VERSION "HNNBNNNYNNNNNNNNNNNNNNNNNNNNNNNNNNNNNNNNNN/4/%%%/4/'%**4NNN///"

NS_ :

BS_:

BU_: Aero_LB AFS_MLB Airbag_B8 BCM1_B8 Gateway_B8 Getriebe_AL551_651_B8 Getriebe_AL551_Q5_Hybrid Getriebe_SL_LB Lift_MLB_LB LWR_MLB Magnetic_Ride_LB Motor_MLB_AU48_AU416_Diesel Motor_MLB_B8_Q5_Otto Motor_MLB_Q5_Hybrid Niveau_LB Airbag_D4 BMS_Hybrid Daempfer_MLB EPB_MLB ESP Gateway Getriebe_AL551_951_D4_C7 Getriebe_AL551_Hybrid_D4_C7 Getriebe_DL382_MLB Getriebe_DL501_MLB Getriebe_VL381_MLB LEH_Hybrid LWS_D4 Motor2_MLB_D4_C7 Motor_MLB_AU64_AU57_Diesel Motor_MLB_BY_Otto Motor_MLB_C7_PHEV Motor_MLB_D4_C7_Hybrid Motor_MLB_D4_C7_Otto QSP SAK SAK2 SCR_MLB SCU

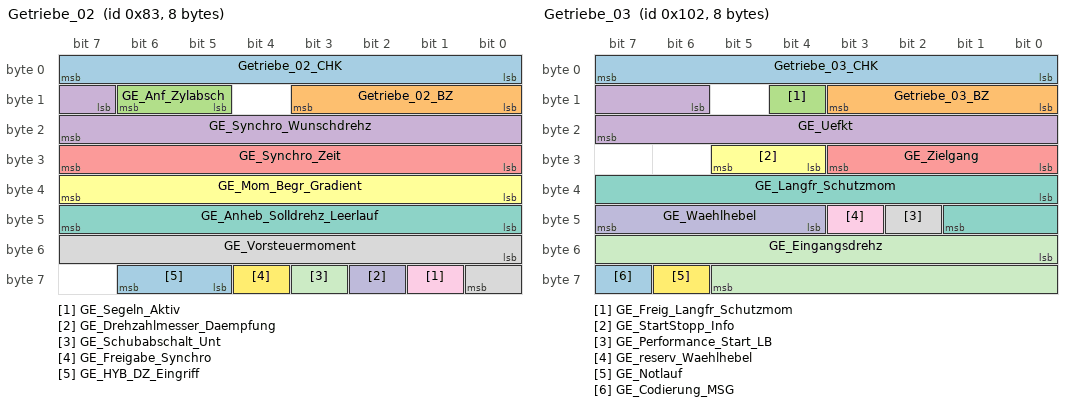
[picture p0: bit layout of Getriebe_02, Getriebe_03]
BO_ 131 Getriebe_02: 8 Getriebe_AL551_951_D4_C7
 SG_ Getriebe_02_CHK : 0|8@1+ (1,0) [0|255] ""  Motor_MLB_AU64_AU57_Diesel,Motor_MLB_BY_Otto,Motor_MLB_C7_PHEV,Motor_MLB_D4_C7_Hybrid,Motor_MLB_D4_C7_Otto
 SG_ Getriebe_02_BZ : 8|4@1+ (1,0) [0|15] ""  Motor_MLB_AU64_AU57_Diesel,Motor_MLB_BY_Otto,Motor_MLB_C7_PHEV,Motor_MLB_D4_C7_Hybrid,Motor_MLB_D4_C7_Otto
 SG_ GE_Anf_Zylabsch : 13|2@1+ (1,0) [0|3] ""  Motor_MLB_BY_Otto,Motor_MLB_C7_PHEV,Motor_MLB_D4_C7_Hybrid,Motor_MLB_D4_C7_Otto
 SG_ GE_Synchro_Wunschdrehz : 15|9@1+ (25,0) [25|12750] "Unit_MinutInver"  Motor_MLB_AU64_AU57_Diesel,Motor_MLB_BY_Otto,Motor_MLB_C7_PHEV,Motor_MLB_D4_C7_Hybrid,Motor_MLB_D4_C7_Otto
 SG_ GE_Synchro_Zeit : 24|8@1+ (20,0) [0|5080] "Unit_MilliSecon"  Motor_MLB_AU64_AU57_Diesel,Motor_MLB_BY_Otto,Motor_MLB_C7_PHEV,Motor_MLB_D4_C7_Hybrid,Motor_MLB_D4_C7_Otto
 SG_ GE_Mom_Begr_Gradient : 32|8@1+ (10,0) [0|2540] "Unit_NewtoMeterPerSecon"  Motor_MLB_AU64_AU57_Diesel,Motor_MLB_BY_Otto,Motor_MLB_C7_PHEV,Motor_MLB_D4_C7_Hybrid,Motor_MLB_D4_C7_Otto
 SG_ GE_Anheb_Solldrehz_Leerlauf : 40|8@1+ (10,0) [0|2540] "Unit_MinutInver"  Motor_MLB_AU64_AU57_Diesel,Motor_MLB_BY_Otto,Motor_MLB_C7_PHEV,Motor_MLB_D4_C7_Hybrid,Motor_MLB_D4_C7_Otto
 SG_ GE_Vorsteuermoment : 48|9@1+ (1,0) [0|509] ""  Motor_MLB_AU64_AU57_Diesel,Motor_MLB_BY_Otto,Motor_MLB_C7_PHEV,Motor_MLB_D4_C7_Hybrid,Motor_MLB_D4_C7_Otto
 SG_ GE_Segeln_Aktiv : 57|1@1+ (1,0) [0|1] ""  Gateway,Motor_MLB_AU64_AU57_Diesel,Motor_MLB_C7_PHEV,Motor_MLB_D4_C7_Hybrid,Motor_MLB_D4_C7_Otto
 SG_ GE_Drehzahlmesser_Daempfung : 58|1@1+ (1,0) [0|1] ""  Motor_MLB_AU64_AU57_Diesel,Motor_MLB_BY_Otto,Motor_MLB_C7_PHEV,Motor_MLB_D4_C7_Hybrid,Motor_MLB_D4_C7_Otto
 SG_ GE_Schubabschalt_Unt : 59|1@1+ (1,0) [0|1] ""  Motor_MLB_AU64_AU57_Diesel,Motor_MLB_BY_Otto,Motor_MLB_C7_PHEV,Motor_MLB_D4_C7_Hybrid,Motor_MLB_D4_C7_Otto
 SG_ GE_Freigabe_Synchro : 60|1@1+ (1,0) [0|1] ""  Motor_MLB_AU64_AU57_Diesel,Motor_MLB_BY_Otto,Motor_MLB_C7_PHEV,Motor_MLB_D4_C7_Hybrid,Motor_MLB_D4_C7_Otto
 SG_ GE_HYB_DZ_Eingriff : 61|2@1+ (1,0) [0|3] "" Vector__XXX

BO_ 258 Getriebe_03: 8 Getriebe_AL551_951_D4_C7
 SG_ Getriebe_03_CHK : 0|8@1+ (1,0) [0|255] ""  EPB_MLB,Gateway,Motor_MLB_AU64_AU57_Diesel,Motor_MLB_BY_Otto,Motor_MLB_C7_PHEV,Motor_MLB_D4_C7_Hybrid,Motor_MLB_D4_C7_Otto
 SG_ Getriebe_03_BZ : 8|4@1+ (1,0) [0|15] ""  EPB_MLB,Gateway,Motor_MLB_AU64_AU57_Diesel,Motor_MLB_BY_Otto,Motor_MLB_C7_PHEV,Motor_MLB_D4_C7_Hybrid,Motor_MLB_D4_C7_Otto
 SG_ GE_Freig_Langfr_Schutzmom : 12|1@1+ (1,0) [0|1] ""  Gateway,Motor_MLB_AU64_AU57_Diesel,Motor_MLB_BY_Otto,Motor_MLB_C7_PHEV,Motor_MLB_D4_C7_Hybrid,Motor_MLB_D4_C7_Otto
 SG_ GE_Uefkt : 14|10@1+ (0.1,0) [0|102.2] ""  EPB_MLB,Gateway,Motor_MLB_AU64_AU57_Diesel,Motor_MLB_BY_Otto,Motor_MLB_C7_PHEV,Motor_MLB_D4_C7_Hybrid,Motor_MLB_D4_C7_Otto
 SG_ GE_Zielgang : 24|4@1+ (1,0) [0|15] ""  Gateway,Motor_MLB_AU64_AU57_Diesel,Motor_MLB_BY_Otto,Motor_MLB_C7_PHEV,Motor_MLB_D4_C7_Hybrid,Motor_MLB_D4_C7_Otto
 SG_ GE_StartStopp_Info : 28|2@1+ (1,0) [0|3] ""  Gateway,Motor_MLB_AU64_AU57_Diesel,Motor_MLB_BY_Otto,Motor_MLB_C7_PHEV,Motor_MLB_D4_C7_Hybrid,Motor_MLB_D4_C7_Otto
 SG_ GE_Langfr_Schutzmom : 32|10@1+ (1,0) [0|1021] ""  Gateway,Motor_MLB_AU64_AU57_Diesel,Motor_MLB_BY_Otto,Motor_MLB_C7_PHEV,Motor_MLB_D4_C7_Hybrid,Motor_MLB_D4_C7_Otto
 SG_ GE_Performance_Start_LB : 42|1@1+ (1,0) [0|1] ""  Gateway
 SG_ GE_reserv_Waehlhebel : 43|1@1+ (1,0) [0|1] ""  Gateway
 SG_ GE_Waehlhebel : 44|4@1+ (1,0) [0|15] ""  EPB_MLB,Gateway,Motor_MLB_AU64_AU57_Diesel,Motor_MLB_BY_Otto,Motor_MLB_C7_PHEV,Motor_MLB_D4_C7_Hybrid,Motor_MLB_D4_C7_Otto
 SG_ GE_Eingangsdrehz : 48|14@1+ (1,0) [0|16381] "Unit_MinutInver"  Gateway,Motor_MLB_AU64_AU57_Diesel,Motor_MLB_BY_Otto,Motor_MLB_C7_PHEV,Motor_MLB_D4_C7_Hybrid,Motor_MLB_D4_C7_Otto
 SG_ GE_Notlauf : 62|1@1+ (1,0) [0|1] ""  Gateway,Motor_MLB_AU64_AU57_Diesel,Motor_MLB_BY_Otto,Motor_MLB_C7_PHEV,Motor_MLB_D4_C7_Hybrid,Motor_MLB_D4_C7_Otto
 SG_ GE_Codierung_MSG : 63|1@1+ (1,0) [0|1] ""  Gateway

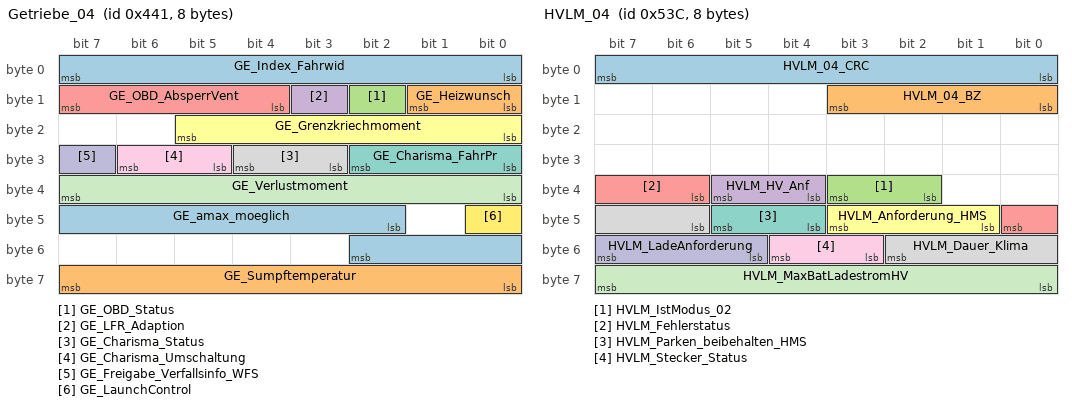
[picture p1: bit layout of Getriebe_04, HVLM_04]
BO_ 1089 Getriebe_04: 8 Getriebe_AL551_951_D4_C7
 SG_ GE_Index_Fahrwid : 0|8@1+ (0.249,-31.623) [-31.623|31.623] ""  Gateway,Motor_MLB_AU64_AU57_Diesel,Motor_MLB_BY_Otto,Motor_MLB_C7_PHEV,Motor_MLB_D4_C7_Hybrid,Motor_MLB_D4_C7_Otto
 SG_ GE_Heizwunsch : 8|2@1+ (1,0) [0|3] ""  Gateway
 SG_ GE_OBD_Status : 10|1@1+ (1,0) [0|1] ""  Gateway,Motor_MLB_AU64_AU57_Diesel,Motor_MLB_BY_Otto,Motor_MLB_C7_PHEV,Motor_MLB_D4_C7_Hybrid,Motor_MLB_D4_C7_Otto
 SG_ GE_LFR_Adaption : 11|1@1+ (1,0) [0|1] ""  Gateway,Motor_MLB_AU64_AU57_Diesel,Motor_MLB_BY_Otto,Motor_MLB_C7_PHEV,Motor_MLB_D4_C7_Hybrid,Motor_MLB_D4_C7_Otto
 SG_ GE_OBD_AbsperrVent : 12|4@1+ (1,0) [0|15] ""  Gateway
 SG_ GE_Grenzkriechmoment : 16|6@1+ (2,0) [0|122] ""  Gateway
 SG_ GE_Charisma_FahrPr : 24|3@1+ (1,0) [0|7] ""  Gateway
 SG_ GE_Charisma_Status : 27|2@1+ (1,0) [0|3] ""  Gateway
 SG_ GE_Charisma_Umschaltung : 29|2@1+ (1,0) [0|3] ""  Gateway
 SG_ GE_Freigabe_Verfallsinfo_WFS : 31|1@1+ (1,0) [0|1] ""  Gateway,Motor_MLB_AU64_AU57_Diesel,Motor_MLB_BY_Otto,Motor_MLB_C7_PHEV,Motor_MLB_D4_C7_Hybrid,Motor_MLB_D4_C7_Otto
 SG_ GE_Verlustmoment : 32|8@1+ (1,0) [0|254] ""  EPB_MLB,Gateway,Motor_MLB_AU64_AU57_Diesel,Motor_MLB_BY_Otto,Motor_MLB_C7_PHEV,Motor_MLB_D4_C7_Hybrid,Motor_MLB_D4_C7_Otto
 SG_ GE_LaunchControl : 40|1@1+ (1,0) [0|1] ""  Gateway
 SG_ GE_amax_moeglich : 42|9@1+ (0.024,-2.016) [-2.016|10.224] "Unit_MeterPerSeconSquar"  Gateway,Motor_MLB_AU64_AU57_Diesel,Motor_MLB_BY_Otto,Motor_MLB_C7_PHEV,Motor_MLB_D4_C7_Hybrid,Motor_MLB_D4_C7_Otto
 SG_ GE_Sumpftemperatur : 56|8@1+ (1,-58) [-58|196] "Unit_DegreCelsi"  Gateway,Motor_MLB_AU64_AU57_Diesel,Motor_MLB_BY_Otto,Motor_MLB_C7_PHEV,Motor_MLB_D4_C7_Hybrid,Motor_MLB_D4_C7_Otto

BO_ 1340 HVLM_04: 8 Gateway
 SG_ HVLM_04_CRC : 0|8@1+ (1,0) [0|255] ""  EPB_MLB
 SG_ HVLM_04_BZ : 8|4@1+ (1,0) [0|15] ""  EPB_MLB
 SG_ HVLM_IstModus_02 : 34|2@1+ (1,0) [0|3] "" Vector__XXX
 SG_ HVLM_HV_Anf : 36|2@1+ (1,0) [0|3] "" Vector__XXX
 SG_ HVLM_Fehlerstatus : 38|3@1+ (1,0) [0|7] "" Vector__XXX
 SG_ HVLM_Anforderung_HMS : 41|3@1+ (1,0) [0|7] ""  EPB_MLB
 SG_ HVLM_Parken_beibehalten_HMS : 44|2@1+ (1,0) [0|3] ""  EPB_MLB
 SG_ HVLM_Dauer_Klima : 46|5@1+ (1,0) [0|30] "Unit_Minut" Vector__XXX
 SG_ HVLM_Stecker_Status : 51|2@1+ (1,0) [0|3] "" Vector__XXX
 SG_ HVLM_LadeAnforderung : 53|3@1+ (1,0) [0|7] "" Vector__XXX
 SG_ HVLM_MaxBatLadestromHV : 56|8@1+ (1,0) [0|253] "Unit_Amper" Vector__XXX

BO_ 1811 ISO_ABS_Req: 8 Gateway
 SG_ ISO_ABS_Req_Data : 0|64@1+ (1,0) [0|1.84467440737096E+019] ""  ESP

BO_ 1917 ISO_ABS_Resp: 8 ESP
 SG_ ISO_ABS_Resp_Data : 0|64@1+ (1,0) [0|1.84467440737096E+019] ""  Gateway

BO_ 1892 ISO_AGA_Req: 8 Gateway
 SG_ ISO_AGA_Req_Data : 0|64@1+ (1,0) [0|1.84467440737096E+019] ""  SAK2

BO_ 1998 ISO_AGA_Resp: 8 SAK2
 SG_ ISO_AGA_Resp_Data : 0|64@1+ (1,0) [0|1.84467440737096E+019] ""  Gateway

BO_ 1813 ISO_Airbag_01_Req: 8 Gateway
 SG_ ISO_Airbag_01_Req_Data : 0|64@1+ (1,0) [0|1.84467440737096E+019] ""  Airbag_D4

BO_ 1919 ISO_Airbag_01_Resp: 8 Airbag_D4
 SG_ ISO_Airbag_01_Resp_Data : 0|64@1+ (1,0) [0|1.84467440737096E+019] ""  Gateway

BO_ 1874 ISO_EPB_Req: 8 Gateway
 SG_ ISO_EPB_Req_Data : 0|64@1+ (1,0) [0|1.84467440737096E+019] ""  EPB_MLB

BO_ 1980 ISO_EPB_Resp: 8 EPB_MLB
 SG_ ISO_EPB_Resp_Data : 0|64@1+ (1,0) [0|1.84467440737096E+019] ""  Gateway

BO_ 1795 ISO_Funktionaler_Req_Abgas: 8 Gateway
 SG_ ISO_Funktionaler_Req_Abgas : 0|64@1+ (1,0) [0|1.84467440737096E+019] ""  BMS_Hybrid,Getriebe_AL551_951_D4_C7,Getriebe_AL551_Hybrid_D4_C7,Getriebe_DL382_MLB,Getriebe_DL501_MLB,Getriebe_VL381_MLB,LEH_Hybrid,Motor2_MLB_D4_C7,Motor_MLB_AU64_AU57_Diesel,Motor_MLB_BY_Otto,Motor_MLB_C7_PHEV,Motor_MLB_D4_C7_Hybrid,Motor_MLB_D4_C7_Otto,SCR_MLB

BO_ 1792 ISO_Funktionaler_Req_All: 8 Gateway
 SG_ ISO_ALL_01_Req_Data : 0|64@1+ (1,0) [0|1.84467440737096E+019] ""  Airbag_D4,BMS_Hybrid,EPB_MLB,ESP,Getriebe_AL551_951_D4_C7,Getriebe_AL551_Hybrid_D4_C7,Getriebe_DL382_MLB,Getriebe_DL501_MLB,Getriebe_VL381_MLB,LEH_Hybrid,Motor2_MLB_D4_C7,Motor_MLB_AU64_AU57_Diesel,Motor_MLB_BY_Otto,Motor_MLB_C7_PHEV,Motor_MLB_D4_C7_Hybrid,Motor_MLB_D4_C7_Otto,SAK,SAK2,SCR_MLB,SCU

BO_ 2015 ISO_Funktionaler_Req_OBD: 8 Gateway
 SG_ ISO_OBD_Funktionaler_Req_Data : 0|64@1+ (1,0) [0|1.84467440737096E+019] ""  BMS_Hybrid,Getriebe_AL551_951_D4_C7,Getriebe_AL551_Hybrid_D4_C7,Getriebe_DL382_MLB,Getriebe_DL501_MLB,Getriebe_VL381_MLB,LEH_Hybrid,Motor2_MLB_D4_C7,Motor_MLB_AU64_AU57_Diesel,Motor_MLB_BY_Otto,Motor_MLB_C7_PHEV,Motor_MLB_D4_C7_Hybrid,Motor_MLB_D4_C7_Otto,SCR_MLB

BO_ 2017 ISO_Getriebe_01_Req: 8 Gateway
 SG_ ISO_Getriebe_01_Req_Data : 0|64@1+ (1,0) [0|1.84467440737096E+019] ""  Getriebe_AL551_951_D4_C7,Getriebe_AL551_Hybrid_D4_C7,Getriebe_DL382_MLB,Getriebe_DL501_MLB,Getriebe_VL381_MLB

BO_ 2025 ISO_Getriebe_01_Resp: 8 Getriebe_AL551_951_D4_C7
 SG_ ISO_Getriebe_01_Resp_Data : 0|64@1+ (1,0) [0|1.84467440737096E+019] ""  Gateway

BO_ 2016 ISO_MO_01_Req: 8 Gateway
 SG_ ISO_MO_01_Req_Data : 0|64@1+ (1,0) [0|1.84467440737096E+019] ""  Motor_MLB_AU64_AU57_Diesel,Motor_MLB_BY_Otto,Motor_MLB_C7_PHEV,Motor_MLB_D4_C7_Hybrid,Motor_MLB_D4_C7_Otto

BO_ 2024 ISO_MO_01_Resp: 8 Motor_MLB_AU64_AU57_Diesel
 SG_ ISO_MO_01_Resp_Data : 0|64@1+ (1,0) [0|1.84467440737096E+019] ""  Gateway

BO_ 2018 ISO_OBD_01_Req: 8 Gateway
 SG_ ISO_OBD_01_Req_Data : 0|64@1+ (1,0) [0|1.84467440737096E+019] ""  Motor2_MLB_D4_C7

BO_ 2026 ISO_OBD_01_Resp: 8 Motor2_MLB_D4_C7
 SG_ ISO_OBD_01_Resp_Data : 0|64@1+ (1,0) [0|1.84467440737096E+019] ""  Gateway

BO_ 2021 ISO_OBD_04_Req: 8 Gateway
 SG_ ISO_OBD_04_Req_Data : 0|64@1+ (1,0) [0|1.84467440737096E+019] ""  BMS_Hybrid

BO_ 2029 ISO_OBD_04_Resp: 8 BMS_Hybrid
 SG_ ISO_OBD_04_Resp_Data : 0|64@1+ (1,0) [0|1.84467440737096E+019] ""  Gateway

BO_ 2022 ISO_OBD_05_Req: 8 Gateway
 SG_ ISO_OBD_05_Req_Data : 0|64@1+ (1,0) [0|1.84467440737096E+019] ""  LEH_Hybrid

BO_ 2030 ISO_OBD_05_Resp: 8 LEH_Hybrid
 SG_ ISO_OBD_05_Resp_Data : 0|64@1+ (1,0) [0|1.84467440737096E+019] ""  Gateway

BO_ 1834 ISO_SCR_Req: 8 Gateway
 SG_ ISO_SCR_Req_Data : 0|64@1+ (1,0) [0|1.84467440737096E+019] ""  SCR_MLB

BO_ 1940 ISO_SCR_Resp: 8 SCR_MLB
 SG_ ISO_SCR_Resp_Data : 0|64@1+ (1,0) [0|1.84467440737096E+019] ""  Gateway

BO_ 1814 ISO_SCU_Req: 8 Gateway
 SG_ ISO_SCU_Req_Data : 0|64@1+ (1,0) [0|1.84467440737096E+019] ""  SCU

BO_ 1920 ISO_SCU_Resp: 8 SCU
 SG_ ISO_SCU_Resp_Data : 0|64@1+ (1,0) [0|1.84467440737096E+019] ""  Gateway

BO_ 1820 ISO_Soundaktor_Req: 8 Gateway
 SG_ ISO_Soundaktor_Req_Data : 0|64@1+ (1,0) [0|1.84467440737096E+019] ""  SAK

BO_ 1926 ISO_Soundaktor_Resp: 8 SAK
 SG_ ISO_Soundaktor_Resp_Data : 0|64@1+ (1,0) [0|1.84467440737096E+019] ""  Gateway

BO_ 1875 ISO_Waehlhebel_Req: 8 Gateway
 SG_ ISO_Waehlhebel_Req_Data : 0|64@1+ (1,0) [0|1.84467440737096E+019] ""  Getriebe_AL551_951_D4_C7,Getriebe_AL551_Hybrid_D4_C7

BO_ 1981 ISO_Waehlhebel_Resp: 8 Getriebe_AL551_951_D4_C7
 SG_ ISO_Waehlhebel_Resp_Data : 0|64@1+ (1,0) [0|1.84467440737096E+019] ""  Gateway

BO_ 1424 Kessy_02: 8 Gateway
 SG_ KY_Funkschl_Nr : 0|4@1+ (1,0) [0|15] "" Vector__XXX
 SG_ KY_ID_Geb_autorisiert : 4|1@1+ (1,0) [0|1] "" Vector__XXX
 SG_ KY_ID_Geb_steckt : 5|1@1+ (1,0) [0|1] "" Vector__XXX
 SG_ KY_FFB_Frequenz : 6|2@1+ (1,0) [0|3] "" Vector__XXX
 SG_ KY_HF_Aktiv : 8|1@1+ (1,0) [0|1] "" Vector__XXX
 SG_ KY_LF_Aktiv : 9|1@1+ (1,0) [0|1] "" Vector__XXX
 SG_ KY_ELV_verr : 10|1@1+ (1,0) [0|1] ""  EPB_MLB
 SG_ KY_ELV_entr : 11|1@1+ (1,0) [0|1] "" Vector__XXX
 SG_ KY_ELV_enable_Anforderung : 12|1@1+ (1,0) [0|1] "" Vector__XXX
 SG_ KY_Valet_Parking : 14|1@1+ (1,0) [0|1] "" Vector__XXX
 SG_ KY_Keyless_Verbau : 15|1@1+ (1,0) [0|1] "" Vector__XXX
 SG_ KY_FBS_Fahrer_Hinweise : 16|3@1+ (1,0) [0|7] "" Vector__XXX
 SG_ FBS_Warn_Lenkung_def : 19|1@1+ (1,0) [0|1] "" Vector__XXX
 SG_ FBS_Warn_LenkVerriegelung_def : 20|1@1+ (1,0) [0|1] "" Vector__XXX
 SG_ FBS_Warn_Schluessel_Batt : 21|1@1+ (1,0) [0|1] "" Vector__XXX
 SG_ FBS_Prio_Warn_04 : 22|1@1+ (1,0) [0|1] "" Vector__XXX
 SG_ FBS_Prio_Warn_05 : 23|1@1+ (1,0) [0|1] "" Vector__XXX
 SG_ KY_KYL_Fahrer_Hinweise : 24|3@1+ (1,0) [0|7] "" Vector__XXX
 SG_ KYL_Warn_kein_Schluessel : 27|1@1+ (1,0) [0|1] "" Vector__XXX
 SG_ KYL_Warn_Kessy_defekt : 28|1@1+ (1,0) [0|1] "" Vector__XXX
 SG_ KY_KYL_Prio_Warn_03 : 29|1@1+ (1,0) [0|1] "" Vector__XXX
 SG_ KY_KYL_Prio_Warn_04 : 30|1@1+ (1,0) [0|1] "" Vector__XXX
 SG_ KY_KYL_Prio_Warn_05 : 31|1@1+ (1,0) [0|1] "" Vector__XXX
 SG_ KY_Schluessel_Soll : 32|4@1+ (1,0) [0|15] "" Vector__XXX
 SG_ KY_Schluessel_Ist : 36|4@1+ (1,0) [0|15] "" Vector__XXX
 SG_ KY_WFS_Safe : 40|1@1+ (1,0) [0|1] "" Vector__XXX
 SG_ KY_WFS_LZ : 41|2@1+ (1,0) [0|3] "" Vector__XXX
 SG_ KY_StartStopp_Info : 43|2@1+ (1,0) [0|3] ""  Motor_MLB_AU64_AU57_Diesel,Motor_MLB_BY_Otto,Motor_MLB_C7_PHEV,Motor_MLB_D4_C7_Hybrid,Motor_MLB_D4_C7_Otto
 SG_ KYL_Notzuendschloss : 45|1@1+ (1,0) [0|1] "" Vector__XXX
 SG_ KYL_Warn_Notzuendschloss : 46|1@1+ (1,0) [0|1] "" Vector__XXX
 SG_ FBS_KD_Fehler : 47|1@1+ (1,0) [0|1] "" Vector__XXX
 SG_ SK_Anf_DTC_Abfrage : 48|1@1+ (1,0) [0|1] "" Vector__XXX
 SG_ SK_Anf_DTC_Abfrage_sofort : 49|1@1+ (1,0) [0|1] "" Vector__XXX

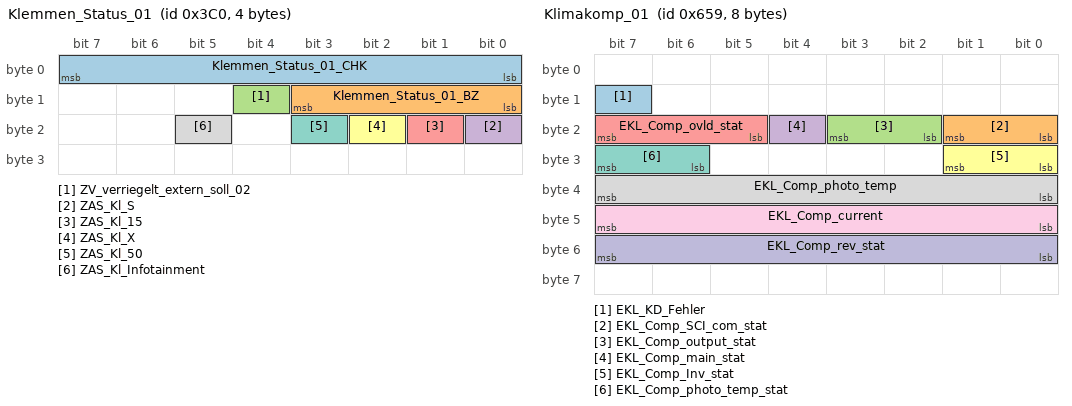
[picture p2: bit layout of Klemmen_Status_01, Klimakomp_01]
BO_ 960 Klemmen_Status_01: 4 Gateway
 SG_ Klemmen_Status_01_CHK : 0|8@1+ (1,0) [0|255] ""  Airbag_D4,BMS_Hybrid,EPB_MLB,Getriebe_AL551_951_D4_C7,Getriebe_AL551_Hybrid_D4_C7,LEH_Hybrid,Motor_MLB_AU64_AU57_Diesel,Motor_MLB_BY_Otto,Motor_MLB_C7_PHEV,Motor_MLB_D4_C7_Hybrid,Motor_MLB_D4_C7_Otto
 SG_ Klemmen_Status_01_BZ : 8|4@1+ (1,0) [0|15] ""  Airbag_D4,BMS_Hybrid,EPB_MLB,Getriebe_AL551_951_D4_C7,Getriebe_AL551_Hybrid_D4_C7,LEH_Hybrid,Motor_MLB_AU64_AU57_Diesel,Motor_MLB_BY_Otto,Motor_MLB_C7_PHEV,Motor_MLB_D4_C7_Hybrid,Motor_MLB_D4_C7_Otto
 SG_ ZV_verriegelt_extern_soll_02 : 12|1@1+ (1,0) [0|1] "" Vector__XXX
 SG_ ZAS_Kl_S : 16|1@1+ (1,0) [0|1] ""  EPB_MLB,Getriebe_AL551_951_D4_C7,Getriebe_AL551_Hybrid_D4_C7
 SG_ ZAS_Kl_15 : 17|1@1+ (1,0) [0|1] ""  Airbag_D4,BMS_Hybrid,EPB_MLB,Getriebe_AL551_951_D4_C7,Getriebe_AL551_Hybrid_D4_C7,Getriebe_DL382_MLB,Getriebe_DL501_MLB,LEH_Hybrid,Motor_MLB_AU64_AU57_Diesel,Motor_MLB_BY_Otto,Motor_MLB_C7_PHEV,Motor_MLB_D4_C7_Hybrid,Motor_MLB_D4_C7_Otto,SAK,SAK2,SCR_MLB,SCU
 SG_ ZAS_Kl_X : 18|1@1+ (1,0) [0|1] ""  EPB_MLB,SCU
 SG_ ZAS_Kl_50 : 19|1@1+ (1,0) [0|1] ""  EPB_MLB,Motor_MLB_AU64_AU57_Diesel,Motor_MLB_BY_Otto,Motor_MLB_C7_PHEV,Motor_MLB_D4_C7_Hybrid,Motor_MLB_D4_C7_Otto
 SG_ ZAS_Kl_Infotainment : 21|1@1+ (1,0) [0|1] "" Vector__XXX

BO_ 959 Klima_01: 8 Gateway
 SG_ KL_Drehz_Anh : 0|1@1+ (1,0) [0|1] ""  Motor_MLB_AU64_AU57_Diesel,Motor_MLB_BY_Otto,Motor_MLB_C7_PHEV,Motor_MLB_D4_C7_Hybrid,Motor_MLB_D4_C7_Otto
 SG_ KL_Vorwarn_Komp_ein : 1|1@1+ (1,0) [0|1] ""  Motor_MLB_AU64_AU57_Diesel,Motor_MLB_BY_Otto,Motor_MLB_C7_PHEV,Motor_MLB_D4_C7_Hybrid,Motor_MLB_D4_C7_Otto
 SG_ KL_Handshake_BEM : 2|1@1+ (1,0) [0|1] "" Vector__XXX
 SG_ KL_Komp_Moment_alt : 3|1@1+ (1,0) [0|1] "" Vector__XXX
 SG_ KL_Vorwarn_HHS_ein : 4|1@1+ (1,0) [0|1] ""  Motor_MLB_AU64_AU57_Diesel,Motor_MLB_BY_Otto,Motor_MLB_C7_PHEV,Motor_MLB_D4_C7_Hybrid,Motor_MLB_D4_C7_Otto
 SG_ KL_Vorwarn_HFS_ein : 5|1@1+ (1,0) [0|1] ""  Motor_MLB_AU64_AU57_Diesel,Motor_MLB_BY_Otto,Motor_MLB_C7_PHEV,Motor_MLB_D4_C7_Hybrid,Motor_MLB_D4_C7_Otto
 SG_ KL_Vorwarn_Zuheizer_ein : 6|1@1+ (1,0) [0|1] "" Vector__XXX
 SG_ KL_KD_Fehler : 7|1@1+ (1,0) [0|1] "" Vector__XXX
 SG_ KL_Comp_rev_rq : 8|8@1+ (50,0) [0|8600] "Unit_MinutInver" Vector__XXX
 SG_ KL_Charisma_FahrPr : 16|3@1+ (1,0) [0|7] "" Vector__XXX
 SG_ KL_Charisma_Status : 19|2@1+ (1,0) [0|3] "" Vector__XXX
 SG_ KL_Charisma_Umschaltung : 21|2@1+ (1,0) [0|3] "" Vector__XXX
 SG_ KL_Last_Kompr : 24|8@1+ (0.25,0) [0|63.5] "Unit_NewtoMeter"  Motor_MLB_AU64_AU57_Diesel,Motor_MLB_BY_Otto,Motor_MLB_C7_PHEV,Motor_MLB_D4_C7_Hybrid,Motor_MLB_D4_C7_Otto
 SG_ KL_Leistung_Hzg_Soll : 32|8@1+ (11,0) [0|2805] "Unit_Watt" Vector__XXX
 SG_ KL_Anf_KL : 40|8@1+ (0.4,0) [0|101.6] "Unit_PerCent"  Motor_MLB_AU64_AU57_Diesel,Motor_MLB_BY_Otto,Motor_MLB_C7_PHEV,Motor_MLB_D4_C7_Hybrid,Motor_MLB_D4_C7_Otto
 SG_ KL_4_Zonen : 48|1@1+ (1,0) [0|1] ""  Motor_MLB_AU64_AU57_Diesel,Motor_MLB_BY_Otto,Motor_MLB_C7_PHEV,Motor_MLB_D4_C7_Hybrid,Motor_MLB_D4_C7_Otto
 SG_ KL_AC_Schalter : 49|1@1+ (1,0) [0|1] ""  Getriebe_AL551_951_D4_C7,Getriebe_AL551_Hybrid_D4_C7
 SG_ KL_Zustand : 50|1@1+ (1,0) [0|1] ""  Getriebe_AL551_951_D4_C7,Getriebe_AL551_Hybrid_D4_C7,Getriebe_DL382_MLB,Getriebe_DL501_MLB,Motor_MLB_AU64_AU57_Diesel,Motor_MLB_BY_Otto,Motor_MLB_C7_PHEV,Motor_MLB_D4_C7_Hybrid,Motor_MLB_D4_C7_Otto
 SG_ KL_Thermomanagement : 51|2@1+ (1,0) [0|3] ""  Motor_MLB_AU64_AU57_Diesel,Motor_MLB_BY_Otto,Motor_MLB_C7_PHEV,Motor_MLB_D4_C7_Hybrid,Motor_MLB_D4_C7_Otto
 SG_ KL_Comp_enable : 53|1@1+ (1,0) [0|1] "" Vector__XXX
 SG_ KL_StartStopp_Info : 54|2@1+ (1,0) [0|3] ""  Motor_MLB_AU64_AU57_Diesel,Motor_MLB_BY_Otto,Motor_MLB_C7_PHEV,Motor_MLB_D4_C7_Hybrid,Motor_MLB_D4_C7_Otto
 SG_ KL_el_Zuheizer_Stufe : 56|3@1+ (1,0) [0|7] ""  Motor_MLB_AU64_AU57_Diesel
 SG_ KL_Diag_Absperrvent : 59|4@1+ (1,0) [0|15] "" Vector__XXX
 SG_ KL_nachtr_Stopp_Anf : 63|1@1+ (1,0) [0|1] ""  Motor_MLB_AU64_AU57_Diesel,Motor_MLB_BY_Otto,Motor_MLB_C7_PHEV,Motor_MLB_D4_C7_Hybrid,Motor_MLB_D4_C7_Otto

BO_ 1636 Klima_02: 8 Gateway
 SG_ KL_Stromsparmodus : 0|1@1+ (1,0) [0|1] "" Vector__XXX
 SG_ KL_Spg_Hzg_aus : 1|1@1+ (1,0) [0|1] "" Vector__XXX
 SG_ KL_AQS_Empfindlichkeit : 2|3@1+ (1,0) [0|7] "" Vector__XXX
 SG_ KL_SIH_Soll_li : 8|3@1+ (1,0) [0|7] "" Vector__XXX
 SG_ KL_SIH_Takt_li : 11|1@1+ (1,0) [0|1] "" Vector__XXX
 SG_ KL_SIL_Soll_li : 12|3@1+ (1,0) [0|7] "" Vector__XXX
 SG_ KL_LRH_aus : 15|1@1+ (1,0) [0|1] "" Vector__XXX
 SG_ KL_SIH_Soll_re : 16|3@1+ (1,0) [0|7] "" Vector__XXX
 SG_ KL_SIH_Takt_re : 19|1@1+ (1,0) [0|1] "" Vector__XXX
 SG_ KL_SIL_Soll_re : 20|3@1+ (1,0) [0|7] "" Vector__XXX
 SG_ KL_Beschlagsgefahr : 23|1@1+ (1,0) [0|1] "" Vector__XXX
 SG_ KL_HSH_ein_Soll : 24|1@1+ (1,0) [0|1] "" Vector__XXX
 SG_ KL_HSH_Taktung : 25|1@1+ (1,0) [0|1] "" Vector__XXX
 SG_ KL_Zuheizer_Freigabe : 26|1@1+ (1,0) [0|1] "" Vector__XXX
 SG_ KL_ZHE_Status : 27|1@1+ (1,0) [0|1] "" Vector__XXX
 SG_ KL_FSH_Status : 28|2@1+ (1,0) [0|3] "" Vector__XXX
 SG_ KL_LRH_on_off : 30|1@1+ (1,0) [0|1] "" Vector__XXX
 SG_ KL_Umluftklappe_Status : 32|4@1+ (1,0) [0|15] "" Vector__XXX
 SG_ KL_Geblaese_Status : 36|4@1+ (1,0) [0|15] ""  BMS_Hybrid
 SG_ KL_I_Geblaese : 40|8@1+ (0.25,0) [0|63.5] "Unit_Amper" Vector__XXX
 SG_ KL_Kompressorstrom_soll : 48|10@1+ (1,0) [0|1021] "" Vector__XXX
 SG_ KL_FSH_P_Soll : 58|6@1+ (20,0) [0|1240] "Unit_Watt" Vector__XXX

BO_ 1646 Klima_03: 7 Gateway
 SG_ KL_STL_aktiv : 0|1@1+ (1,0) [0|1] "" Vector__XXX
 SG_ KL_STH_aktiv : 1|1@1+ (1,0) [0|1] "" Vector__XXX
 SG_ KL_Solarluefter_aktiv : 2|1@1+ (1,0) [0|1] "" Vector__XXX
 SG_ KL_Umluft_Taste : 3|1@1+ (1,0) [0|1] "" Vector__XXX
 SG_ KL_Geblaese_Fond_Status : 4|4@1+ (1,0) [0|15] "" Vector__XXX
 SG_ KL_STH_Ansteuerung : 8|2@1+ (1,0) [0|3] "" Vector__XXX
 SG_ KL_STH_Betriebsdauer : 10|6@1+ (1,0) [0|60] "Unit_Minut" Vector__XXX
 SG_ KL_Magnetventil : 16|1@1+ (1,0) [0|1] "" Vector__XXX
 SG_ KL_WaPu : 17|1@1+ (1,0) [0|1] "" Vector__XXX
 SG_ KL_Freigabe_KRH_li : 18|3@1+ (1,0) [0|7] "" Vector__XXX
 SG_ KL_Freigabe_KRH_re : 21|3@1+ (1,0) [0|7] "" Vector__XXX
 SG_ KL_BCmE_Livetip_Freigabe : 24|1@1+ (1,0) [0|1] "" Vector__XXX
 SG_ KL_HYB_ASV_hinten_schliessen_Anf : 25|1@1+ (1,0) [0|1] ""  BMS_Hybrid
 SG_ KL_HYB_ASV_vorne_schliessen_Anf : 26|1@1+ (1,0) [0|1] ""  BMS_Hybrid
 SG_ KL_HYB_Spuelbetrieb_Freigabe : 27|1@1+ (1,0) [0|1] ""  BMS_Hybrid
 SG_ KL_Fehler_ElWaPu : 28|1@1+ (1,0) [0|1] ""  Motor_MLB_AU64_AU57_Diesel,Motor_MLB_BY_Otto,Motor_MLB_C7_PHEV,Motor_MLB_D4_C7_Hybrid,Motor_MLB_D4_C7_Otto
 SG_ KL_Innen_Temp : 32|8@1+ (0.5,-50) [-50|76] "Unit_DegreCelsi"  BMS_Hybrid
 SG_ KL_Sonnenintensitaet : 40|8@1+ (10,0) [0|1000] "Unit_WattPerMeterSquar" Vector__XXX
 SG_ KL_AussenTemp_WK : 48|8@1+ (0.5,-50) [-50|76] "Unit_DegreCelsi" Vector__XXX

BO_ 1625 Klimakomp_01: 8 Gateway
 SG_ EKL_KD_Fehler : 15|1@1+ (1,0) [0|1] "" Vector__XXX
 SG_ EKL_Comp_SCI_com_stat : 16|2@1+ (1,0) [0|3] "" Vector__XXX
 SG_ EKL_Comp_output_stat : 18|2@1+ (1,0) [0|3] "" Vector__XXX
 SG_ EKL_Comp_main_stat : 20|1@1+ (1,0) [0|1] "" Vector__XXX
 SG_ EKL_Comp_ovld_stat : 21|3@1+ (1,0) [0|7] "" Vector__XXX
 SG_ EKL_Comp_Inv_stat : 24|2@1+ (1,0) [0|3] "" Vector__XXX
 SG_ EKL_Comp_photo_temp_stat : 30|2@1+ (1,0) [0|3] "" Vector__XXX
 SG_ EKL_Comp_photo_temp : 32|8@1+ (1,0) [0|254] "Unit_DegreCelsi" Vector__XXX
 SG_ EKL_Comp_current : 40|8@1+ (0.1,0) [0|25.4] "Unit_Amper"  Motor_MLB_C7_PHEV,Motor_MLB_D4_C7_Hybrid
 SG_ EKL_Comp_rev_stat : 48|8@1+ (50,0) [0|8600] "Unit_MinutInver" Vector__XXX

BO_ 779 Kombi_01: 8 Gateway
 SG_ KBI_ABS_Lampe : 0|1@1+ (1,0) [0|1] ""  Getriebe_AL551_951_D4_C7,Getriebe_AL551_Hybrid_D4_C7
 SG_ KBI_ESP_Lampe : 1|1@1+ (1,0) [0|1] ""  Getriebe_AL551_951_D4_C7,Getriebe_AL551_Hybrid_D4_C7
 SG_ KBI_BKL_Lampe : 2|1@1+ (1,0) [0|1] ""  Getriebe_AL551_951_D4_C7,Getriebe_AL551_Hybrid_D4_C7
 SG_ KBI_Airbag_Lampe : 3|1@1+ (1,0) [0|1] ""  Getriebe_AL551_951_D4_C7,Getriebe_AL551_Hybrid_D4_C7
 SG_ KBI_SILA_gueltig : 4|1@1+ (1,0) [0|1] ""  Getriebe_AL551_951_D4_C7,Getriebe_AL551_Hybrid_D4_C7
 SG_ KBI_Lenkung_Lampe : 5|1@1+ (1,0) [0|1] ""  Getriebe_AL551_951_D4_C7,Getriebe_AL551_Hybrid_D4_C7
 SG_ KBI_Vorglueh_System_Lampe : 6|1@1+ (1,0) [0|1] ""  Getriebe_AL551_951_D4_C7,Getriebe_AL551_Hybrid_D4_C7,Motor_MLB_AU64_AU57_Diesel
 SG_ KBI_NV_in_Anzeige : 7|1@1+ (1,0) [0|1] ""  Getriebe_AL551_951_D4_C7,Getriebe_AL551_Hybrid_D4_C7
 SG_ Kombi_01_BZ : 8|4@1+ (1,0) [0|15] ""  Getriebe_AL551_951_D4_C7,Getriebe_AL551_Hybrid_D4_C7
 SG_ KBI_Anzeigestatus_ACC : 12|1@1+ (1,0) [0|1] ""  Getriebe_AL551_951_D4_C7,Getriebe_AL551_Hybrid_D4_C7
 SG_ KBI_Oeldruck_Schalter : 15|1@1+ (1,0) [0|1] ""  Getriebe_AL551_951_D4_C7,Getriebe_AL551_Hybrid_D4_C7
 SG_ KBI_Tankwarnung : 16|1@1+ (1,0) [0|1] ""  Getriebe_AL551_951_D4_C7,Getriebe_AL551_Hybrid_D4_C7,Motor_MLB_AU64_AU57_Diesel,Motor_MLB_BY_Otto,Motor_MLB_C7_PHEV,Motor_MLB_D4_C7_Hybrid,Motor_MLB_D4_C7_Otto
 SG_ KBI_MFA_v_Einheit_01 : 17|1@1+ (1,0) [0|1] ""  Getriebe_AL551_951_D4_C7,Getriebe_AL551_Hybrid_D4_C7,Motor_MLB_AU64_AU57_Diesel,Motor_MLB_BY_Otto,Motor_MLB_C7_PHEV,Motor_MLB_D4_C7_Hybrid,Motor_MLB_D4_C7_Otto
 SG_ KBI_im_Stellgliedtest : 18|1@1+ (1,0) [0|1] ""  Getriebe_AL551_951_D4_C7,Getriebe_AL551_Hybrid_D4_C7
 SG_ KBI_Anzeigefehler_LDW : 19|2@1+ (1,0) [0|3] ""  Getriebe_AL551_951_D4_C7,Getriebe_AL551_Hybrid_D4_C7
 SG_ KBI_Variante_USA : 21|1@1+ (1,0) [0|1] ""  Getriebe_AL551_951_D4_C7,Getriebe_AL551_Hybrid_D4_C7
 SG_ KBI_Oeldruckwarnung : 22|1@1+ (1,0) [0|1] ""  Getriebe_AL551_951_D4_C7,Getriebe_AL551_Hybrid_D4_C7
 SG_ KBI_Handbremse : 23|1@1+ (1,0) [0|1] ""  Getriebe_AL551_951_D4_C7,Getriebe_AL551_Hybrid_D4_C7
 SG_ KBI_V_Digital : 24|9@1+ (1,0) [0|511] ""  Getriebe_AL551_951_D4_C7,Getriebe_AL551_Hybrid_D4_C7
 SG_ KBI_PLA_in_Anzeige : 33|1@1+ (1,0) [0|1] ""  Getriebe_AL551_951_D4_C7,Getriebe_AL551_Hybrid_D4_C7
 SG_ KBI_Anzeigefehler_NV : 34|1@1+ (1,0) [0|1] ""  Getriebe_AL551_951_D4_C7,Getriebe_AL551_Hybrid_D4_C7
 SG_ KBI_angez_Geschw : 48|10@1+ (0.32,0) [0|325.12] "Unit_KiloMeterPerHour"  Airbag_D4,Getriebe_AL551_951_D4_C7,Getriebe_AL551_Hybrid_D4_C7,Getriebe_DL382_MLB,Getriebe_DL501_MLB,Getriebe_VL381_MLB,Motor_MLB_AU64_AU57_Diesel,Motor_MLB_BY_Otto,Motor_MLB_C7_PHEV,Motor_MLB_D4_C7_Hybrid,Motor_MLB_D4_C7_Otto
 SG_ KBI_Einheit_Tacho : 58|1@1+ (1,0) [0|1] ""  Getriebe_AL551_951_D4_C7,Getriebe_AL551_Hybrid_D4_C7,Motor_MLB_AU64_AU57_Diesel,Motor_MLB_BY_Otto,Motor_MLB_C7_PHEV,Motor_MLB_D4_C7_Hybrid,Motor_MLB_D4_C7_Otto
 SG_ KBI_Konsistenz_ACC : 59|1@1+ (1,0) [0|1] ""  Getriebe_AL551_951_D4_C7,Getriebe_AL551_Hybrid_D4_C7
 SG_ KBI_Fehler_Anzeige_ACC : 60|1@1+ (1,0) [0|1] ""  Getriebe_AL551_951_D4_C7,Getriebe_AL551_Hybrid_D4_C7
 SG_ KBI_Anzeigefehler_SWA : 61|2@1+ (1,0) [0|3] ""  Getriebe_AL551_951_D4_C7,Getriebe_AL551_Hybrid_D4_C7
 SG_ KBI_KD_Fehler : 63|1@1+ (1,0) [0|1] ""  Getriebe_AL551_951_D4_C7,Getriebe_AL551_Hybrid_D4_C7

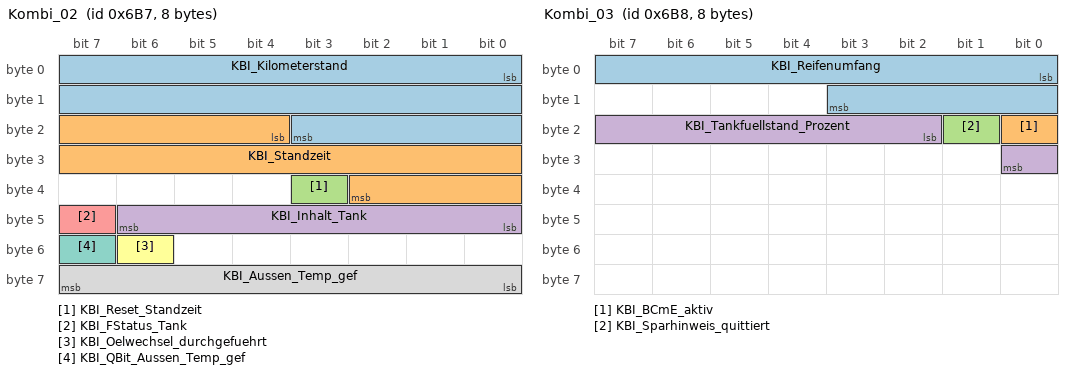
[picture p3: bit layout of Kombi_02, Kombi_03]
BO_ 1719 Kombi_02: 8 Gateway
 SG_ KBI_Kilometerstand : 0|20@1+ (1,0) [0|1048573] "Unit_KiloMeter" Vector__XXX
 SG_ KBI_Standzeit : 20|15@1+ (4,0) [0|131068] "Unit_Secon"  Getriebe_AL551_951_D4_C7,Getriebe_AL551_Hybrid_D4_C7,Getriebe_DL382_MLB,Getriebe_DL501_MLB,Getriebe_VL381_MLB,Motor_MLB_AU64_AU57_Diesel,Motor_MLB_BY_Otto,Motor_MLB_C7_PHEV,Motor_MLB_D4_C7_Hybrid,Motor_MLB_D4_C7_Otto
 SG_ KBI_Reset_Standzeit : 35|1@1+ (1,0) [0|1] ""  Getriebe_AL551_951_D4_C7,Getriebe_AL551_Hybrid_D4_C7,Getriebe_DL382_MLB,Getriebe_DL501_MLB,Getriebe_VL381_MLB,Motor_MLB_AU64_AU57_Diesel,Motor_MLB_BY_Otto,Motor_MLB_C7_PHEV,Motor_MLB_D4_C7_Hybrid,Motor_MLB_D4_C7_Otto
 SG_ KBI_Inhalt_Tank : 40|7@1+ (1,0) [0|126] "Unit_Liter"  Motor_MLB_AU64_AU57_Diesel,Motor_MLB_BY_Otto,Motor_MLB_C7_PHEV,Motor_MLB_D4_C7_Hybrid,Motor_MLB_D4_C7_Otto
 SG_ KBI_FStatus_Tank : 47|1@1+ (1,0) [0|1] ""  Motor_MLB_AU64_AU57_Diesel,Motor_MLB_BY_Otto,Motor_MLB_C7_PHEV,Motor_MLB_D4_C7_Hybrid,Motor_MLB_D4_C7_Otto
 SG_ KBI_Oelwechsel_durchgefuehrt : 54|1@1+ (1,0) [0|1] ""  Motor_MLB_BY_Otto,Motor_MLB_C7_PHEV,Motor_MLB_D4_C7_Hybrid,Motor_MLB_D4_C7_Otto
 SG_ KBI_QBit_Aussen_Temp_gef : 55|1@1+ (1,0) [0|1] ""  EPB_MLB,Getriebe_AL551_951_D4_C7,Getriebe_AL551_Hybrid_D4_C7,Getriebe_DL382_MLB,Getriebe_DL501_MLB,Getriebe_VL381_MLB,Motor_MLB_AU64_AU57_Diesel,Motor_MLB_BY_Otto,Motor_MLB_C7_PHEV,Motor_MLB_D4_C7_Hybrid,Motor_MLB_D4_C7_Otto
 SG_ KBI_Aussen_Temp_gef : 56|8@1+ (0.5,-50) [-50|75] "Unit_DegreCelsi"  EPB_MLB,Getriebe_AL551_951_D4_C7,Getriebe_AL551_Hybrid_D4_C7,Getriebe_DL382_MLB,Getriebe_DL501_MLB,Getriebe_VL381_MLB,Motor_MLB_AU64_AU57_Diesel,Motor_MLB_BY_Otto,Motor_MLB_C7_PHEV,Motor_MLB_D4_C7_Hybrid,Motor_MLB_D4_C7_Otto,SCR_MLB

BO_ 1720 Kombi_03: 8 Gateway
 SG_ KBI_Reifenumfang : 0|12@1+ (1,0) [0|4095] "Unit_MilliMeter"  Getriebe_AL551_951_D4_C7,Getriebe_AL551_Hybrid_D4_C7,Getriebe_DL382_MLB,Getriebe_DL501_MLB,Getriebe_VL381_MLB
 SG_ KBI_BCmE_aktiv : 16|1@1+ (1,0) [0|1] "" Vector__XXX
 SG_ KBI_Sparhinweis_quittiert : 17|1@1+ (1,0) [0|1] "" Vector__XXX
 SG_ KBI_Tankfuellstand_Prozent : 18|7@1+ (1,0) [0|100] "Unit_PerCent"  Motor_MLB_AU64_AU57_Diesel,Motor_MLB_BY_Otto,Motor_MLB_C7_PHEV,Motor_MLB_D4_C7_Hybrid,Motor_MLB_D4_C7_Otto

BO_ 517 KS_Airbag: 8 Airbag_D4
 SG_ KS_Airbag_Data : 0|64@1+ (1,0) [0|1.84467440737096E+019] ""  Gateway

BO_ 640 KS_Master: 8 Gateway
 SG_ KS_Master_Data : 0|64@1+ (1,0) [0|1.84467440737096E+019] ""  Airbag_D4

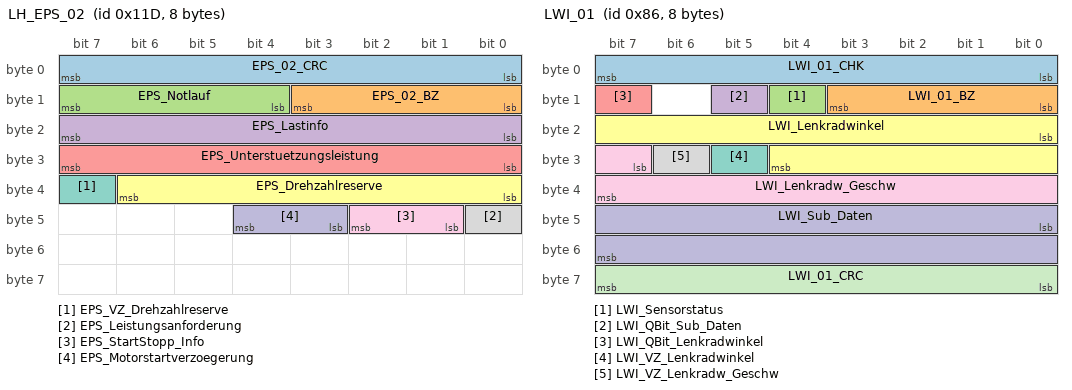
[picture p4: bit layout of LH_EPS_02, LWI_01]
BO_ 285 LH_EPS_02: 8 Gateway
 SG_ EPS_02_CRC : 0|8@1+ (1,0) [0|255] ""  SCU
 SG_ EPS_02_BZ : 8|4@1+ (1,0) [0|15] ""  SCU
 SG_ EPS_Notlauf : 12|4@1+ (1,0) [0|15] "" Vector__XXX
 SG_ EPS_Lastinfo : 16|8@1+ (1,0) [0|253] "Unit_Amper" Vector__XXX
 SG_ EPS_Unterstuetzungsleistung : 24|8@1+ (0.5,0) [0|100] "Unit_PerCent"  SCU
 SG_ EPS_Drehzahlreserve : 32|7@1+ (10,0) [0|1000] "Unit_DegreOfArcPerSecon"  SCU
 SG_ EPS_VZ_Drehzahlreserve : 39|1@1+ (1,0) [0|1] ""  SCU
 SG_ EPS_Leistungsanforderung : 40|1@1+ (1,0) [0|1] "" Vector__XXX
 SG_ EPS_StartStopp_Info : 41|2@1+ (1,0) [0|3] ""  Motor_MLB_AU64_AU57_Diesel,Motor_MLB_BY_Otto,Motor_MLB_C7_PHEV,Motor_MLB_D4_C7_Hybrid,Motor_MLB_D4_C7_Otto
 SG_ EPS_Motorstartverzoegerung : 43|2@1+ (1,0) [0|3] "" Vector__XXX

BO_ 1137 Licht_hinten_01: 8 Gateway
 SG_ Licht_hinten_01_BZ : 0|4@1+ (1,0) [0|15] ""  Motor_MLB_AU64_AU57_Diesel,Motor_MLB_BY_Otto,Motor_MLB_C7_PHEV,Motor_MLB_D4_C7_Hybrid,Motor_MLB_D4_C7_Otto
 SG_ BCM2_Bremsl_durch_ECD : 5|1@1+ (1,0) [0|1] ""  Motor_MLB_AU64_AU57_Diesel,Motor_MLB_BY_Otto,Motor_MLB_C7_PHEV,Motor_MLB_D4_C7_Hybrid,Motor_MLB_D4_C7_Otto
 SG_ LH_Aussenlicht_def : 7|1@1+ (1,0) [0|1] "" Vector__XXX
 SG_ LH_Standlicht_H_aktiv : 8|1@1+ (1,0) [0|1] "" Vector__XXX
 SG_ LH_Parklicht_HL_aktiv : 9|1@1+ (1,0) [0|1] "" Vector__XXX
 SG_ LH_Parklicht_HR_aktiv : 10|1@1+ (1,0) [0|1] "" Vector__XXX
 SG_ LH_Bremslicht_H_aktiv : 11|1@1+ (1,0) [0|1] "" Vector__XXX
 SG_ LH_Nebelschluss_aktiv : 12|1@1+ (1,0) [0|1] "" Vector__XXX
 SG_ LH_Rueckfahrlicht_aktiv : 13|1@1+ (1,0) [0|1] "" Vector__XXX
 SG_ LH_Blinker_HL_akt : 14|1@1+ (1,0) [0|1] "" Vector__XXX
 SG_ LH_Blinker_HR_akt : 15|1@1+ (1,0) [0|1] "" Vector__XXX
 SG_ LH_Blinker_li_def : 16|1@1+ (1,0) [0|1] "" Vector__XXX
 SG_ LH_Bremsl_li_def : 17|1@1+ (1,0) [0|1] "" Vector__XXX
 SG_ LH_Schlusslicht_li_def : 18|1@1+ (1,0) [0|1] "" Vector__XXX
 SG_ LH_Rueckf_li_def : 19|1@1+ (1,0) [0|1] "" Vector__XXX
 SG_ LH_Nebel_li_def : 20|1@1+ (1,0) [0|1] "" Vector__XXX
 SG_ LH_Schluss_Brems_Nebel_li_def : 21|1@1+ (1,0) [0|1] "" Vector__XXX
 SG_ LH_Schluss_Brems_Nebel_re_def : 22|1@1+ (1,0) [0|1] "" Vector__XXX
 SG_ LH_Schluss_Brems_li_def : 24|1@1+ (1,0) [0|1] "" Vector__XXX
 SG_ LH_Schluss_Nebel_li_def : 25|1@1+ (1,0) [0|1] "" Vector__XXX
 SG_ LH_SL_BRL_BLK_li_def : 26|1@1+ (1,0) [0|1] "" Vector__XXX
 SG_ LH_Brems_Blk_li_def : 27|1@1+ (1,0) [0|1] "" Vector__XXX
 SG_ LH_Blinker_re_def : 32|1@1+ (1,0) [0|1] "" Vector__XXX
 SG_ LH_Bremsl_re_def : 33|1@1+ (1,0) [0|1] "" Vector__XXX
 SG_ LH_Schlusslicht_re_def : 34|1@1+ (1,0) [0|1] "" Vector__XXX
 SG_ LH_Rueckf_re_def : 35|1@1+ (1,0) [0|1] "" Vector__XXX
 SG_ LH_Nebel_re_def : 36|1@1+ (1,0) [0|1] "" Vector__XXX
 SG_ LH_Schluss_Brems_re_def : 40|1@1+ (1,0) [0|1] "" Vector__XXX
 SG_ LH_Schluss_Nebel_re_def : 41|1@1+ (1,0) [0|1] "" Vector__XXX
 SG_ LH_SL_BRL_BLK_re_def : 42|1@1+ (1,0) [0|1] "" Vector__XXX
 SG_ LH_Brems_Blk_re_def : 43|1@1+ (1,0) [0|1] "" Vector__XXX
 SG_ LH_Kennzl_def : 48|1@1+ (1,0) [0|1] "" Vector__XXX
 SG_ LH_3_Bremsl_def : 49|1@1+ (1,0) [0|1] ""  Motor_MLB_AU64_AU57_Diesel,Motor_MLB_BY_Otto,Motor_MLB_C7_PHEV,Motor_MLB_D4_C7_Hybrid,Motor_MLB_D4_C7_Otto
 SG_ LH_Nebel_mi_def : 50|1@1+ (1,0) [0|1] "" Vector__XXX
 SG_ LH_Rueckf_mi_def : 51|1@1+ (1,0) [0|1] "" Vector__XXX
 SG_ LH_Bremsl_li_ges_def : 54|1@1+ (1,0) [0|1] ""  Motor_MLB_AU64_AU57_Diesel,Motor_MLB_BY_Otto,Motor_MLB_C7_PHEV,Motor_MLB_D4_C7_Hybrid,Motor_MLB_D4_C7_Otto
 SG_ LH_Bremsl_re_ges_def : 55|1@1+ (1,0) [0|1] ""  Motor_MLB_AU64_AU57_Diesel,Motor_MLB_BY_Otto,Motor_MLB_C7_PHEV,Motor_MLB_D4_C7_Hybrid,Motor_MLB_D4_C7_Otto

BO_ 267 LS_01: 4 Gateway
 SG_ LS_01_CHK : 0|8@1+ (1,0) [0|255] ""  Getriebe_AL551_951_D4_C7,Getriebe_AL551_Hybrid_D4_C7,Getriebe_DL382_MLB,Getriebe_DL501_MLB,Getriebe_VL381_MLB,Motor_MLB_AU64_AU57_Diesel,Motor_MLB_BY_Otto,Motor_MLB_C7_PHEV,Motor_MLB_D4_C7_Hybrid,Motor_MLB_D4_C7_Otto
 SG_ LS_01_BZ : 8|4@1+ (1,0) [0|15] ""  Getriebe_AL551_951_D4_C7,Getriebe_AL551_Hybrid_D4_C7,Getriebe_DL382_MLB,Getriebe_DL501_MLB,Getriebe_VL381_MLB,Motor_MLB_AU64_AU57_Diesel,Motor_MLB_BY_Otto,Motor_MLB_C7_PHEV,Motor_MLB_D4_C7_Hybrid,Motor_MLB_D4_C7_Otto
 SG_ LS_Hauptschalter : 12|1@1+ (1,0) [0|1] ""  Motor_MLB_AU64_AU57_Diesel,Motor_MLB_BY_Otto,Motor_MLB_C7_PHEV,Motor_MLB_D4_C7_Hybrid,Motor_MLB_D4_C7_Otto
 SG_ LS_Abbrechen : 13|1@1+ (1,0) [0|1] ""  Motor_MLB_AU64_AU57_Diesel,Motor_MLB_BY_Otto,Motor_MLB_C7_PHEV,Motor_MLB_D4_C7_Hybrid,Motor_MLB_D4_C7_Otto
 SG_ LS_Typ_Hauptschalter : 14|1@1+ (1,0) [0|1] ""  Motor_MLB_AU64_AU57_Diesel,Motor_MLB_BY_Otto,Motor_MLB_C7_PHEV,Motor_MLB_D4_C7_Hybrid,Motor_MLB_D4_C7_Otto
 SG_ LS_Limiter : 15|1@1+ (1,0) [0|1] ""  Motor_MLB_AU64_AU57_Diesel,Motor_MLB_BY_Otto,Motor_MLB_C7_PHEV,Motor_MLB_D4_C7_Hybrid,Motor_MLB_D4_C7_Otto
 SG_ LS_Tip_Setzen : 16|1@1+ (1,0) [0|1] ""  Getriebe_DL382_MLB,Getriebe_DL501_MLB,Motor_MLB_AU64_AU57_Diesel,Motor_MLB_BY_Otto,Motor_MLB_C7_PHEV,Motor_MLB_D4_C7_Hybrid,Motor_MLB_D4_C7_Otto
 SG_ LS_Tip_Hoch : 17|1@1+ (1,0) [0|1] ""  Getriebe_DL382_MLB,Getriebe_DL501_MLB,Motor_MLB_AU64_AU57_Diesel,Motor_MLB_BY_Otto,Motor_MLB_C7_PHEV,Motor_MLB_D4_C7_Hybrid,Motor_MLB_D4_C7_Otto
 SG_ LS_Tip_Runter : 18|1@1+ (1,0) [0|1] ""  Getriebe_DL382_MLB,Getriebe_DL501_MLB,Motor_MLB_AU64_AU57_Diesel,Motor_MLB_BY_Otto,Motor_MLB_C7_PHEV,Motor_MLB_D4_C7_Hybrid,Motor_MLB_D4_C7_Otto
 SG_ LS_Tip_Wiederaufnahme : 19|1@1+ (1,0) [0|1] ""  Getriebe_DL382_MLB,Getriebe_DL501_MLB,Motor_MLB_AU64_AU57_Diesel,Motor_MLB_BY_Otto,Motor_MLB_C7_PHEV,Motor_MLB_D4_C7_Hybrid,Motor_MLB_D4_C7_Otto
 SG_ LS_Verstellung_Zeitluecke : 20|2@1+ (1,0) [0|3] "" Vector__XXX
 SG_ MFL_Tip_Down : 22|1@1+ (1,0) [0|1] ""  Getriebe_AL551_951_D4_C7,Getriebe_AL551_Hybrid_D4_C7,Getriebe_DL382_MLB,Getriebe_DL501_MLB,Getriebe_VL381_MLB
 SG_ MFL_Tip_Up : 23|1@1+ (1,0) [0|1] ""  Getriebe_AL551_951_D4_C7,Getriebe_AL551_Hybrid_D4_C7,Getriebe_DL382_MLB,Getriebe_DL501_MLB,Getriebe_VL381_MLB
 SG_ LS_Tiptronic_Fehler : 24|1@1+ (1,0) [0|1] ""  Getriebe_AL551_951_D4_C7,Getriebe_AL551_Hybrid_D4_C7,Getriebe_DL382_MLB,Getriebe_DL501_MLB
 SG_ LS_Fehler : 25|1@1+ (1,0) [0|1] ""  Motor_MLB_AU64_AU57_Diesel,Motor_MLB_BY_Otto,Motor_MLB_C7_PHEV,Motor_MLB_D4_C7_Hybrid,Motor_MLB_D4_C7_Otto
 SG_ LS_Codierung : 26|3@1+ (1,0) [0|7] ""  Motor_MLB_AU64_AU57_Diesel,Motor_MLB_BY_Otto,Motor_MLB_C7_PHEV,Motor_MLB_D4_C7_Hybrid,Motor_MLB_D4_C7_Otto
 SG_ LS_Tip_Stufe_2 : 29|1@1+ (1,0) [0|1] ""  Motor_MLB_AU64_AU57_Diesel,Motor_MLB_BY_Otto,Motor_MLB_C7_PHEV,Motor_MLB_D4_C7_Hybrid,Motor_MLB_D4_C7_Otto
 SG_ LS_GRA_ACC_2stufig : 30|1@1+ (1,0) [0|1] ""  Motor_MLB_AU64_AU57_Diesel,Motor_MLB_BY_Otto,Motor_MLB_C7_PHEV,Motor_MLB_D4_C7_Hybrid,Motor_MLB_D4_C7_Otto
 SG_ MFL_M_Taste : 31|1@1+ (1,0) [0|1] ""  Getriebe_AL551_951_D4_C7,Getriebe_AL551_Hybrid_D4_C7

BO_ 134 LWI_01: 8 LWS_D4
 SG_ LWI_01_CHK : 0|8@1+ (1,0) [0|255] ""  Airbag_D4,ESP,Gateway,Getriebe_AL551_951_D4_C7,Getriebe_AL551_Hybrid_D4_C7,QSP,SCU
 SG_ LWI_01_BZ : 8|4@1+ (1,0) [0|15] ""  Airbag_D4,ESP,Gateway,Getriebe_AL551_951_D4_C7,Getriebe_AL551_Hybrid_D4_C7,QSP,SCU
 SG_ LWI_Sensorstatus : 12|1@1+ (1,0) [0|1] ""  ESP,Gateway,Getriebe_AL551_951_D4_C7,Getriebe_AL551_Hybrid_D4_C7,Motor_MLB_AU64_AU57_Diesel,Motor_MLB_BY_Otto,Motor_MLB_C7_PHEV,Motor_MLB_D4_C7_Hybrid,Motor_MLB_D4_C7_Otto,QSP,SCU
 SG_ LWI_QBit_Sub_Daten : 13|1@1+ (1,0) [0|1] ""  ESP,Gateway,QSP,SCU
 SG_ LWI_QBit_Lenkradwinkel : 15|1@1+ (1,0) [0|1] ""  Airbag_D4,ESP,Gateway,Getriebe_AL551_951_D4_C7,Getriebe_AL551_Hybrid_D4_C7,Motor_MLB_AU64_AU57_Diesel,Motor_MLB_BY_Otto,Motor_MLB_C7_PHEV,Motor_MLB_D4_C7_Hybrid,Motor_MLB_D4_C7_Otto,QSP,SCU
 SG_ LWI_Lenkradwinkel : 16|13@1+ (0.1,0) [0|800] "Unit_DegreOfArc"  Airbag_D4,ESP,Gateway,Getriebe_AL551_951_D4_C7,Getriebe_AL551_Hybrid_D4_C7,Getriebe_DL382_MLB,Getriebe_DL501_MLB,Getriebe_VL381_MLB,Motor_MLB_AU64_AU57_Diesel,Motor_MLB_BY_Otto,Motor_MLB_C7_PHEV,Motor_MLB_D4_C7_Hybrid,Motor_MLB_D4_C7_Otto,QSP,SCU
 SG_ LWI_VZ_Lenkradwinkel : 29|1@1+ (1,0) [0|1] ""  Airbag_D4,ESP,Gateway,Getriebe_AL551_951_D4_C7,Getriebe_AL551_Hybrid_D4_C7,Getriebe_DL382_MLB,Getriebe_DL501_MLB,Motor_MLB_AU64_AU57_Diesel,Motor_MLB_BY_Otto,Motor_MLB_C7_PHEV,Motor_MLB_D4_C7_Hybrid,Motor_MLB_D4_C7_Otto,QSP,SCU
 SG_ LWI_VZ_Lenkradw_Geschw : 30|1@1+ (1,0) [0|1] ""  Gateway
 SG_ LWI_Lenkradw_Geschw : 31|9@1+ (5,0) [0|2500] "Unit_DegreOfArcPerSecon"  Gateway
 SG_ LWI_Sub_Daten : 40|16@1+ (1,0) [0|65535] ""  ESP,Gateway,QSP,SCU
 SG_ LWI_01_CRC : 56|8@1+ (1,0) [0|255] ""  Airbag_D4,ESP,Gateway,QSP,SCU

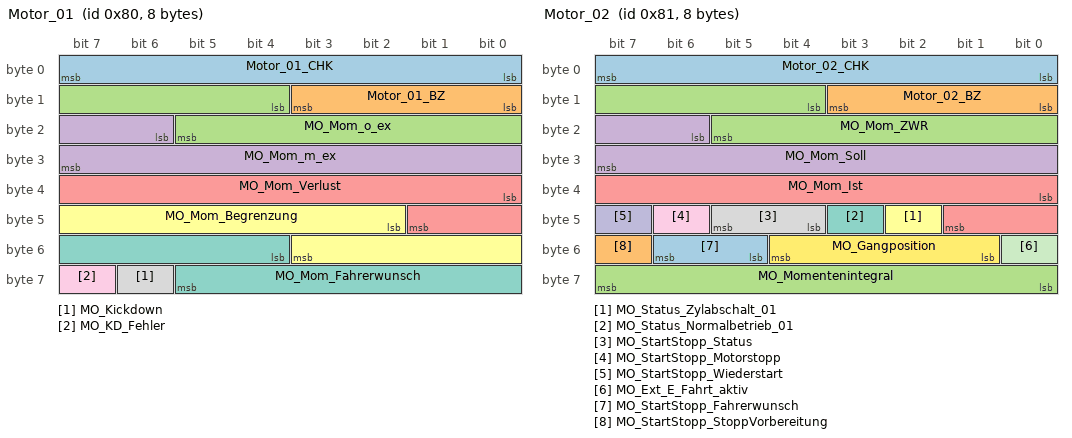
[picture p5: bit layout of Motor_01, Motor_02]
BO_ 128 Motor_01: 8 Motor_MLB_AU64_AU57_Diesel
 SG_ Motor_01_CHK : 0|8@1+ (1,0) [0|255] ""  EPB_MLB,Gateway,Getriebe_AL551_951_D4_C7,Getriebe_AL551_Hybrid_D4_C7,Getriebe_DL382_MLB,Getriebe_DL501_MLB,Getriebe_VL381_MLB
 SG_ Motor_01_BZ : 8|4@1+ (1,0) [0|15] ""  EPB_MLB,Gateway,Getriebe_AL551_951_D4_C7,Getriebe_AL551_Hybrid_D4_C7,Getriebe_DL382_MLB,Getriebe_DL501_MLB,Getriebe_VL381_MLB
 SG_ MO_Mom_o_ex : 12|10@1+ (1,0) [0|1021] ""  Gateway,Getriebe_AL551_951_D4_C7,Getriebe_AL551_Hybrid_D4_C7,Getriebe_DL382_MLB,Getriebe_DL501_MLB,Getriebe_VL381_MLB
 SG_ MO_Mom_m_ex : 22|10@1+ (1,0) [0|1021] ""  EPB_MLB,Gateway,Getriebe_AL551_951_D4_C7,Getriebe_AL551_Hybrid_D4_C7,Getriebe_DL382_MLB,Getriebe_DL501_MLB,Getriebe_VL381_MLB,SAK,SAK2
 SG_ MO_Mom_Verlust : 32|10@1+ (1,0) [0|1021] ""  EPB_MLB,Gateway,Getriebe_AL551_951_D4_C7,Getriebe_AL551_Hybrid_D4_C7,Getriebe_DL382_MLB,Getriebe_DL501_MLB,Getriebe_VL381_MLB,SAK,SAK2
 SG_ MO_Mom_Begrenzung : 42|10@1+ (1,0) [0|1021] ""  Gateway,Getriebe_AL551_951_D4_C7,Getriebe_AL551_Hybrid_D4_C7,Getriebe_DL382_MLB,Getriebe_DL501_MLB,Getriebe_VL381_MLB
 SG_ MO_Mom_Fahrerwunsch : 52|10@1+ (1,0) [0|1021] ""  Gateway,Getriebe_AL551_951_D4_C7,Getriebe_AL551_Hybrid_D4_C7,Getriebe_DL382_MLB,Getriebe_DL501_MLB,Getriebe_VL381_MLB
 SG_ MO_Kickdown : 62|1@1+ (1,0) [0|1] ""  Gateway,Getriebe_AL551_951_D4_C7,Getriebe_AL551_Hybrid_D4_C7,Getriebe_DL382_MLB,Getriebe_DL501_MLB,Getriebe_VL381_MLB
 SG_ MO_KD_Fehler : 63|1@1+ (1,0) [0|1] ""  Gateway

BO_ 129 Motor_02: 8 Motor_MLB_AU64_AU57_Diesel
 SG_ Motor_02_CHK : 0|8@1+ (1,0) [0|255] ""  EPB_MLB,Gateway,Getriebe_AL551_951_D4_C7,Getriebe_AL551_Hybrid_D4_C7,Getriebe_DL382_MLB,Getriebe_DL501_MLB,Getriebe_VL381_MLB,SCU
 SG_ Motor_02_BZ : 8|4@1+ (1,0) [0|15] ""  EPB_MLB,Gateway,Getriebe_AL551_951_D4_C7,Getriebe_AL551_Hybrid_D4_C7,Getriebe_DL382_MLB,Getriebe_DL501_MLB,Getriebe_VL381_MLB,SCU
 SG_ MO_Mom_ZWR : 12|10@1+ (1,0) [0|1021] ""  Gateway,Getriebe_DL382_MLB,Getriebe_DL501_MLB
 SG_ MO_Mom_Soll : 22|10@1+ (1,0) [0|1021] ""  Gateway,Getriebe_AL551_951_D4_C7,Getriebe_AL551_Hybrid_D4_C7,Getriebe_DL382_MLB,Getriebe_DL501_MLB,Getriebe_VL381_MLB
 SG_ MO_Mom_Ist : 32|10@1+ (1,0) [0|1021] ""  Gateway,Getriebe_AL551_951_D4_C7,Getriebe_AL551_Hybrid_D4_C7,Getriebe_DL382_MLB,Getriebe_DL501_MLB,Getriebe_VL381_MLB
 SG_ MO_Status_Zylabschalt_01 : 42|1@1+ (1,0) [0|1] ""  Gateway,Getriebe_AL551_951_D4_C7,Getriebe_AL551_Hybrid_D4_C7
 SG_ MO_Status_Normalbetrieb_01 : 43|1@1+ (1,0) [0|1] ""  Gateway,Getriebe_DL382_MLB,Getriebe_DL501_MLB,Getriebe_VL381_MLB
 SG_ MO_StartStopp_Status : 44|2@1+ (1,0) [0|3] ""  Gateway,Getriebe_AL551_951_D4_C7,Getriebe_AL551_Hybrid_D4_C7,Getriebe_DL382_MLB,Getriebe_DL501_MLB,Getriebe_VL381_MLB,SCR_MLB,SCU
 SG_ MO_StartStopp_Motorstopp : 46|1@1+ (1,0) [0|1] ""  EPB_MLB,Gateway,Getriebe_AL551_951_D4_C7,Getriebe_AL551_Hybrid_D4_C7,Getriebe_DL382_MLB,Getriebe_DL501_MLB,Getriebe_VL381_MLB,LEH_Hybrid,SCR_MLB,SCU
 SG_ MO_StartStopp_Wiederstart : 47|1@1+ (1,0) [0|1] ""  EPB_MLB,Gateway,Getriebe_AL551_951_D4_C7,Getriebe_AL551_Hybrid_D4_C7,Getriebe_DL382_MLB,Getriebe_DL501_MLB,Getriebe_VL381_MLB,SCR_MLB,SCU
 SG_ MO_Ext_E_Fahrt_aktiv : 48|1@1+ (1,0) [0|1] ""  Gateway,Getriebe_AL551_Hybrid_D4_C7
 SG_ MO_Gangposition : 49|4@1+ (1,0) [0|15] ""  Gateway
 SG_ MO_StartStopp_Fahrerwunsch : 53|2@1+ (1,0) [0|3] ""  Gateway
 SG_ MO_StartStopp_StoppVorbereitung : 55|1@1+ (1,0) [0|1] ""  Gateway,Getriebe_AL551_951_D4_C7,Getriebe_AL551_Hybrid_D4_C7,Getriebe_DL382_MLB,Getriebe_DL501_MLB,Getriebe_VL381_MLB
 SG_ MO_Momentenintegral : 56|8@1+ (0.3921,0) [0|99.9855] ""  Gateway,Getriebe_AL551_951_D4_C7,Getriebe_AL551_Hybrid_D4_C7,Getriebe_DL382_MLB,Getriebe_DL501_MLB,Getriebe_VL381_MLB

BO_ 261 Motor_03: 8 Motor_MLB_AU64_AU57_Diesel
 SG_ Motor_03_CHK : 0|8@1+ (1,0) [0|255] ""  Airbag_D4,EPB_MLB,Gateway,Getriebe_AL551_951_D4_C7,Getriebe_AL551_Hybrid_D4_C7,Getriebe_DL382_MLB,Getriebe_DL501_MLB,Getriebe_VL381_MLB,LEH_Hybrid,SCU
 SG_ Motor_03_BZ : 8|4@1+ (1,0) [0|15] ""  Airbag_D4,EPB_MLB,Gateway,Getriebe_AL551_951_D4_C7,Getriebe_AL551_Hybrid_D4_C7,Getriebe_DL382_MLB,Getriebe_DL501_MLB,Getriebe_VL381_MLB,LEH_Hybrid,SCU
 SG_ MO_QBit_Fahrpedalwerte_01 : 12|1@1+ (1,0) [0|1] ""  Airbag_D4,EPB_MLB,Gateway,Getriebe_AL551_951_D4_C7,Getriebe_AL551_Hybrid_D4_C7,Getriebe_DL382_MLB,Getriebe_DL501_MLB,Getriebe_VL381_MLB
 SG_ MO_QBit_Motormomente : 13|1@1+ (1,0) [0|1] ""  EPB_MLB,Gateway,Getriebe_AL551_951_D4_C7,Getriebe_AL551_Hybrid_D4_C7,Getriebe_DL382_MLB,Getriebe_DL501_MLB,Getriebe_VL381_MLB
 SG_ MO_QBit_Fahrer_bremst : 14|1@1+ (1,0) [0|1] ""  EPB_MLB,Gateway,Getriebe_AL551_951_D4_C7,Getriebe_AL551_Hybrid_D4_C7,Getriebe_DL382_MLB,Getriebe_DL501_MLB,Getriebe_VL381_MLB
 SG_ MO_QBit_Drehzahl_01 : 15|1@1+ (1,0) [0|1] ""  Airbag_D4,EPB_MLB,Gateway,Getriebe_AL551_951_D4_C7,Getriebe_AL551_Hybrid_D4_C7,Getriebe_DL382_MLB,Getriebe_DL501_MLB,Getriebe_VL381_MLB,LEH_Hybrid
 SG_ MO_Drehzahl_01 : 16|16@1+ (0.25,0) [0|16383] "Unit_MinutInver"  Airbag_D4,BMS_Hybrid,EPB_MLB,Gateway,Getriebe_AL551_951_D4_C7,Getriebe_AL551_Hybrid_D4_C7,Getriebe_DL382_MLB,Getriebe_DL501_MLB,Getriebe_VL381_MLB,LEH_Hybrid,SAK,SAK2,SCR_MLB,SCU
 SG_ MO_Moment_im_Leerlauf : 32|1@1+ (1,0) [0|1] ""  Gateway
 SG_ MO_Interlock : 33|1@1+ (1,0) [0|1] ""  EPB_MLB,Gateway
 SG_ MO_BLS : 34|1@1+ (1,0) [0|1] ""  Airbag_D4,EPB_MLB,Gateway,Getriebe_AL551_951_D4_C7,Getriebe_AL551_Hybrid_D4_C7,Getriebe_DL382_MLB,Getriebe_DL501_MLB,Getriebe_VL381_MLB
 SG_ MO_Fahrer_bremst : 35|1@1+ (1,0) [0|1] ""  EPB_MLB,Gateway,Getriebe_AL551_951_D4_C7,Getriebe_AL551_Hybrid_D4_C7,Getriebe_DL382_MLB,Getriebe_DL501_MLB,Getriebe_VL381_MLB
 SG_ MO_Konsistenz_Bremsped : 36|1@1+ (1,0) [0|1] ""  Gateway,Getriebe_AL551_951_D4_C7,Getriebe_AL551_Hybrid_D4_C7,Getriebe_DL382_MLB,Getriebe_DL501_MLB,Getriebe_VL381_MLB
 SG_ MO_Kuppl_schalter : 37|1@1+ (1,0) [0|1] ""  EPB_MLB,Gateway
 SG_ MO_Timeout_ESP : 38|1@1+ (1,0) [0|1] ""  Gateway
 SG_ MO_Motor_laeuft : 39|1@1+ (1,0) [0|1] ""  EPB_MLB,Gateway,Getriebe_VL381_MLB
 SG_ MO_Solldrehz_Leerlauf : 40|8@1+ (10,0) [0|2540] "Unit_MinutInver"  Gateway,Getriebe_AL551_951_D4_C7,Getriebe_AL551_Hybrid_D4_C7,Getriebe_DL382_MLB,Getriebe_DL501_MLB,Getriebe_VL381_MLB
 SG_ MO_Fahrpedalrohwert_01 : 48|8@1+ (0.4,0) [0|101.6] "Unit_PerCent"  Airbag_D4,EPB_MLB,Gateway,Getriebe_AL551_951_D4_C7,Getriebe_AL551_Hybrid_D4_C7,Getriebe_DL382_MLB,Getriebe_DL501_MLB,Getriebe_VL381_MLB
 SG_ MO_erste_Ungenauschwelle : 56|1@1+ (1,0) [0|1] ""  Gateway,Getriebe_AL551_951_D4_C7,Getriebe_AL551_Hybrid_D4_C7,Getriebe_DL382_MLB,Getriebe_DL501_MLB,Getriebe_VL381_MLB
 SG_ MO_QBit_Stressfaktor : 57|1@1+ (1,0) [0|1] ""  Gateway,Getriebe_AL551_951_D4_C7,Getriebe_AL551_Hybrid_D4_C7,Getriebe_DL382_MLB,Getriebe_DL501_MLB,Getriebe_VL381_MLB
 SG_ MO_Stressfaktor : 58|6@1+ (1.6,0) [0|100.8] "Unit_PerCent"  Gateway,Getriebe_AL551_951_D4_C7,Getriebe_AL551_Hybrid_D4_C7,Getriebe_DL382_MLB,Getriebe_DL501_MLB,Getriebe_VL381_MLB

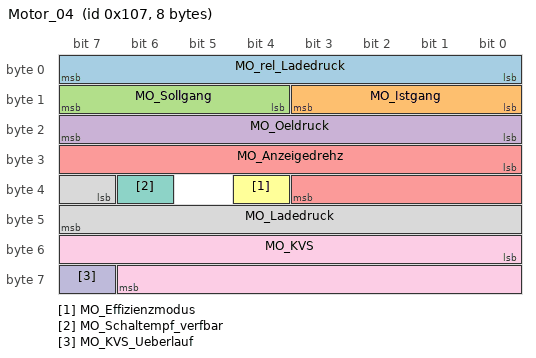
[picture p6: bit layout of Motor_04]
BO_ 263 Motor_04: 8 Motor_MLB_AU64_AU57_Diesel
 SG_ MO_rel_Ladedruck : 0|8@1+ (0.4,0) [0|100] "Unit_PerCent"  Gateway
 SG_ MO_Istgang : 8|4@1+ (1,0) [0|15] ""  Gateway
 SG_ MO_Sollgang : 12|4@1+ (1,0) [0|15] ""  Gateway
 SG_ MO_Oeldruck : 16|8@1+ (0.04,0) [0|10] "Unit_Bar"  Gateway
 SG_ MO_Anzeigedrehz : 24|12@1+ (3,0) [0|12282] "Unit_MinutInver"  Gateway
 SG_ MO_Effizienzmodus : 36|1@1+ (1,0) [0|1] ""  Gateway
 SG_ MO_Schaltempf_verfbar : 38|1@1+ (1,0) [0|1] ""  Gateway
 SG_ MO_Ladedruck : 39|9@1+ (0.01,0) [0|5.1] "Unit_Bar"  Gateway
 SG_ MO_KVS : 48|15@1+ (1,0) [0|32767] "Unit_MicroLiter"  Gateway
 SG_ MO_KVS_Ueberlauf : 63|1@1+ (1,0) [0|1] ""  Gateway

BO_TX_BU_ 131 : Getriebe_AL551_951_D4_C7,Getriebe_AL551_Hybrid_D4_C7,Getriebe_DL382_MLB,Getriebe_DL501_MLB,Getriebe_VL381_MLB;
BO_TX_BU_ 258 : Getriebe_AL551_951_D4_C7,Getriebe_AL551_Hybrid_D4_C7,Getriebe_DL382_MLB,Getriebe_DL501_MLB,Getriebe_VL381_MLB;
BO_TX_BU_ 1089 : Getriebe_AL551_951_D4_C7,Getriebe_AL551_Hybrid_D4_C7,Getriebe_DL382_MLB,Getriebe_DL501_MLB,Getriebe_VL381_MLB;
BO_TX_BU_ 2025 : Getriebe_AL551_951_D4_C7,Getriebe_AL551_Hybrid_D4_C7,Getriebe_DL382_MLB,Getriebe_DL501_MLB,Getriebe_VL381_MLB;
BO_TX_BU_ 2024 : Motor_MLB_AU64_AU57_Diesel,Motor_MLB_BY_Otto,Motor_MLB_C7_PHEV,Motor_MLB_D4_C7_Hybrid,Motor_MLB_D4_C7_Otto;
BO_TX_BU_ 1981 : Getriebe_AL551_951_D4_C7,Getriebe_AL551_Hybrid_D4_C7;
BO_TX_BU_ 128 : Motor_MLB_AU64_AU57_Diesel,Motor_MLB_BY_Otto,Motor_MLB_C7_PHEV,Motor_MLB_D4_C7_Hybrid,Motor_MLB_D4_C7_Otto;
BO_TX_BU_ 129 : Motor_MLB_AU64_AU57_Diesel,Motor_MLB_BY_Otto,Motor_MLB_C7_PHEV,Motor_MLB_D4_C7_Hybrid,Motor_MLB_D4_C7_Otto;
BO_TX_BU_ 261 : Motor_MLB_AU64_AU57_Diesel,Motor_MLB_BY_Otto,Motor_MLB_C7_PHEV,Motor_MLB_D4_C7_Hybrid,Motor_MLB_D4_C7_Otto;
BO_TX_BU_ 263 : Motor_MLB_AU64_AU57_Diesel,Motor_MLB_BY_Otto,Motor_MLB_C7_PHEV,Motor_MLB_D4_C7_Hybrid,Motor_MLB_D4_C7_Otto;
CM_ SG_ 131 Getriebe_02_CHK "Berechnung siehe Lastenheft 'Kommunikationsabsicherung für FlexRay und CAN'
Endwerte siehe 'Kommunikationsabsicherung für FlexRay und CAN / Anhang C: Tabelle S-PDU Kennungen'";
CM_ SG_ 131 GE_Anf_Zylabsch "GE_Anforderung_Zylinderabschaltung
Getriebe-Koordination Zylinderumschaltung TMB / VMB (Teilmotorbetrieb / Vollmotorbetrieb)";
CM_ SG_ 131 GE_Synchro_Wunschdrehz "Wunschdrehzahl für Verbrennungsmotor bzw. E-Motor; Freigabe durch GE_Freigabe_Synchro (bei MLB und MQB), Freigabe und Steuerung durch GE_Synchro_Status (bei MLBevo).
Wenn kein Eingriff angefordert wird, soll Init = 0 = 0x0 gesendet werden.";
CM_ SG_ 131 GE_Synchro_Zeit "Signalisiert wie schnell die Wunschdrehzahl bei einem Synchronisations-Wunschdrehzahl-Eingriff aufgebaut werden soll. Die Zeitvorgabe 0x0 bedeutet so schnell wie möglich. Die geforderte Synchronisationszeit bleibt bis zum Abbruch oder erreichen der Zeit k";
CM_ SG_ 131 GE_Mom_Begr_Gradient "Gradientenbegrenzung des Motormoments durch das Getriebe";
CM_ SG_ 131 GE_Anheb_Solldrehz_Leerlauf "Anforderung einer absoluten Leerlaufdrehzahl";
CM_ SG_ 131 GE_Vorsteuermoment "Achtung:
Einheitenloser CAN-Wert.
Faktor in MO_Faktor_Momente in Motor_Code_01 beachten!

Vorsteuermoment für Leerlaufdrehzahlregler im Motor";
CM_ SG_ 131 GE_Segeln_Aktiv "Status des Segelkoordinators";
CM_ SG_ 131 GE_Drehzahlmesser_Daempfung "Beim DQ-Getriebe kann die Anzeigedämpfung des Drehzahlmessers beim Schalten geändert werden.";
CM_ SG_ 131 GE_Schubabschalt_Unt "Signalisiert wenn aus der Sicht des Getriebes eine Schubabschaltung des Motors möglich ist. Bei aktiver Schubabschalt-Unterstützung wird sicher gestellt, dass die Kupplung nicht schlagartig geöffnet wird";
CM_ SG_ 131 GE_Freigabe_Synchro "Freigabe der Signale
'GE_Synchro_Wunschdrehz' und 'GE_Synchro_Zeit'";
CM_ SG_ 131 GE_HYB_DZ_Eingriff "Freigabebedingung für Drehzahleingriff-Hybrid";
CM_ SG_ 258 Getriebe_03_CHK "Berechnung siehe Lastenheft 'Kommunikationsabsicherung für FlexRay und CAN'
Endwerte siehe 'Kommunikationsabsicherung für FlexRay und CAN / Anhang C: Tabelle S-PDU Kennungen'";
CM_ SG_ 258 GE_Freig_Langfr_Schutzmom "Freigabeflag für das langfristige Schutzmoment für
MLB: GE_Langfr_Schutzmom
MQB: GE_Langfr_Schutzmom_02";
CM_ SG_ 258 GE_Uefkt "Übertragungsfunktion des Getriebes
Drehzahlverhältnis = Eingangsdrehzahl / Ausgangsdrehzahl

AL: Wandlerverstärkung x Drehzahlverhältnis
VL: Drehzahlverhältnis
DL: Drehzahlverhältnis der aktiven und kraftschluß führenden Welle zum Abtrieb, bei Schalt";
CM_ SG_ 258 GE_Zielgang "VL-Getriebe:
Signalisiert den Zielgang im manuellen Modus während eines Schaltvorgangs bzw. die momentane simulierte Gangstufe wenn kein Schaltvorgang aktiv ist. In den Fahrprogrammen 'D' und 'S' ist die Übersetzung variabel und somit wird dauerhaft 'Ist";
CM_ SG_ 258 GE_StartStopp_Info "Stopp-Freigabe und Start-Anforderung an den Start-Stopp-Koordinator";
CM_ SG_ 258 GE_Langfr_Schutzmom "Begrenzung des Motormomentes aus Getriebeschutzgründen. Der langzeitige Motormomenteneingriff ist nur negativ (reduzierend), positiver Mmo-Eingriff wird nicht unterstützt. Ist kein Motormomenteneingriff erforderlich wird der Initwert gesendet. Das Signal ";
CM_ SG_ 258 GE_Performance_Start_LB "Die Bereitschaft zum 'Jump Start' wird mit diesem Signal signalisiert. ";
CM_ SG_ 258 GE_reserv_Waehlhebel "reserviert falls künftig Erweiterung von GE_Waehlhebel nötig";
CM_ SG_ 258 GE_Waehlhebel "Fahrprogramm des Getriebes

0x0 Zwischenstellung (Darf nur für Zustandswechsel P/R, R/N, N/D ausgegeben werden, nicht für D/S oder D/Tippgasse wegen Abschaltkriterium GRA/ACC)

0xD: Bedienung AL ab D4
0x9, 0xA, 0xD: werden in PAG Macan nicht bedient";
CM_ SG_ 258 GE_Eingangsdrehz "Wird gesendet, um das Lastschlagverhalten bei Schaltvorgängen zu verbessern.";
CM_ SG_ 258 GE_Notlauf "AL/DL: Signalisiert wenn sich das Getriebe (bei DL ein Teilgetriebe) im Notlauf befindet.
VL: Wird gesetzt wenn kein Kraftschluss möglich ist.";
CM_ SG_ 258 GE_Codierung_MSG "Statusausgabe der Diagnose für Falschverbau. Plausibilisierung der empfangenen Motor- und Getriebevariante mit der erwarteten Motor- und Getriebevarianten.";
CM_ SG_ 1089 GE_Index_Fahrwid "Auf % Steigung am Berg normiert";
CM_ SG_ 1089 GE_OBD_Status "Dieses Bit steuert die MIL-Lampe an (Motorsteuergerät reicht diese Info an Kombi weiter).";
CM_ SG_ 1089 GE_LFR_Adaption "Qualifiziert das ausgegeben Motorbelastungsmoment (durch GE_Vorsteuermoment) für die Verwendung zur LFR (Leerlauffüllungsregelung) im Moto";
CM_ SG_ 1089 GE_OBD_AbsperrVent "Das Getriebesteuergerät führt eine elektrische Diagnose des von ihm angesteuerten Absperrventils für den Öl-Wasser-Wärmetauscher durch und übermittelt das Ergebnis an das MSG (Standard-4Bit-OBD-Status, nicht alle Zustände müssen genutzt werden; so sind z.";
CM_ SG_ 1089 GE_Grenzkriechmoment "Das Grenzkriechmoment ist das max. Motormoment was von der Kupplung im Fahrzeugstillstand aufgenommen werden kann um z.B. das Fgz. am Berg zu halten oder das Ankriechen zu gewährleisten.

Achtung:
Einheitenloser CAN-Wert.
Faktor in MO_Faktor_Momente i";
CM_ SG_ 1089 GE_Charisma_FahrPr "Aktuelles Fahrprogramm des Charisma-Teilnehmers

Achtung neue Modusnamen (wie im MMI):

0x1 = Komfort = Comfort
0x2 = Dynamik = Auto
0x3 = Sport = Dynamic";
CM_ SG_ 1089 GE_Charisma_Status "Charisma Systemstatus des Charisma-Teilnehmers

Wert 0x3 ist nur für Fahrzeuge ab MQB relevant";
CM_ SG_ 1089 GE_Charisma_Umschaltung "Erkennung  Umschaltaufforderung des Charisma-Teilnehmers";
CM_ SG_ 1089 GE_Freigabe_Verfallsinfo_WFS "WFS";
CM_ SG_ 1089 GE_Verlustmoment "Achtung einheitenloser Wert !!
	Faktor in MO_Faktor_Momente (MLB) bzw. MO_Faktor_Momente_02 (MQB/MLBevo) in Motor_Code_01 beachten!

ab MQB/MLBevo:
	Das Signal enthält die berechneten Momentenverluste, welche innerhalb des Getriebegehäuses entstehen (";
CM_ SG_ 1089 GE_LaunchControl "Während einer LaunchControl-Anfahrt sendet das Getriebesteuergerät das Bit LaunchControl aktiv.
Die Bremse wertet dieses Bit aus, um während einer solchen Anfahrt die Regelgrenzen der Schlupfregelung zu erweitern.
Im Motor Nutzung zur Verbesserung des A";
CM_ SG_ 1089 GE_amax_moeglich "AL/DL: maximal mögliche Beschleunigung unter Berücksichtigung aller möglichen Gänge.

Eine Reduzierung des maximalen Motormoments durch Efficiency wird in dem Signal berücksichtigt.

VL: maximal mögliche Beschleunigung bei Nenndrehzahl (Efficency wird";
CM_ SG_ 1089 GE_Sumpftemperatur "Getriebesumpftemperatur wird über den Temperatursensor auf der Getriebeplatine ermittelt. Die absolute Sumpftemperatur wird vom Motor empfangen, um entsprechende Kühlleistung für das Getriebe einzustellen.";
CM_ BO_ 1340 "CAN-Botschaft";
CM_ SG_ 1340 HVLM_04_CRC "Für MLB:
'Berechnung siehe Lastenheft 'Kommunikationsabsicherung für FlexRay und CAN''

Ab MQB und MLBevo:
'Berechnung siehe Lastenheft 'End-to-End Kommunikationsabsicherung''

Endwerte siehe Begleitdokument 'S-PDU Kennungsfolgen'";
CM_ SG_ 1340 HVLM_04_BZ "Fortlaufender Botschaftszaehler";
CM_ SG_ 1340 HVLM_IstModus_02 "aktueller Modus";
CM_ SG_ 1340 HVLM_HV_Anf "HV-Aktivierung Anforderung und Grund der Anforderung";
CM_ SG_ 1340 HVLM_Fehlerstatus "aktueller Fehlerstatus des Ladegerätes
";
CM_ SG_ 1340 HVLM_Anforderung_HMS "Anforderung zur Verriegelung des Triebstrangs";
CM_ SG_ 1340 HVLM_Parken_beibehalten_HMS "Anforderung den Triebstrang verriegelt zu halten";
CM_ SG_ 1340 HVLM_Dauer_Klima "Dauer der Innenraumklimatisierung";
CM_ SG_ 1340 HVLM_Stecker_Status "Status der Steckererkennung unabhängig vom Lademodus (AC oder DC)";
CM_ SG_ 1340 HVLM_LadeAnforderung "Mitteilung des Lademanagements an das MSG ob Stecker erkannt wurde, Laden gestartet, ein autonomer Betriebszustand aktiviert, eine Relaxing Phase für die Batterie angefordert werden soll";
CM_ SG_ 1340 HVLM_MaxBatLadestromHV "Empfohlener HV Batterieladestrom bei einer geplanten Ladung";
CM_ SG_ 2018 ISO_OBD_01_Req_Data "MLB: Motor-Slave
MLBevo: Motor-Slave";
CM_ SG_ 2026 ISO_OBD_01_Resp_Data "MLB: Motor-Slave
MLBevo: Motor-Slave";
CM_ SG_ 2021 ISO_OBD_04_Req_Data "MLBevo: BMS
MQB: BMS
MLB: BMS";
CM_ SG_ 2029 ISO_OBD_04_Resp_Data "MLBevo: BMS
MQB: BMS
MLB: BMS";
CM_ SG_ 2022 ISO_OBD_05_Req_Data "MLBevo: EMotor
MQB: EMotor
MLB: EMotor";
CM_ SG_ 2030 ISO_OBD_05_Resp_Data "MLBevo: EMotor
MQB: EMotor
MLB: EMotor";
CM_ SG_ 1424 KY_Funkschl_Nr "Funkschlüsselnummer gültig für die Fahrerberechtigung
";
CM_ SG_ 1424 KY_ID_Geb_autorisiert "Authorisierung Schluessel (ID-Geber)
";
CM_ SG_ 1424 KY_ID_Geb_steckt "Schluessel (ID-Geber) im Zuendschloss
";
CM_ SG_ 1424 KY_FFB_Frequenz "Frequenz FFB
";
CM_ SG_ 1424 KY_HF_Aktiv "HF Funkempfang
";
CM_ SG_ 1424 KY_LF_Aktiv "LF Schluesselkommunikation
";
CM_ SG_ 1424 KY_ELV_verr "Verriegelungsstatus ELV

";
CM_ SG_ 1424 KY_ELV_entr "Entriegelungsstatus ELV
";
CM_ SG_ 1424 KY_ELV_enable_Anforderung "Anforderung ELV-Freigabe
";
CM_ SG_ 1424 KY_Valet_Parking "Erkennung Schluessel für Valet Parking
";
CM_ SG_ 1424 KY_Keyless_Verbau "Verbauinfo Keyless 
";
CM_ SG_ 1424 KY_FBS_Fahrer_Hinweise "Kombi Fahrer Hinweise FBS
Audi/VW
0x01 Bitte Lenkung entlasten";
CM_ SG_ 1424 FBS_Warn_Lenkung_def "Kombi Prio Warnung Lenkung defekt
'Fahrzeug abstellen, Lenkung defekt!'
";
CM_ SG_ 1424 FBS_Warn_LenkVerriegelung_def "Kombi Prio Warnung Lenkungsverriegelung defekt
'Lenkungsverriegelung, Werkstatt aufsuchen!'";
CM_ SG_ 1424 FBS_Warn_Schluessel_Batt "Kombi Prio Warnung Schluessel Batterie
'Bitte Schlüsselbatterie wechseln!'";
CM_ SG_ 1424 FBS_Prio_Warn_04 "Kombi Prio Warnung FBS 4";
CM_ SG_ 1424 FBS_Prio_Warn_05 "Kombi Prio Warnung FBS 5";
CM_ SG_ 1424 KY_KYL_Fahrer_Hinweise "Kombi Fahrer Hinweise Keyless
Audi/VW
0x04 Kein Schlüssel erkannt";
CM_ SG_ 1424 KYL_Warn_kein_Schluessel "Kombi Prio Warnung Keyless 
'Schlüssel nicht im Fahrzeug!'
";
CM_ SG_ 1424 KYL_Warn_Kessy_defekt "Kombi Prio Warnung Keyless
'Keyless Go defekt, Zündschloß benutzen'";
CM_ SG_ 1424 KY_KYL_Prio_Warn_03 "Kombi Prio Warnung Keyless 3";
CM_ SG_ 1424 KY_KYL_Prio_Warn_04 "Kombi Prio Warnung Keyless 4";
CM_ SG_ 1424 KY_KYL_Prio_Warn_05 "Kombi Prio Warnung Keyless 5";
CM_ SG_ 1424 KY_Schluessel_Soll "Sollwert der zu lernenden Schluessel";
CM_ SG_ 1424 KY_Schluessel_Ist "Istwert der gelernten Schluessel";
CM_ SG_ 1424 KY_WFS_Safe "Status WFS
";
CM_ SG_ 1424 KY_WFS_LZ "Anforderung aus Lastenheft WFS V
";
CM_ SG_ 1424 KY_StartStopp_Info "Stopp-Freigabe und Start-Anforderung an den Start-Stopp-Koordinator";
CM_ SG_ 1424 KYL_Notzuendschloss "Kessy mit Notzuendschloss verbaut
";
CM_ SG_ 1424 KYL_Warn_Notzuendschloss "Aufforderung an den Benutzer, den Schlüsssel an die Notspule zu halten, wenn Kessy den Schlüssel nicht finden kann
'Keyless Go defekt. Zum Starten den Schlüssel vor das Symbol halten!'";
CM_ SG_ 1424 FBS_KD_Fehler "Kundendienstfehlerspeicher FBS
";
CM_ SG_ 1424 SK_Anf_DTC_Abfrage "Anforderung des Service Key Master an den Datensammler Fehlerspeicherteinträge aus den SG's zu lesen
Für die ersten 10 Botschaften nach CAN-Wakeup muss der Initwert gesendet werden. Grund: Flankenerkennung durch den Datensammler

GW führt bei Flankenwe";
CM_ SG_ 1424 SK_Anf_DTC_Abfrage_sofort "Anforderung des Service Key Master an den Datensammler Fehlerspeicherteinträge aus den SG's zu lesen.
Bei dieser Anforderung wird eine positive Authentifikationsrunde des Komponentenschutz durchgeführt. Eine gerade aktive KS Runde wird abgebrochen. Nach ";
CM_ BO_ 960 "B8/D4/C7";
CM_ SG_ 960 Klemmen_Status_01_CHK "Berechnung siehe Lastenheft 'Kommunikationsabsicherung für FlexRay und CAN'
Endwerte siehe 'Kommunikationsabsicherung für FlexRay und CAN / Anhang C: Tabelle S-PDU Kennungen'";
CM_ SG_ 960 Klemmen_Status_01_BZ "4bit Botschaftszaehler; wird in jeder Sendebotschaft inkrementiert";
CM_ SG_ 960 ZV_verriegelt_extern_soll_02 "Sollzustand: Verriegelung Fahrzeug aussen

_02 für senden in der Klemmenstatusbotschaft
";
CM_ SG_ 960 ZAS_Kl_S "Klemme S: S-Kontakt (Schluessel steckt)
";
CM_ SG_ 960 ZAS_Kl_15 "Klemme 15: Zuendung (SW-Kl.15)
";
CM_ SG_ 960 ZAS_Kl_X "Klemme 75
";
CM_ SG_ 960 ZAS_Kl_50 "Klemme 50: Startwunsch Fahrer
";
CM_ SG_ 960 ZAS_Kl_Infotainment "Separate Klemmeninformation für das Infotainment. Signal entspricht im wesentlichen einer Klemme S Information, kann aber über einen Vor - bzw. Nachlauf zu Klemme S verfügen. 
Ein konkreter Anwendungsfall für einen Nachlauf ist die Abschaltung der Klemme";
CM_ SG_ 959 KL_Drehz_Anh "Drehzahlanhebung vom Motor angefordert

";
CM_ SG_ 959 KL_Vorwarn_Komp_ein "Vorwarnung Kompressor ein; 140ms vorher; Information für Motor zum Aufbau Momentenreserve";
CM_ SG_ 959 KL_Handshake_BEM "Handshake Klima / BEM (Heizleistungsänderung)
";
CM_ SG_ 959 KL_Vorwarn_HHS_ein "Vorwarnung Heckscheibenheizung ein; Information für Motor zum Aufbau Momentenreserve";
CM_ SG_ 959 KL_Vorwarn_HFS_ein "Vorwarnung Frontscheibenheizung ein (Info für Motor zum Aufbau Momentenreserve), aktuell keine HFS für B8 geplant
";
CM_ SG_ 959 KL_Vorwarn_Zuheizer_ein "Vorwarnung Zuheizerbetrieb
";
CM_ SG_ 959 KL_KD_Fehler "Status Kundendienstfehlerspeichereinträge

";
CM_ SG_ 959 KL_Comp_rev_rq "Requested compressor revolution
over 8600 rpm = compressor stop";
CM_ SG_ 959 KL_Charisma_FahrPr "Aktuelles Fahrprogramm des Charisma-Teilnehmers
";
CM_ SG_ 959 KL_Charisma_Status "Charisma Systemstatus des Charisma-Teilnehmers

Wert 0x3 ist nur für Fahrzeuge ab MQB relevant";
CM_ SG_ 959 KL_Charisma_Umschaltung "Erkennung  Umschaltaufforderung des Charisma-Teilnehmers";
CM_ SG_ 959 KL_Last_Kompr "Aktuelles Verlustmoment der Klimaanlage bezogen auf die Kurbelwelle. Wird der Klimakompressor nicht angesteuert, ist das Schleppmoment bezogen auf die Kurbelwelle zu senden.";
CM_ SG_ 959 KL_Leistung_Hzg_Soll "Ansteuerung intelligentes 1600 W PTC oder Schnellheizung

Nur für D4 relevant
";
CM_ SG_ 959 KL_Anf_KL "Anforderung Kühlerlüfter der Klimaanlage in Prozent

";
CM_ SG_ 959 KL_4_Zonen "Vorhalt für D4:
Information, ob 4-Zonen-Klimaanlage verbaut

";
CM_ SG_ 959 KL_AC_Schalter "AC Schalter
";
CM_ SG_ 959 KL_Zustand "Betrieb Klimaanlage
";
CM_ SG_ 959 KL_Thermomanagement "Stufen des Thermomanagements";
CM_ SG_ 959 KL_Comp_enable "Enable to start for compressor
After 1 second when High-voltage becomes available, turn on '1'";
CM_ SG_ 959 KL_StartStopp_Info "Stopp-Freigabe und Start-Anforderung an den Start-Stopp-Koordinator";
CM_ SG_ 959 KL_el_Zuheizer_Stufe "Vorgabe für Motorsteuergeraet PTC-Stufe; im MLB-B8 und MQB nur Stufe 0...3

";
CM_ SG_ 959 KL_Diag_Absperrvent "Das Klimabedienteil führt eine elektrische Diagnose des  EUVs durch, durch das das Heizungsabsperrventil angesteuert wird. Es übermittelt das Ergebnis an das MSG (Standard-4Bit-Status, nicht alle Zustände müssen genutzt werden; so sind z.B. die Out of Ran";
CM_ SG_ 959 KL_nachtr_Stopp_Anf "Dieses Signal dient dem Motor als Trigger, dass ein nachträglicher Motorstopp eingeleitet werden kann, wenn es die Bedingungen des StSt Koordinators dies zulassen. ";
CM_ SG_ 1636 KL_Stromsparmodus "Stromsparmodus (durch BEM)
";
CM_ SG_ 1636 KL_Spg_Hzg_aus "Anforderung: Spiegelheizung ausschalten
";
CM_ SG_ 1636 KL_AQS_Empfindlichkeit "Vorgabe der Empfindlichkeitsstufe für AQS
";
CM_ SG_ 1636 KL_SIH_Soll_li "Einstellung Sitzheizung Fahrer (0...6)";
CM_ SG_ 1636 KL_SIH_Takt_li "Ein-Aus Taktung Sitzheizung Fahrer";
CM_ SG_ 1636 KL_SIL_Soll_li "Einstellung Sitzlüftung Fahrer (0...6)";
CM_ SG_ 1636 KL_LRH_aus "Heizleistungsfreigabe für Lenkradheizung";
CM_ SG_ 1636 KL_SIH_Soll_re "Einstellung Sitzheizung Beifahrer (0...6)";
CM_ SG_ 1636 KL_SIH_Takt_re "Ein-Aus Taktung Sitzheizung Beifahrer
";
CM_ SG_ 1636 KL_SIL_Soll_re "Einstellung Sitzlüftung Beifahrer (0...6)";
CM_ SG_ 1636 KL_Beschlagsgefahr "Beschlagsgefahr auf der Frontscheibe im Bereich des Spiegelfusses. Dient zur präventiven Ansteuerung der  Kamera-Scheibenheizung, um Kamera-Blindheit zu vermeiden
PHEV: volle Leistungsfreigabe 
HV Heizer und HV EKK bei Scheibenbeschlag ";
CM_ SG_ 1636 KL_HSH_ein_Soll "Fahrerwunsch (Anforderung) Heckscheibenheizung
";
CM_ SG_ 1636 KL_HSH_Taktung "Ein-Aus Taktung der Heckscheibenheizung ";
CM_ SG_ 1636 KL_Zuheizer_Freigabe "Freigabe Zuheizer
";
CM_ SG_ 1636 KL_ZHE_Status "Status elektrischer Zuheizer
";
CM_ SG_ 1636 KL_FSH_Status "Status Frontscheibenheizung
";
CM_ SG_ 1636 KL_LRH_on_off "Das Signal soll den Kundenwunsch zur Aktivierung / Deaktivierung der Lenkradheizung übertragen.

Derzeit nur bei VW verwendet";
CM_ SG_ 1636 KL_Umluftklappe_Status "Status Umluftklappe

";
CM_ SG_ 1636 KL_Geblaese_Status "Status Geblaese









";
CM_ SG_ 1636 KL_I_Geblaese "Stromaufnahme Gebläse";
CM_ SG_ 1636 KL_Kompressorstrom_soll "Sollvorgabe Klima-Kompressorstrom
";
CM_ SG_ 1636 KL_FSH_P_Soll "Sollleistung Frontscheibenheizung";
CM_ SG_ 1646 KL_STL_aktiv "Betriebsstatus Standlueftung
";
CM_ SG_ 1646 KL_STH_aktiv "Betriebsstatus Standheizung
";
CM_ SG_ 1646 KL_Solarluefter_aktiv "Betriebsstatus Solarluefter
";
CM_ SG_ 1646 KL_Umluft_Taste "Betaetigung Umlufttaste
";
CM_ SG_ 1646 KL_Geblaese_Fond_Status "Status Geblaese









";
CM_ SG_ 1646 KL_STH_Ansteuerung "Ansteuerung STH

";
CM_ SG_ 1646 KL_STH_Betriebsdauer "Betriebsdauer STH";
CM_ SG_ 1646 KL_Magnetventil "Anforderung des Bypassventils.";
CM_ SG_ 1646 KL_WaPu "Ansteuerung der Standheizungswasserpumpe";
CM_ SG_ 1646 KL_Freigabe_KRH_li "Freigabe Kopfraumheizung links
(0 wird gesendet bei Motor aus und während des Lastabwurfes, die Stufen 1-3 werden gesendet, wenn KRH-Stufen angefordert werden und das dynamische Energiemanagement genügend Leistung bereitstellt)";
CM_ SG_ 1646 KL_Freigabe_KRH_re "Freigabe Kopfraumheizung rechts
(0 wird gesendet bei Motor aus und während des Lastabwurfes, die Stufen 1-3 werden gesendet, wenn KRH-Stufen angefordert werden und das dynamische Energiemanagement genügend Leistung bereitstellt)";
CM_ SG_ 1646 KL_BCmE_Livetip_Freigabe "Status der Klimaanlage. 
Zeigt an, ob der Livetip 'Fenster schließen wegen Ineffizienz Klimaanlage' sinvollerweise angezeigt werden soll

MQB: nur Audi relevant";
CM_ SG_ 1646 KL_HYB_ASV_hinten_schliessen_Anf "Anforderung der Klima an das BMS, das Absperrventil des Kältemittelkreislaufs zur Batteriekühlung zu schliessen";
CM_ SG_ 1646 KL_HYB_ASV_vorne_schliessen_Anf "Anforderung der Klima an das BMS, das Absperrventil des Kältemittelkreislaufs der Klimaanlage zu schliessen";
CM_ SG_ 1646 KL_HYB_Spuelbetrieb_Freigabe "Status der Klimaanlage. Zeigt dem BMS an, ob der Spülbetrieb möglich ist";
CM_ SG_ 1646 KL_Fehler_ElWaPu "Bei der Diagnose der Heizungspumpe wurde ein Fehler festgestellt.";
CM_ SG_ 1646 KL_Innen_Temp "Innentemperatur

";
CM_ SG_ 1646 KL_Sonnenintensitaet "gemittelte eingestrahlte Leistung in W/m2";
CM_ SG_ 1646 KL_AussenTemp_WK "Aussentemperatur (Vorhalt VW, Nicht im Audi B8/D4/C7)
";
CM_ SG_ 1625 EKL_KD_Fehler "Bei gesetztem Bit ist mindestens ein Kundendienstfehler eingetragen";
CM_ SG_ 1625 EKL_Comp_SCI_com_stat "'00' normal
'x1' CAN_error (abnormal)
'1x' Inverter_error";
CM_ SG_ 1625 EKL_Comp_output_stat "Diagnosis series 1 'Output'
'0' normal
'1' output line short
'2' output line cut out
'3' abnormal current detection";
CM_ SG_ 1625 EKL_Comp_main_stat "Real compressor status not CAN board status";
CM_ SG_ 1625 EKL_Comp_ovld_stat "Diagnosis series 1 'Over load'
0 normal
1 voltage restriction
2 current restriction
3 software over current
4 over load
6 over input current";
CM_ SG_ 1625 EKL_Comp_Inv_stat "Diagnosis series 2 'Startability'
'0' normal
'1' start fail
'2' temperature protection
'3' system abnormal stop";
CM_ SG_ 1625 EKL_Comp_photo_temp_stat "Diagnosis series 2 'Inverter temp.'
'0' normal
'1' over heat L
'2' over heat S
'3' sermister abnormal";
CM_ SG_ 1625 EKL_Comp_photo_temp "IGBT temp. measured by inverter.
Photo coupler temp. is not  measured in compressor temp. of IGBT (same as EK1_Comp_Inv_temp) will be sent";
CM_ SG_ 1625 EKL_Comp_current "Compressor input current";
CM_ SG_ 1625 EKL_Comp_rev_stat "compressor real revolution
0-8624 rpm is outputted
'output = (actual speed + 25) / 50'   speed over 8625rpm: '172'";
CM_ BO_ 779 "MLB";
CM_ SG_ 779 KBI_ABS_Lampe "ABS-Sicherheits-Lampe wurde eingeschaltet.";
CM_ SG_ 779 KBI_ESP_Lampe "ESP-Sicherheits-Lampe wurde eingeschaltet ";
CM_ SG_ 779 KBI_BKL_Lampe "Sicherheits-Lampe Bremskontrolle wurde eingeschaltet;
";
CM_ SG_ 779 KBI_Airbag_Lampe "Airbag Sicherheits-Lampe wurde eingeschaltet ";
CM_ SG_ 779 KBI_SILA_gueltig "Rückmeldeinformation (Bit 1-6) ist gültig";
CM_ SG_ 779 KBI_Lenkung_Lampe "Sicherheits-Lampe der Lenkung (Lenkhilfe EPS, Audi-Dynamic-Steering ...) wurde eingeschaltet.

0x0 = Lenkungs-Lampe aus
0x1 = Lenkungs-Lampe ein";
CM_ SG_ 779 KBI_Vorglueh_System_Lampe "Rückmeldung der Vorglühlampe bzw. Motor Systemlampe (MO_Systemlampe) an den Motor (bei Diesel und Otto!). Hardwaremässig gleiche LED im Kombi (EPC- oder Glühwendel), Unterscheidung nur über Ziffernblatt.";
CM_ SG_ 779 KBI_NV_in_Anzeige "Das Bit gibt dem NV die Information, ob NV-Bild im Kombi in der Anzeige ist. (Information ist notwendig um Kontrasverstellungen nur dann zuzulassen, wenn der Fahrer das Feedback über das  Kombidisplay bekommt.)";
CM_ SG_ 779 KBI_Anzeigestatus_ACC "Status der ACC-Anzeige im nicht permanenten Displaybereich";
CM_ SG_ 779 KBI_Oeldruck_Schalter "Das Signal bildet den Status des Öldrucks über den am Kombi angeschlossenen Öldruckschalter ab.";
CM_ SG_ 779 KBI_Tankwarnung "Fahrer wird gewarnt, dass er den Reservebereich erreicht hat. Fzg.spezifische Warnschwelle";
CM_ SG_ 779 KBI_MFA_v_Einheit_01 "Einheit der Geschwindigkeit, die vom Fahrer im Car-Menü gewählt wurde. Veränderliche Grösse, im Gegensatz zur Einheit des Tachokranzes.";
CM_ SG_ 779 KBI_im_Stellgliedtest "Kombi im Stellgliedtest, Signal muss eingelesen werden, um Fehlfunktion aufgrund der Bewegung der Stellglieder (Drehzahlmesser, Tacho) des Kombis zu verhindern";
CM_ SG_ 779 KBI_Variante_USA "In diesem Signal wird die HW-Variante des Kombis ausgegeben, ACC plausibilisiert auf dieses Signal hin seine US-Codierung";
CM_ SG_ 779 KBI_Oeldruckwarnung "Öldruckwarnung im Kombi aktiv";
CM_ SG_ 779 KBI_Handbremse "Handbremsen-Information vom Kombi.
Das Signal bezieht sich ausschließlich auf den Zustand der konventionellen Handbremse.";
CM_ SG_ 779 KBI_V_Digital "Ausgabe der im Kombi angezeigten digitalen Geschwindigkeit.

Einheit ist im KBI_MFA_v_Einheit_01 definiert";
CM_ SG_ 779 KBI_PLA_in_Anzeige "Das Signal wird als aktive Rückmeldung genutzt, ob die Info des PLA im Kombi angezeigt wird. Wenn nach Anforderung des Displays das Signal zweimal auf 0 ist, wird der Parkvorgang abgebrochen.
Ein Kombi, dass PLA Anzeige nicht unterstützt, schickt dauerha";
CM_ SG_ 779 KBI_Anzeigefehler_NV "Über dieses Signal teilt das Kombiinstrument dem Nightvision-Steuergerät mit, dass ein Fehler vom Kombiinstrument diagnostiziert wurde, der zur Abschaltung der Nightvision-Funktion führen muss.";
CM_ SG_ 779 KBI_angez_Geschw "Im Tacho angezeigte Geschwindigkeit inklusive der Voreilung

";
CM_ SG_ 779 KBI_Einheit_Tacho "Information, ob es sich um Meilen- oder Kmh-Kombi handelt, Einheit des Tachos entspricht dem Zifferblatt, Grösse ist nicht veränderlich";
CM_ SG_ 779 KBI_Konsistenz_ACC "Rückmeldung an ACC, dass die Botschaften zur Ansteuerung von Anzeigen nicht bzw. nicht konsistent empfangen wurden (Timeout-, BZ-, CHK- und DLC-Fehler)                                                                                                        ";
CM_ SG_ 779 KBI_Fehler_Anzeige_ACC "Rückmeldung an ACC, dass mindestens eine der ACC-relevanten Anzeigen -rote Fahrerübernahme, Mitteldisplay, Gong - fehlerhaft sind.";
CM_ SG_ 779 KBI_Anzeigefehler_SWA "Signal bezieht sich nur auf die SWA-Lampe, Vorhalt für Kombis mit SWA-Lampe. ";
CM_ BO_ 1719 "MLB";
CM_ SG_ 1719 KBI_Kilometerstand "Fehler wird ausgegeben, falls Kilometerstand nicht restaurierbar
";
CM_ SG_ 1719 KBI_Standzeit "Low Byte 4, High Byte 5;
Standzeit in 4 Sekunden Auflösung; mit diesen 15 Bits läßt sich eine Zeit bis 36 Stunden, 24 Minuten und 28 Sekunden darstellen; 
Der Standzeitzähler wird mit KL15_Aus gestartet, er bleibt 2 Minuten vor einem Überlauf stehen, di";
CM_ SG_ 1719 KBI_Inhalt_Tank "Restmenge 2 bzw. 2,5l nicht auflösbar

0x7F = Fehler

";
CM_ SG_ 1719 KBI_FStatus_Tank "Signal wird gesetzt:

a) Während der Fehlerentprellzeit (20 s Entprellung)

b) Bei erkanntem Fehler wird der Tankinhalt während der laufenden KL15-Phase über den 
    Verbrauch zurückgerechnet. In dieser Zeit ist das Bit ebenfalls gesetzt. Nach einem";
CM_ SG_ 1719 KBI_Oelwechsel_durchgefuehrt "Nach einen Ölwechsel (Service) ist die Ethanol Warmfahrwarnung zu unterdrücken.";
CM_ SG_ 1719 KBI_QBit_Aussen_Temp_gef "0x0 = gültiger Wert
0x1 = Ersatz-, Init- oder Fehlerwert";
CM_ SG_ 1720 KBI_Reifenumfang "Mittlerer Radumfang aus der K-Zahl gerechnet in Millimeter.  Byte 2 Bit 5,4 reserviert, Byte 2 Bit 3..0 und Byte 1 Bit 7..0; Wertebereich 0..4096 mm
";
CM_ SG_ 1720 KBI_BCmE_aktiv "Anzeige BCmE aktiv (BCmE-Screen oder Einsparhinweis in der Anzeige)";
CM_ SG_ 1720 KBI_Sparhinweis_quittiert "angezeigter Sparhinweis ist quittiert. Signal wird nach zwei Sendebotschaften wieder auf '0' gesetzt.";
CM_ SG_ 1720 KBI_Tankfuellstand_Prozent "Tankfüllstand in %";
CM_ SG_ 285 EPS_02_CRC "Für MLB:
'Berechnung siehe Lastenheft 'Kommunikationsabsicherung für FlexRay und CAN''

Ab MQB und MLBevo:
'Berechnung siehe Lastenheft 'End-to-End Kommunikationsabsicherung''

Endwerte siehe Begleitdokument 'S-PDU Kennungsfolgen'
";
CM_ SG_ 285 EPS_Notlauf "Bit-Feld zeigt an, dass sich die Lenkhilfe in einem Notlaufprogramm 
befindet und durch welche Ursache dieses aktiviert wurde; 
das Betriebsverhalten der Lenkhilfe wird an das bestehende Defizit angepasst.

Erläuterung Notlauf-Ursachen:

- Unterspan";
CM_ SG_ 285 EPS_Lastinfo "entspricht Stromaufnahme des Lenkhilfe-SG, Auflösung = 1A";
CM_ SG_ 285 EPS_Unterstuetzungsleistung "Die Unterstützungsleistung gibt prozentual an, in welchem Verhältnis die tatsächlich abgegebene Leistung zur Nominalleistung steht, d.h.:

0% = keine Servounterstützung

100% = maximale Servounterstützung (Nominalleistung);

0% < Unterstützungsleist";
CM_ SG_ 285 EPS_Drehzahlreserve "Signal beschreibt wieviel Drehzahlreserve in EPS besteht (abhängig von Bordnetzspannung)";
CM_ SG_ 285 EPS_VZ_Drehzahlreserve "Vorzeichen zur Drehzahlsreserve";
CM_ SG_ 285 EPS_Leistungsanforderung "Signal informiert BEM, daß EPS einen erhöhten Leistungs-/Spannungsbedarf hat";
CM_ SG_ 285 EPS_StartStopp_Info "Das Signal gibt eine Motorstoppempfehlung für StartStop. 
Bei einem zu großem Handlenkmoment von X Nm wird eine Empfehlung ausgesprochen keinen Motorstopp durchzuführen.";
CM_ SG_ 285 EPS_Motorstartverzoegerung "Das Signal gibt eine Empfehlung, ob der Motorstart verzögert werden sollte. Es beschreibt aber kein Motorstartverbot. Der Motor darf trotz gesetztem Bit einen Motorstart vollziehen.";
CM_ BO_ 1137 "MLB";
CM_ SG_ 1137 Licht_hinten_01_BZ "überlaufender 4bit Botschaftszaehler; wird in jeder Sendebotschaft inkrementiert";
CM_ SG_ 1137 BCM2_Bremsl_durch_ECD "Bremslicht (ECD-Bremsung)
";
CM_ SG_ 1137 LH_Aussenlicht_def "Aussenlicht kann nicht mehr korrekt angesteuert werden (EEPROM Codierung kann nicht mehr ausgelesen werden)
";
CM_ SG_ 1137 LH_Standlicht_H_aktiv "Standlicht hinten
";
CM_ SG_ 1137 LH_Parklicht_HL_aktiv "Parklicht hinten links 
";
CM_ SG_ 1137 LH_Parklicht_HR_aktiv "Parklicht hinten rechts 
";
CM_ SG_ 1137 LH_Bremslicht_H_aktiv "Bremslicht hinten
";
CM_ SG_ 1137 LH_Nebelschluss_aktiv "Nebelschlusslicht
";
CM_ SG_ 1137 LH_Rueckfahrlicht_aktiv "Rueckfahrlicht
";
CM_ SG_ 1137 LH_Blinker_HL_akt "Blinker hinten links
";
CM_ SG_ 1137 LH_Blinker_HR_akt "Blinker hinten rechts
";
CM_ SG_ 1137 LH_Blinker_li_def "Fehlerstatus Blinker hinten links
";
CM_ SG_ 1137 LH_Bremsl_li_def "Fehlerstatus Bremslicht hinten links (Detektion Einzelausfall)
";
CM_ SG_ 1137 LH_Schlusslicht_li_def "Fehlererkennung Schlusslicht hinten links
";
CM_ SG_ 1137 LH_Rueckf_li_def "Fehlererkennung Rückfahrlicht hinten links
";
CM_ SG_ 1137 LH_Nebel_li_def "Fehlererkennung Nebelschlusslicht hinten links
";
CM_ SG_ 1137 LH_Schluss_Brems_Nebel_li_def "Signal wird gesetzt, wenn eine Unterbrechung oder  ein Kurzschluss am Lampenausgang für Schluss_Brems_Nebelschlusslicht erkannt wird.";
CM_ SG_ 1137 LH_Schluss_Brems_Nebel_re_def "Signal wird gesetzt, wenn eine Unterbrechung oder  ein Kurzschluss am Lampenausgang für Schluss_Brems_Nebelschlusslicht erkannt wird.";
CM_ SG_ 1137 LH_Schluss_Brems_li_def "Konfiguration SL+ BRL + PL links und SL+ BRL  links
";
CM_ SG_ 1137 LH_Schluss_Nebel_li_def "Konfiguration SL + NSL links oder SL + NSL + PL links
";
CM_ SG_ 1137 LH_SL_BRL_BLK_li_def "Konfiguration SL + BRL + BLK links oder SL + BRL + BLK + PL links
";
CM_ SG_ 1137 LH_Brems_Blk_li_def "Konfiguration BRL + BLK links 
";
CM_ SG_ 1137 LH_Blinker_re_def "Fehlerstatus Blinker hinten rechts
";
CM_ SG_ 1137 LH_Bremsl_re_def "Fehlerstatus Bremslicht hinten rechts  (Detektion Einzelausfall)
";
CM_ SG_ 1137 LH_Schlusslicht_re_def "Fehlererkennung Schlusslicht hinten rechts
";
CM_ SG_ 1137 LH_Rueckf_re_def "Fehlererkennung Rückfahrlicht hinten rechts
";
CM_ SG_ 1137 LH_Nebel_re_def "Fehlererkennung Nebelschlusslicht hinten rechts
";
CM_ SG_ 1137 LH_Schluss_Brems_re_def "Konfiguration SL+ BRL + PL rechts und SL+ BRL  rechts
";
CM_ SG_ 1137 LH_Schluss_Nebel_re_def "Konfiguration SL + NSL rechts oder SL + NSL + PL rechts
";
CM_ SG_ 1137 LH_SL_BRL_BLK_re_def "Konfiguration SL + BRL + BLK rechts oder SL + BRL + BLK + PL rechts
";
CM_ SG_ 1137 LH_Brems_Blk_re_def "Konfiguration BRL + BLK rechts
";
CM_ SG_ 1137 LH_Kennzl_def "Fehlerstatus Kennzeichenbeleuchtung hinten
";
CM_ SG_ 1137 LH_3_Bremsl_def "Fehlerstatus 3. Bremsleuchte
";
CM_ SG_ 1137 LH_Nebel_mi_def "Fehlererkennung Nebelschlusslicht hinten Mitte


";
CM_ SG_ 1137 LH_Rueckf_mi_def "Fehlererkennung Rückfahrlicht Mitte
";
CM_ SG_ 1137 LH_Bremsl_li_ges_def "Fehlerstatus Bremslicht hinten links (Detektion Totalausfall)
";
CM_ SG_ 1137 LH_Bremsl_re_ges_def "Fehlerstatus Bremslicht hinten links (Detektion Totalausfall)
";
CM_ BO_ 267 "Botschaft vom Lenkstockschalter, enthält Information zur Bedienung der GRA und ACC, sowie MFL-Tasten zum Getriebe für TipTronic.";
CM_ SG_ 267 LS_01_CHK "Berechnung siehe Lastenheft 'Kommunikationsabsicherung für FlexRay und CAN'
Endwerte siehe 'Kommunikationsabsicherung für FlexRay und CAN / Anhang C: Tabelle S-PDU Kennungen'";
CM_ SG_ 267 LS_Abbrechen "GRA : aus mit speichern
ACC : Soft aus";
CM_ SG_ 267 LS_Limiter "Limiter setzen";
CM_ SG_ 267 LS_Tip_Setzen "ACC : Tippschalter Set";
CM_ SG_ 267 LS_Tip_Hoch "GRA : Tip Up 
ACC : Tip Up";
CM_ SG_ 267 LS_Tip_Runter "GRA : Tip Down 
ACC : Tip Down";
CM_ SG_ 267 LS_Tip_Wiederaufnahme "ACC : Tippschalter Wiederaufnahme";
CM_ SG_ 267 LS_Verstellung_Zeitluecke "Verstellung der Zeitlücke für ACC

DIST -1 = Zeitluecke um 1 Stufe kleiner
DIST +1 = Zeitluecke um 1 Stufe groeßer";
CM_ SG_ 267 MFL_Tip_Down "MFL-Tiptronic Tasten vom MFL für Getriebe
    0x0 = kein Tip_Down
    0x1 = Tip_Down";
CM_ SG_ 267 MFL_Tip_Up "MFL-Tiptronic Tasten vom MFL für Getriebe
    0x0 = kein Tip_Up
    0x1 = Tip_Up";
CM_ SG_ 267 LS_Fehler "0 = in Ordnung
1 = Fehler Bedienteil";
CM_ SG_ 267 LS_Tip_Stufe_2 "Signal zeigt an, dass der zweistufige GRA/ACC-Hebel in der 2. Tip-Stufe betätigt wird. Das Signal wird nur gleichzeitig mit dem Signal LS_Tip_Hoch oder LS_Tip_Runter gesetzt, wobei die Bits LS_Tip_Hoch bzw. LS_Tip_Runter die Richtung der Hebelbetätigung a";
CM_ SG_ 267 LS_GRA_ACC_2stufig "Verbau-Information zum zweistufigen GRA/ACC-Hebel; 
Übergangslösung für MLB1, soll ab MQB durch ein Signal ersetzt werden, dass weitere Bedienteilvarianten (z.B. 4-Positions-Hebel) kennzeichnen kann.";
CM_ SG_ 267 MFL_M_Taste "Taster für Umschaltung Automatik/manuelles Schalten (Tiptronic)";
CM_ SG_ 134 LWI_01_CHK "Berechnung siehe Lastenheft 'Kommunikationsabsicherung für FlexRay und CAN'
Endwerte siehe 'Kommunikationsabsicherung für FlexRay und CAN / Anhang C: Tabelle S-PDU Kennungen'";
CM_ SG_ 134 LWI_QBit_Sub_Daten "Es gilt die Signalspezifikation laut LAH";
CM_ SG_ 134 LWI_QBit_Lenkradwinkel "Das QBit wird auch bei nicht abgeglichenem Lenkradwinkelsensor gesetzt";
CM_ SG_ 134 LWI_Lenkradwinkel "Wertebereich = +/- 800 Grad
Auflösung = 0,1 Grad
ACHTUNG: spezifizierte Interne Auflösung des Sensors beträgt aber nur Schrittweite 0,5 Grad!

Hinweis:
MLB: Zusätzlich gestellte Winkel bei Dynamiklenkung beachten !
MQB: Nicht konstante Lenkübersetzu";
CM_ SG_ 134 LWI_VZ_Lenkradwinkel "Vorzeichen Lenkradwinkel gemäss DIN70000; 
Nullstellung = +0";
CM_ SG_ 134 LWI_VZ_Lenkradw_Geschw "Vorzeichen Lenkradwinkelgeschwindigkeit gemäss DIN70000; 
Nullstellung = +0";
CM_ SG_ 134 LWI_Lenkradw_Geschw "Wertebereich = +/- 2500 Grad/s
Auflösung = 5 Grad/s

Hinweis: Zusätzlich gestellte Winkel bei Dynamiklenkung beachten !";
CM_ SG_ 134 LWI_Sub_Daten "Verschlüsseltes Datenpaket vom Sub-Rechner des LWS, Verwendung nur durch SCU und ESP_ADS
Verwendung gemäß 'Sicherheitsanforderungen an Empfängersteuergeräte'

Im MLB gilt die Signalspezifikation: LAH 8K0953B";
CM_ SG_ 134 LWI_01_CRC "Für MLB:
'Berechnung siehe Lastenheft 'Kommunikationsabsicherung für FlexRay und CAN''

Ab MQB und MLBevo:
'Berechnung siehe Lastenheft 'End-to-End Kommunikationsabsicherung'

Endwerte siehe Begleitdokument 'S-PDU Kennungsfolgen'";
CM_ SG_ 128 Motor_01_CHK "Berechnung siehe Lastenheft 'Kommunikationsabsicherung für FlexRay und CAN'
Endwerte siehe 'Kommunikationsabsicherung für FlexRay und CAN / Anhang C: Tabelle S-PDU Kennungen'


";
CM_ SG_ 128 MO_Mom_o_ex "Achtung:
Einheitenloser CAN-Wert.
Faktor in MO_Faktor_Momente in Motor_Code_01 beachten!

Indiziertes Motormoment ohne externe Eingriffe (ASR, MSR, Getriebe ...) aber inklusive integrierter GRA";
CM_ SG_ 128 MO_Mom_m_ex "Achtung:
Einheitenloser CAN-Wert.
Faktor in MO_Faktor_Momente in Motor_Code_01 beachten!

Indiziertes Motormoment, d.h. idealisiertes berechnetes Moment ohne mechanische Verluste, aber mit externen Eingriffen.";
CM_ SG_ 128 MO_Mom_Verlust "Achtung:
Einheitenloser CAN-Wert.
Faktor in MO_Faktor_Momente in Motor_Code_01 beachten!

Beinhaltet z.Zt. Reibung vom Motor und Klimakompressor, beim TDI z.T. auch die Generatorverluste";
CM_ SG_ 128 MO_Mom_Begrenzung "Achtung:
Einheitenloser CAN-Wert.
Faktor in MO_Faktor_Momente in Motor_Code_01 beachten!

Inneres maximal mögliches Moment bei einer Drehzahl (z.B. Rauchbegrenzung oder Fehlerfall)";
CM_ SG_ 128 MO_Mom_Fahrerwunsch "Achtung:
Einheitenloser CAN-Wert.
Faktor in MO_Faktor_Momente in Motor_Code_01 beachten!

Moment vor Filter, nutzbar zur Zug- / Schuberkennung beim Getriebe (beim Diesel identisch mit innerem Moment ohne externe Eingriffe)";
CM_ SG_ 128 MO_Kickdown "Es gilt: Signalspec MO_Kickdown v1.0";
CM_ SG_ 128 MO_KD_Fehler "Kundendienstfehlerspeicherbit";
CM_ SG_ 129 Motor_02_CHK "Berechnung siehe Lastenheft 'Kommunikationsabsicherung für FlexRay und CAN'
Endwerte siehe 'Kommunikationsabsicherung für FlexRay und CAN / Anhang C: Tabelle S-PDU Kennungen'";
CM_ SG_ 129 MO_Mom_ZWR "Minimales Motormoment bei Zündwinkelrücknahme.

Achtung:
Einheitenloser CAN-Wert.
Faktor in MO_Faktor_Momente in Motor_Code_01 beachten!";
CM_ SG_ 129 MO_Mom_Soll "Achtung:
Einheitenloser CAN-Wert.
Faktor in MO_Faktor_Momente in Motor_Code_01 beachten!

Sollmoment ohne P und D Anteil des Leerlaufreglers, ohne Antiruckelfunktion und ohne Getriebeeingriff";
CM_ SG_ 129 MO_Mom_Ist "Achtung:
Einheitenloser CAN-Wert.
Faktor in MO_Faktor_Momente in Motor_Code_01 beachten!

Istmoment ohne P und D Anteil des Leerlaufreglers, ohne Antiruckelfunktion und ohne Getriebeeingriff";
CM_ SG_ 129 MO_Status_Zylabschalt_01 "Statusbit: Motor ist in Zylinderabschaltregelung";
CM_ SG_ 129 MO_Status_Normalbetrieb_01 "Das Motorsteuergerät sendet das Informationsbit, wenn die Initialisierungsphase des Steuergerätes abgeschlossen ist. Zusätzlich muss die Klemme 15 eingeschalten sein und eine applizierbare Mindestdrehzahlschwelle (Kennlinie in Abh. von der Kühlwassertempe";
CM_ SG_ 129 MO_StartStopp_Status "Aktivitätsstatus Start/Stopp-Koordinator
HYBRID:
Wenn MO_Hybridfahrzeug = 1 gilt:
Signal bezieht sich nur auf den Verbrennungsmotor, nicht auf den Hybridantrieb
";
CM_ SG_ 129 MO_StartStopp_Motorstopp "Motor-Stopp durch Start/Stopp-Koordinator
HYBRID:
Wenn MO_Hybridfahrzeug = 1 gilt:
Verbrennungsmotor durch Hybrid-Koordinator im MSG ausgeschaltet. 
Die definierten Start/Stopp-Signale beziehen sich nur auf den Verbrennungsmotor!";
CM_ SG_ 129 MO_StartStopp_Wiederstart "Motorwiederstart durch Start/Stopp-Koordinator
HYBRID:
Wenn MO_Hybridfahrzeug =1 gilt:
Warnung vor Spannungseinbruch beim Zustart des Verbrennungsmotors. 
-nicht relevant, da derzeit kein Start über 12V-Starter geplant-
Dieses Signal wird nur vom Hyb";
CM_ SG_ 129 MO_Ext_E_Fahrt_aktiv "Funktionsrückmeldung zum erw. E-Fahr-Betrieb über Lampe/LED im E-Mode-Taster";
CM_ SG_ 129 MO_Gangposition "MLB:
Stellung des Wählhebels in der Schaltgasse des Handschaltgetriebes.
MLBevo: 
Ausweitung der Bedienung auch auf Automatikgetriebe;
Routing des Signals GE_Fahrstufe: 
1. Position_R (dez. 6) auf MO_Gangposition: Gang_R (dez. 13) wegen Entfall Signa";
CM_ SG_ 129 MO_StartStopp_Fahrerwunsch "Fahreraktivität Start/Stop";
CM_ SG_ 129 MO_StartStopp_StoppVorbereitung "Zeigt allen aktiven Start-/Stoppteilnehmern einen möglichen Motorstopp im Anhaltevorgang an (Empfänger notwendige Vorbereitungen treffen)
Es liegen keine Vetos vor.";
CM_ SG_ 129 MO_Momentenintegral "100 %  entspricht volle Verfügbarkeit aktuell vorhanden. 0 % entspricht Integral bis Limit gefüllt, erhöhender Eingriff kann aktuell nicht berücksichtigt werden oder erhöhender Eingriff ist in diesem Projekt nicht möglich (applikativ deaktiviert) oder auf";
CM_ BO_ 261 "Motor_03:

Im B8/Q5: 20ms

sonst: 10ms";
CM_ SG_ 261 Motor_03_CHK "Berechnung siehe Lastenheft 'Kommunikationsabsicherung für FlexRay und CAN'
Endwerte siehe 'Kommunikationsabsicherung für FlexRay und CAN / Anhang C: Tabelle S-PDU Kennungen'";
CM_ SG_ 261 Motor_03_BZ "AUDI D4: Zykluszeit: 10ms (siehe Zykluszeit schnell/Cycletime Fast)

Achtung:
Reduktion der Zykluszeit Motor_03 auf 10ms geplant.
Projektabhängig soll künftig mit 10ms gesendet werden.
Empfänger die in weiteren Konzern-Projekten eingesetzt werden müs";
CM_ SG_ 261 MO_QBit_Fahrpedalwerte_01 "AUDI D4: Zykluszeit: 10ms (siehe Zykluszeit schnell/Cycletime Fast)

QBit für beide Fahrpedalwerte des Motors (Fahrpedalrohsignal für ESP, EPB, ACC; Fahrpedalwert für Getriebe)

Achtung:
Reduktion der Zykluszeit Motor_03 auf 10ms geplant.
Projektabh";
CM_ SG_ 261 MO_QBit_Motormomente "AUDI D4: Zykluszeit: 10ms (siehe Zykluszeit schnell/Cycletime Fast)

Ungenaue Momentenangaben, weil die Momente aus Ersatzwerten berechnet wurden (z.B. HFM ausgefallen). Qualifizierungsbit für die Motormomente.

Achtung:
Reduktion der Zykluszeit Moto";
CM_ SG_ 261 MO_QBit_Fahrer_bremst "MLB:
AUDI D4: Zykluszeit: 10ms (siehe Zykluszeit schnell/Cycletime Fast)

Achtung:
Reduktion der Zykluszeit Motor_03 auf 10ms geplant.
Projektabhängig soll künftig mit 10ms gesendet werden.
Empfänger die in weiteren Konzern-Projekten eingesetzt werd";
CM_ SG_ 261 MO_QBit_Drehzahl_01 "AUDI D4: Zykluszeit: 10ms (siehe Zykluszeit schnell/Cycletime Fast)

Achtung:
Reduktion der Zykluszeit Motor_03 auf 10ms geplant.
Projektabhängig soll künftig mit 10ms gesendet werden.
Empfänger die in weiteren Konzern-Projekten eingesetzt werden müs";
CM_ SG_ 261 MO_Drehzahl_01 "Im Fehlerfall wird die Motordrehzahl über die Nockenwellendrehzahl als Ersatzgrösse ausgegeben

Bei Parallelhybrid: Getriebeeingangsdrehzahl (=E-Maschinen Drehzahl)";
CM_ SG_ 261 MO_Moment_im_Leerlauf "Motorbetriebszustand ist Leerlauf, keine Momentenerhöhung durch Fahrpedal, ACC, GRA+

AUDI D4: Zykluszeit: 10ms (siehe Zykluszeit schnell/Cycletime Fast)

Achtung:
Reduktion der Zykluszeit Motor_03 auf 10ms geplant.
Projektabhängig soll künftig mit ";
CM_ SG_ 261 MO_Interlock "Das Motorsteuergerät gibt die Information aus, ab wann der Kupplungsschalter durch das Motorsteuergerät als getreten gesehen wird.
Bei Systemen für Start Stopp muss das Interlocksignal für einen Start durch das MSG generiert werden, sobald der Schalthebe";
CM_ SG_ 261 MO_BLS "Ungefiltertes Rohsignal des Bremslichtschalters, nur wenn HW-Eingang bestückt und ausgewertet wird. Bei Motoren ohne genutzten HW-Eingang wird kein Ersatzwert (bspw. SW-Signal über CAN) ausgegeben!
Bei AUDI muss das Signal wg. Bremslichtfunktion immer be";
CM_ SG_ 261 MO_Fahrer_bremst "Redundante Bremsinformation vom Motor.

MLB:
AUDI D4: Zykluszeit: 10ms (siehe Zykluszeit schnell/Cycletime Fast)
Im AUDI B8 wird in diesem Bit der Wert der ESP-CAN-Information 'ESP_Fahrer_bremst' ausgegeben.

Achtung:
Reduktion der Zykluszeit Motor";
CM_ SG_ 261 MO_Konsistenz_Bremsped "MLB:

AUDI D4: Zykluszeit: 10ms (siehe Zykluszeit schnell/Cycletime Fast)
Siehe 'Funktionsspezifikation Bremslichtinfo B8'

Achtung:
Reduktion der Zykluszeit Motor_03 auf 10ms geplant.
Projektabhängig soll künftig mit 10ms gesendet werden.
Empfäng";
CM_ SG_ 261 MO_Kuppl_schalter "MLB:
Das Motorsteuergerät gibt die Information aus, ab wann der Kupplungsschalter durch das Motorsteuergerät als getreten gesehen wird
0x0: Schalter sagt betätigt (Ausgekuppelt)
0x1: Schalter sagt nicht betätigt (Eingekuppelt)

MQB:
Nur Handschalter";
CM_ SG_ 261 MO_Timeout_ESP "500 ms Timeout auf Bremsen-Botschaft ist >= 1 mal aufgelaufen, Löschen des Bits nach Neustart (KL15).

MLB:
AUDI D4: Zykluszeit: 10ms (siehe Zykluszeit schnell/Cycletime Fast)

Achtung:
Reduktion der Zykluszeit Motor_03 auf 10ms geplant.
Projektabh";
CM_ SG_ 261 MO_Motor_laeuft "Das Motorsteuergerät gibt die Information aus, ab wann der Motor verbrennungsbedingt autark läuft und durch zuschaltbare Nebenaggregate mechanisch belastbar ist (z.B. durch Generator, Klimakompressor, etc.).

Die 'Motor läuft' Information wird ausgegebe";
CM_ SG_ 261 MO_Solldrehz_Leerlauf "Leerlaufsolldrehzahl, die im Motor eingestellt ist (Bei Parallelhybrid im E-Fahr-Betrieb Leerlaufsolldrehzahl der E-Maschine). Der Motor paßt aufgrund der Anforderung von anderen Steuergeräten seine Leerlaufsolldrehzahl an, bspw. Kat-Heizen, Anforderung v";
CM_ SG_ 261 MO_Fahrpedalrohwert_01 "AUDI D4: Zykluszeit: 10ms (siehe Zykluszeit schnell/Cycletime Fast)

Stellung des Fahrpedales (Rohwert, ohne Überlagerung durch GRA-Eingriffe etc.)

Die Funktionen zur Berechung des Fahrpedalrohwerts laufen im 10ms Raster. Der Fahrpedalwert berechnet ";
CM_ SG_ 261 MO_erste_Ungenauschwelle "Zusätzliche Ungenauigkeit (zur Grundungenauigkeit). Motormomente ungenau >8% (kleinste Ungenauschwelle)
";
CM_ SG_ 261 MO_QBit_Stressfaktor "AUDI D4: Zykluszeit: 10ms (siehe Zykluszeit schnell/Cycletime Fast)

Achtung:
Reduktion der Zykluszeit Motor_03 auf 10ms geplant.
Projektabhängig soll künftig mit 10ms gesendet werden.
Empfänger die in weiteren Konzern-Projekten eingesetzt werden müs";
CM_ SG_ 261 MO_Stressfaktor "AUDI D4: Zykluszeit: 10ms (siehe Zykluszeit schnell/Cycletime Fast)

Berücksichtigung von Höhe und Ansauglufttemperatur im aktuellen Betriebspunkt. Berücksichtigung bei Berechnung der ACC-Sollbeschleunigung. Fehlerwert existiert nicht, 0x3F ist gültiger";
CM_ SG_ 263 MO_rel_Ladedruck "relativer Ladedruck (für Boostanzeige)";
CM_ SG_ 263 MO_Istgang "Aktueller Gang für Anzeige Hochschaltempfehlung (gültig, wenn MO_Schaltempf_verfbar = 1).

Anzeige im Kombi:
Sollgang == Istgang         ==> Anzeige Istgang
Sollgang !=   Istgang         ==> Schaltempfehlung
Sollgang == Istgang == 0 ==> keine Anzeige";
CM_ SG_ 263 MO_Sollgang "Motor sendet den Sollgang in den der Fahrer schalten soll. Wird im Kombi als Hochschaltempfehlung hervorgehoben (gültig, wenn MO_Schaltempf_verfbar = 1).

Anzeige im Kombi:
Sollgang == Istgang          ==> Anzeige Istgang
Sollgang !=  Istgang         ";
CM_ SG_ 263 MO_Oeldruck "Öldruck analog zur Anzeige";
CM_ SG_ 263 MO_Anzeigedrehz "Optimierte Anzeigedrehzahl wegen sportlicherem Drehzahlmesser im Kombi. 
Bei Parallelhybrid: Anzeige VKM- Drehzahl nach Anzeigekonzept";
CM_ SG_ 263 MO_Effizienzmodus "Bei Handschaltern wird  das Fahrprogramm Effizienz signalisiert. 
Bei Automatikgetrieben wird das Fahrprogramm 'D' durch 'E' ersetzt.";
CM_ SG_ 263 MO_Schaltempf_verfbar "Info, ob Schaltempfehlung im Fzg. verfügbar. Statischer Wert, ändert sich für ein Fzg. nicht!";
CM_ SG_ 263 MO_Ladedruck "absoluter Ladedruck";
CM_ SG_ 263 MO_KVS "Motorsteuergerätinterner Verbrauchszähler, der vom Kombi zyklisch ausgelesen wird, um die Einspritzmenge zur Verbrauchsmessung aufzusummieren; aus diesem Zählerstand werden Momentan- und Durchschnittsverbrauch berechnet; das Überlauf-Bit ist zu berücksich";
CM_ SG_ 263 MO_KVS_Ueberlauf "Der motorsteuergeräteinterne Verbrauchszähler ist mindestens einmal übergelaufen. Dieses Bit wird genutzt, um erkennen zu können, daß das Motorsteuergerät aus dem Reset-Zustand hochläuft.";
BA_DEF_ BO_  "DiagRequest" ENUM  "No","Yes";
BA_DEF_ BO_  "DiagResponse" ENUM  "No","Yes";
BA_DEF_ BO_  "DiagState" ENUM  "No","Yes";
BA_DEF_ BO_  "GenMsgChkConstant" HEX 0 4095;
BA_DEF_ BO_  "GenMsgCycleTime" INT 0 65535;
BA_DEF_ BO_  "GenMsgCycleTimeFast" INT 0 65535;
BA_DEF_ BO_  "GenMsgDelayTime" INT 0 100000;
BA_DEF_ BO_  "GenMsgILSupport" ENUM  "No","Yes";
BA_DEF_ BO_  "GenMsgNrOfRepetition" INT 0 100;
BA_DEF_ BO_  "GenMsgPDUConstants" STRING ;
BA_DEF_ BO_  "GenMsgSendType" ENUM  "Cyclic","not_used","not_used","not_used","not_used","not_used","not_used","IfActive","NoMsgSendType";
BA_DEF_ BO_  "GenMsgStartDelayTime" INT 0 100000;
BA_DEF_ BO_  "NmMessage" ENUM  "No","Yes";
BA_DEF_ BO_  "NmhMessage" ENUM  "No","Yes";
BA_DEF_ BO_  "MsgType" ENUM  "Application","NM ","NMH","TP2.0","ISO-TP ","BAP","EID";
BA_DEF_ BO_  "VAGTP20_API" HEX 0 255;
BA_DEF_ BO_  "VAGTP20_DynConnection" ENUM  "No","Yes";
BA_DEF_ BO_  "VAGTP20_DynSetup" ENUM  "No","Yes";
BA_DEF_ BO_  "VAGTP20_StatConnection" ENUM  "No","Yes";
BA_DEF_ SG_  "GenSigActiveRepetitions" INT -2147483648 2147483647;
BA_DEF_ SG_  "GenSigInactiveValue" INT -2147483648 2147483647;
BA_DEF_ SG_  "GenSigSendType" ENUM  "Cyclic","OnWrite","OnWriteWithRepetition","OnChange","OnChangeWithRepetition","IfActive","IfActiveWithRepetition","NoSigSendType","OnChangeAndIfActive","OnChangeAndIfActiveWithRepetition";
BA_DEF_ SG_  "GenSigStartValue" INT -2147483648 2147483647;
BA_DEF_ SG_  "NWM-WakeupAllowed" ENUM  "No","Yes";
BA_DEF_ SG_  "GenSigFuncType" ENUM  "NoFunction","MsgCounter","CRC-8","XOR","XOR-2","DatedBit","SW-Kl15","CHK","Constant","Protocol","CRC-8-SAE_J1850";
BA_DEF_ SG_  "GenSigSwitchedByIgnition" ENUM  "No","Yes";
BA_DEF_ SG_  "Fehlerwert" HEX 0 2147483647;
BA_DEF_ SG_  "GenSigMissingSourceValue" HEX 0 2147483647;
BA_DEF_REL_ BU_SG_REL_  "GenSigTimeoutTime" INT 0 65535;
BA_DEF_DEF_REL_ "GenSigTimeoutTime" 0;
BA_DEF_DEF_  "DiagRequest" "No";
BA_DEF_DEF_  "DiagResponse" "No";
BA_DEF_DEF_  "DiagState" "No";
BA_DEF_DEF_  "GenMsgChkConstant" 0;
BA_DEF_DEF_  "GenMsgCycleTime" 0;
BA_DEF_DEF_  "GenMsgCycleTimeFast" 0;
BA_DEF_DEF_  "GenMsgDelayTime" 0;
BA_DEF_DEF_  "GenMsgILSupport" "No";
BA_DEF_DEF_  "GenMsgNrOfRepetition" 0;
BA_DEF_DEF_  "GenMsgPDUConstants" "";
BA_DEF_DEF_  "GenMsgSendType" "NoMsgSendType";
BA_DEF_DEF_  "GenMsgStartDelayTime" 0;
BA_DEF_DEF_  "NmMessage" "No";
BA_DEF_DEF_  "NmhMessage" "No";
BA_DEF_DEF_  "MsgType" "Application";
BA_DEF_DEF_  "VAGTP20_API" 0;
BA_DEF_DEF_  "VAGTP20_DynConnection" "No";
BA_DEF_DEF_  "VAGTP20_DynSetup" "No";
BA_DEF_DEF_  "VAGTP20_StatConnection" "No";
BA_DEF_DEF_  "GenSigActiveRepetitions" 0;
BA_DEF_DEF_  "GenSigInactiveValue" 0;
BA_DEF_DEF_  "GenSigSendType" "NoSigSendType";
BA_DEF_DEF_  "GenSigStartValue" 0;
BA_DEF_DEF_  "NWM-WakeupAllowed" "No";
BA_DEF_DEF_  "GenSigFuncType" "NoFunction";
BA_DEF_DEF_  "GenSigSwitchedByIgnition" "Yes";
BA_DEF_DEF_  "Fehlerwert" 0;
BA_DEF_DEF_  "GenSigMissingSourceValue" 0;
BA_ "GenMsgSendType" BO_ 131 0;
BA_ "GenMsgPDUConstants" BO_ 131 "0x83,0x83,0x83,0x83,0x83,0x83,0x83,0x83,0x83,0x83,0x83,0x83,0x83,0x83,0x83,0x83";
BA_ "GenMsgILSupport" BO_ 131 1;
BA_ "GenMsgCycleTime" BO_ 131 10;
BA_ "GenMsgChkConstant" BO_ 131 131;
BA_ "GenMsgSendType" BO_ 258 0;
BA_ "GenMsgPDUConstants" BO_ 258 "0x03,0x03,0x03,0x03,0x03,0x03,0x03,0x03,0x03,0x03,0x03,0x03,0x03,0x03,0x03,0x03";
BA_ "GenMsgILSupport" BO_ 258 1;
BA_ "GenMsgCycleTime" BO_ 258 20;
BA_ "GenMsgChkConstant" BO_ 258 3;
BA_ "GenMsgSendType" BO_ 1089 0;
BA_ "GenMsgILSupport" BO_ 1089 1;
BA_ "GenMsgCycleTime" BO_ 1089 100;
BA_ "GenMsgSendType" BO_ 1340 0;
BA_ "GenMsgILSupport" BO_ 1340 1;
BA_ "GenMsgDelayTime" BO_ 1340 100;
BA_ "GenMsgCycleTime" BO_ 1340 1000;
BA_ "MsgType" BO_ 1811 4;
BA_ "DiagRequest" BO_ 1811 1;
BA_ "MsgType" BO_ 1917 4;
BA_ "DiagResponse" BO_ 1917 1;
BA_ "MsgType" BO_ 1892 4;
BA_ "DiagRequest" BO_ 1892 1;
BA_ "MsgType" BO_ 1998 4;
BA_ "DiagResponse" BO_ 1998 1;
BA_ "MsgType" BO_ 1813 4;
BA_ "DiagRequest" BO_ 1813 1;
BA_ "MsgType" BO_ 1919 4;
BA_ "DiagResponse" BO_ 1919 1;
BA_ "MsgType" BO_ 1874 4;
BA_ "DiagRequest" BO_ 1874 1;
BA_ "MsgType" BO_ 1980 4;
BA_ "DiagResponse" BO_ 1980 1;
BA_ "MsgType" BO_ 1795 4;
BA_ "DiagState" BO_ 1795 1;
BA_ "MsgType" BO_ 1792 4;
BA_ "DiagState" BO_ 1792 1;
BA_ "MsgType" BO_ 2015 4;
BA_ "DiagState" BO_ 2015 1;
BA_ "MsgType" BO_ 2017 4;
BA_ "DiagRequest" BO_ 2017 1;
BA_ "MsgType" BO_ 2025 4;
BA_ "DiagResponse" BO_ 2025 1;
BA_ "MsgType" BO_ 2016 4;
BA_ "DiagRequest" BO_ 2016 1;
BA_ "MsgType" BO_ 2024 4;
BA_ "DiagResponse" BO_ 2024 1;
BA_ "MsgType" BO_ 2018 4;
BA_ "DiagRequest" BO_ 2018 1;
BA_ "MsgType" BO_ 2026 4;
BA_ "DiagResponse" BO_ 2026 1;
BA_ "MsgType" BO_ 2021 4;
BA_ "DiagRequest" BO_ 2021 1;
BA_ "MsgType" BO_ 2029 4;
BA_ "DiagResponse" BO_ 2029 1;
BA_ "MsgType" BO_ 2022 4;
BA_ "DiagRequest" BO_ 2022 1;
BA_ "MsgType" BO_ 2030 4;
BA_ "DiagResponse" BO_ 2030 1;
BA_ "MsgType" BO_ 1834 4;
BA_ "DiagRequest" BO_ 1834 1;
BA_ "MsgType" BO_ 1940 4;
BA_ "DiagResponse" BO_ 1940 1;
BA_ "MsgType" BO_ 1814 4;
BA_ "DiagRequest" BO_ 1814 1;
BA_ "MsgType" BO_ 1920 4;
BA_ "DiagResponse" BO_ 1920 1;
BA_ "MsgType" BO_ 1820 4;
BA_ "DiagRequest" BO_ 1820 1;
BA_ "MsgType" BO_ 1926 4;
BA_ "DiagResponse" BO_ 1926 1;
BA_ "MsgType" BO_ 1875 4;
BA_ "DiagRequest" BO_ 1875 1;
BA_ "MsgType" BO_ 1981 4;
BA_ "DiagResponse" BO_ 1981 1;
BA_ "GenMsgSendType" BO_ 1424 0;
BA_ "GenMsgILSupport" BO_ 1424 1;
BA_ "GenMsgDelayTime" BO_ 1424 50;
BA_ "GenMsgCycleTime" BO_ 1424 200;
BA_ "GenMsgSendType" BO_ 960 0;
BA_ "GenMsgPDUConstants" BO_ 960 "0xc3,0xc3,0xc3,0xc3,0xc3,0xc3,0xc3,0xc3,0xc3,0xc3,0xc3,0xc3,0xc3,0xc3,0xc3,0xc3";
BA_ "GenMsgILSupport" BO_ 960 1;
BA_ "GenMsgDelayTime" BO_ 960 10;
BA_ "GenMsgCycleTime" BO_ 960 100;
BA_ "GenMsgChkConstant" BO_ 960 195;
BA_ "GenMsgSendType" BO_ 959 0;
BA_ "GenMsgILSupport" BO_ 959 1;
BA_ "GenMsgCycleTime" BO_ 959 100;
BA_ "GenMsgSendType" BO_ 1636 0;
BA_ "GenMsgILSupport" BO_ 1636 1;
BA_ "GenMsgDelayTime" BO_ 1636 50;
BA_ "GenMsgCycleTime" BO_ 1636 500;
BA_ "GenMsgSendType" BO_ 1646 0;
BA_ "GenMsgILSupport" BO_ 1646 1;
BA_ "GenMsgDelayTime" BO_ 1646 200;
BA_ "GenMsgCycleTime" BO_ 1646 2000;
BA_ "GenMsgSendType" BO_ 1625 0;
BA_ "GenMsgILSupport" BO_ 1625 1;
BA_ "GenMsgCycleTime" BO_ 1625 500;
BA_ "GenMsgSendType" BO_ 779 0;
BA_ "GenMsgILSupport" BO_ 779 1;
BA_ "GenMsgCycleTime" BO_ 779 50;
BA_ "GenMsgSendType" BO_ 1719 0;
BA_ "GenMsgILSupport" BO_ 1719 1;
BA_ "GenMsgCycleTime" BO_ 1719 1000;
BA_ "GenMsgSendType" BO_ 1720 0;
BA_ "GenMsgILSupport" BO_ 1720 1;
BA_ "GenMsgCycleTime" BO_ 1720 1000;
BA_ "GenMsgSendType" BO_ 285 0;
BA_ "GenMsgPDUConstants" BO_ 285 "0x1c,0x1c,0x1c,0x1c,0x1c,0x1c,0x1c,0x1c,0x1c,0x1c,0x1c,0x1c,0x1c,0x1c,0x1c,0x1c";
BA_ "GenMsgILSupport" BO_ 285 1;
BA_ "GenMsgCycleTime" BO_ 285 20;
BA_ "GenMsgChkConstant" BO_ 285 28;
BA_ "GenMsgSendType" BO_ 1137 0;
BA_ "GenMsgILSupport" BO_ 1137 1;
BA_ "GenMsgCycleTime" BO_ 1137 100;
BA_ "GenMsgSendType" BO_ 267 0;
BA_ "GenMsgPDUConstants" BO_ 267 "0x0a,0x0a,0x0a,0x0a,0x0a,0x0a,0x0a,0x0a,0x0a,0x0a,0x0a,0x0a,0x0a,0x0a,0x0a,0x0a";
BA_ "GenMsgNrOfRepetition" BO_ 267 1;
BA_ "GenMsgILSupport" BO_ 267 1;
BA_ "GenMsgDelayTime" BO_ 267 20;
BA_ "GenMsgCycleTimeFast" BO_ 267 20;
BA_ "GenMsgCycleTime" BO_ 267 100;
BA_ "GenMsgChkConstant" BO_ 267 10;
BA_ "GenMsgSendType" BO_ 134 0;
BA_ "GenMsgPDUConstants" BO_ 134 "0x86,0x86,0x86,0x86,0x86,0x86,0x86,0x86,0x86,0x86,0x86,0x86,0x86,0x86,0x86,0x86";
BA_ "GenMsgILSupport" BO_ 134 1;
BA_ "GenMsgCycleTime" BO_ 134 10;
BA_ "GenMsgChkConstant" BO_ 134 134;
BA_ "GenMsgSendType" BO_ 128 0;
BA_ "GenMsgPDUConstants" BO_ 128 "0x80,0x80,0x80,0x80,0x80,0x80,0x80,0x80,0x80,0x80,0x80,0x80,0x80,0x80,0x80,0x80";
BA_ "GenMsgILSupport" BO_ 128 1;
BA_ "GenMsgCycleTime" BO_ 128 10;
BA_ "GenMsgChkConstant" BO_ 128 128;
BA_ "GenMsgSendType" BO_ 129 0;
BA_ "GenMsgPDUConstants" BO_ 129 "0x81,0x81,0x81,0x81,0x81,0x81,0x81,0x81,0x81,0x81,0x81,0x81,0x81,0x81,0x81,0x81";
BA_ "GenMsgILSupport" BO_ 129 1;
BA_ "GenMsgCycleTime" BO_ 129 10;
BA_ "GenMsgChkConstant" BO_ 129 129;
BA_ "GenMsgSendType" BO_ 261 0;
BA_ "GenMsgPDUConstants" BO_ 261 "0x04,0x04,0x04,0x04,0x04,0x04,0x04,0x04,0x04,0x04,0x04,0x04,0x04,0x04,0x04,0x04";
BA_ "GenMsgILSupport" BO_ 261 1;
BA_ "GenMsgCycleTime" BO_ 261 10;
BA_ "GenMsgChkConstant" BO_ 261 4;
BA_ "GenMsgSendType" BO_ 263 0;
BA_ "GenMsgILSupport" BO_ 263 1;
BA_ "GenMsgCycleTime" BO_ 263 20;
BA_ "GenSigSwitchedByIgnition" SG_ 131 Getriebe_02_CHK 0;
BA_ "GenSigFuncType" SG_ 131 Getriebe_02_CHK 3;
BA_ "GenSigSendType" SG_ 131 Getriebe_02_CHK 0;
BA_ "GenSigSwitchedByIgnition" SG_ 131 Getriebe_02_BZ 0;
BA_ "GenSigFuncType" SG_ 131 Getriebe_02_BZ 1;
BA_ "GenSigSendType" SG_ 131 Getriebe_02_BZ 0;
BA_ "GenSigSwitchedByIgnition" SG_ 131 GE_Anf_Zylabsch 0;
BA_ "GenSigSendType" SG_ 131 GE_Anf_Zylabsch 0;
BA_ "Fehlerwert" SG_ 131 GE_Synchro_Wunschdrehz 511;
BA_ "GenSigSwitchedByIgnition" SG_ 131 GE_Synchro_Wunschdrehz 0;
BA_ "GenSigSendType" SG_ 131 GE_Synchro_Wunschdrehz 0;
BA_ "Fehlerwert" SG_ 131 GE_Synchro_Zeit 255;
BA_ "GenSigSwitchedByIgnition" SG_ 131 GE_Synchro_Zeit 0;
BA_ "GenSigSendType" SG_ 131 GE_Synchro_Zeit 0;
BA_ "GenSigSwitchedByIgnition" SG_ 131 GE_Mom_Begr_Gradient 0;
BA_ "GenSigStartValue" SG_ 131 GE_Mom_Begr_Gradient 255;
BA_ "GenSigSendType" SG_ 131 GE_Mom_Begr_Gradient 0;
BA_ "Fehlerwert" SG_ 131 GE_Anheb_Solldrehz_Leerlauf 255;
BA_ "GenSigSwitchedByIgnition" SG_ 131 GE_Anheb_Solldrehz_Leerlauf 0;
BA_ "GenSigSendType" SG_ 131 GE_Anheb_Solldrehz_Leerlauf 0;
BA_ "Fehlerwert" SG_ 131 GE_Vorsteuermoment 511;
BA_ "GenSigSwitchedByIgnition" SG_ 131 GE_Vorsteuermoment 0;
BA_ "GenSigStartValue" SG_ 131 GE_Vorsteuermoment 510;
BA_ "GenSigSendType" SG_ 131 GE_Vorsteuermoment 0;
BA_ "GenSigSwitchedByIgnition" SG_ 131 GE_Segeln_Aktiv 0;
BA_ "GenSigSendType" SG_ 131 GE_Segeln_Aktiv 0;
BA_ "GenSigSwitchedByIgnition" SG_ 131 GE_Drehzahlmesser_Daempfung 0;
BA_ "GenSigSendType" SG_ 131 GE_Drehzahlmesser_Daempfung 0;
BA_ "GenSigSwitchedByIgnition" SG_ 131 GE_Schubabschalt_Unt 0;
BA_ "GenSigSendType" SG_ 131 GE_Schubabschalt_Unt 0;
BA_ "GenSigSwitchedByIgnition" SG_ 131 GE_Freigabe_Synchro 0;
BA_ "GenSigSendType" SG_ 131 GE_Freigabe_Synchro 0;
BA_ "GenSigSwitchedByIgnition" SG_ 131 GE_HYB_DZ_Eingriff 0;
BA_ "GenSigSendType" SG_ 131 GE_HYB_DZ_Eingriff 0;
BA_ "GenSigSwitchedByIgnition" SG_ 258 Getriebe_03_CHK 0;
BA_ "GenSigFuncType" SG_ 258 Getriebe_03_CHK 3;
BA_ "GenSigSendType" SG_ 258 Getriebe_03_CHK 0;
BA_ "GenSigSwitchedByIgnition" SG_ 258 Getriebe_03_BZ 0;
BA_ "GenSigFuncType" SG_ 258 Getriebe_03_BZ 1;
BA_ "GenSigSendType" SG_ 258 Getriebe_03_BZ 0;
BA_ "GenSigSwitchedByIgnition" SG_ 258 GE_Freig_Langfr_Schutzmom 0;
BA_ "GenSigSendType" SG_ 258 GE_Freig_Langfr_Schutzmom 0;
BA_ "Fehlerwert" SG_ 258 GE_Uefkt 1023;
BA_ "GenSigSwitchedByIgnition" SG_ 258 GE_Uefkt 0;
BA_ "GenSigSendType" SG_ 258 GE_Uefkt 0;
BA_ "Fehlerwert" SG_ 258 GE_Zielgang 15;
BA_ "GenSigSwitchedByIgnition" SG_ 258 GE_Zielgang 0;
BA_ "GenSigSendType" SG_ 258 GE_Zielgang 0;
BA_ "GenSigSwitchedByIgnition" SG_ 258 GE_StartStopp_Info 0;
BA_ "GenSigSendType" SG_ 258 GE_StartStopp_Info 0;
BA_ "Fehlerwert" SG_ 258 GE_Langfr_Schutzmom 1023;
BA_ "GenSigSwitchedByIgnition" SG_ 258 GE_Langfr_Schutzmom 0;
BA_ "GenSigStartValue" SG_ 258 GE_Langfr_Schutzmom 1022;
BA_ "GenSigSendType" SG_ 258 GE_Langfr_Schutzmom 0;
BA_ "GenSigSwitchedByIgnition" SG_ 258 GE_Performance_Start_LB 0;
BA_ "GenSigSendType" SG_ 258 GE_Performance_Start_LB 0;
BA_ "GenSigSwitchedByIgnition" SG_ 258 GE_reserv_Waehlhebel 0;
BA_ "GenSigSendType" SG_ 258 GE_reserv_Waehlhebel 0;
BA_ "Fehlerwert" SG_ 258 GE_Waehlhebel 15;
BA_ "GenSigSwitchedByIgnition" SG_ 258 GE_Waehlhebel 0;
BA_ "GenSigStartValue" SG_ 258 GE_Waehlhebel 1;
BA_ "GenSigSendType" SG_ 258 GE_Waehlhebel 0;
BA_ "Fehlerwert" SG_ 258 GE_Eingangsdrehz 16383;
BA_ "GenSigSwitchedByIgnition" SG_ 258 GE_Eingangsdrehz 0;
BA_ "GenSigStartValue" SG_ 258 GE_Eingangsdrehz 16382;
BA_ "GenSigSendType" SG_ 258 GE_Eingangsdrehz 0;
BA_ "GenSigSwitchedByIgnition" SG_ 258 GE_Notlauf 0;
BA_ "GenSigSendType" SG_ 258 GE_Notlauf 0;
BA_ "GenSigSwitchedByIgnition" SG_ 258 GE_Codierung_MSG 0;
BA_ "GenSigSendType" SG_ 258 GE_Codierung_MSG 0;
BA_ "Fehlerwert" SG_ 1089 GE_Index_Fahrwid 255;
BA_ "GenSigSwitchedByIgnition" SG_ 1089 GE_Index_Fahrwid 0;
BA_ "GenSigStartValue" SG_ 1089 GE_Index_Fahrwid 127;
BA_ "GenSigSendType" SG_ 1089 GE_Index_Fahrwid 0;
BA_ "GenSigSwitchedByIgnition" SG_ 1089 GE_Heizwunsch 0;
BA_ "GenSigStartValue" SG_ 1089 GE_Heizwunsch 1;
BA_ "GenSigSendType" SG_ 1089 GE_Heizwunsch 0;
BA_ "GenSigSwitchedByIgnition" SG_ 1089 GE_OBD_Status 0;
BA_ "GenSigSendType" SG_ 1089 GE_OBD_Status 0;
BA_ "GenSigSwitchedByIgnition" SG_ 1089 GE_LFR_Adaption 0;
BA_ "GenSigSendType" SG_ 1089 GE_LFR_Adaption 0;
BA_ "GenSigSwitchedByIgnition" SG_ 1089 GE_OBD_AbsperrVent 0;
BA_ "GenSigSendType" SG_ 1089 GE_OBD_AbsperrVent 0;
BA_ "Fehlerwert" SG_ 1089 GE_Grenzkriechmoment 63;
BA_ "GenSigSwitchedByIgnition" SG_ 1089 GE_Grenzkriechmoment 0;
BA_ "GenSigStartValue" SG_ 1089 GE_Grenzkriechmoment 62;
BA_ "GenSigSendType" SG_ 1089 GE_Grenzkriechmoment 0;
BA_ "GenSigSwitchedByIgnition" SG_ 1089 GE_Charisma_FahrPr 0;
BA_ "GenSigSendType" SG_ 1089 GE_Charisma_FahrPr 0;
BA_ "GenSigSwitchedByIgnition" SG_ 1089 GE_Charisma_Status 0;
BA_ "GenSigSendType" SG_ 1089 GE_Charisma_Status 0;
BA_ "GenSigSwitchedByIgnition" SG_ 1089 GE_Charisma_Umschaltung 0;
BA_ "GenSigSendType" SG_ 1089 GE_Charisma_Umschaltung 0;
BA_ "GenSigSwitchedByIgnition" SG_ 1089 GE_Freigabe_Verfallsinfo_WFS 0;
BA_ "GenSigSendType" SG_ 1089 GE_Freigabe_Verfallsinfo_WFS 0;
BA_ "Fehlerwert" SG_ 1089 GE_Verlustmoment 255;
BA_ "GenSigSwitchedByIgnition" SG_ 1089 GE_Verlustmoment 0;
BA_ "GenSigSendType" SG_ 1089 GE_Verlustmoment 0;
BA_ "GenSigSwitchedByIgnition" SG_ 1089 GE_LaunchControl 0;
BA_ "GenSigSendType" SG_ 1089 GE_LaunchControl 0;
BA_ "GenSigSwitchedByIgnition" SG_ 1089 GE_amax_moeglich 0;
BA_ "GenSigStartValue" SG_ 1089 GE_amax_moeglich 84;
BA_ "GenSigSendType" SG_ 1089 GE_amax_moeglich 0;
BA_ "Fehlerwert" SG_ 1089 GE_Sumpftemperatur 255;
BA_ "GenSigSwitchedByIgnition" SG_ 1089 GE_Sumpftemperatur 0;
BA_ "GenSigSendType" SG_ 1089 GE_Sumpftemperatur 0;
BA_ "GenSigSwitchedByIgnition" SG_ 1340 HVLM_04_CRC 0;
BA_ "GenSigFuncType" SG_ 1340 HVLM_04_CRC 2;
BA_ "GenSigSendType" SG_ 1340 HVLM_04_CRC 0;
BA_ "GenSigSwitchedByIgnition" SG_ 1340 HVLM_04_BZ 0;
BA_ "GenSigFuncType" SG_ 1340 HVLM_04_BZ 1;
BA_ "GenSigSendType" SG_ 1340 HVLM_04_BZ 0;
BA_ "Fehlerwert" SG_ 1340 HVLM_IstModus_02 3;
BA_ "GenSigSwitchedByIgnition" SG_ 1340 HVLM_IstModus_02 0;
BA_ "GenSigStartValue" SG_ 1340 HVLM_IstModus_02 2;
BA_ "GenSigSendType" SG_ 1340 HVLM_IstModus_02 0;
BA_ "GenSigSwitchedByIgnition" SG_ 1340 HVLM_HV_Anf 0;
BA_ "GenSigSendType" SG_ 1340 HVLM_HV_Anf 0;
BA_ "GenSigSwitchedByIgnition" SG_ 1340 HVLM_Fehlerstatus 0;
BA_ "GenSigStartValue" SG_ 1340 HVLM_Fehlerstatus 7;
BA_ "GenSigSendType" SG_ 1340 HVLM_Fehlerstatus 0;
BA_ "Fehlerwert" SG_ 1340 HVLM_Anforderung_HMS 7;
BA_ "GenSigSwitchedByIgnition" SG_ 1340 HVLM_Anforderung_HMS 0;
BA_ "GenSigSendType" SG_ 1340 HVLM_Anforderung_HMS 3;
BA_ "Fehlerwert" SG_ 1340 HVLM_Parken_beibehalten_HMS 3;
BA_ "GenSigSwitchedByIgnition" SG_ 1340 HVLM_Parken_beibehalten_HMS 0;
BA_ "GenSigStartValue" SG_ 1340 HVLM_Parken_beibehalten_HMS 2;
BA_ "GenSigSendType" SG_ 1340 HVLM_Parken_beibehalten_HMS 3;
BA_ "Fehlerwert" SG_ 1340 HVLM_Dauer_Klima 31;
BA_ "GenSigSwitchedByIgnition" SG_ 1340 HVLM_Dauer_Klima 0;
BA_ "GenSigSendType" SG_ 1340 HVLM_Dauer_Klima 0;
BA_ "GenSigSwitchedByIgnition" SG_ 1340 HVLM_Stecker_Status 0;
BA_ "GenSigSendType" SG_ 1340 HVLM_Stecker_Status 3;
BA_ "Fehlerwert" SG_ 1340 HVLM_LadeAnforderung 7;
BA_ "GenSigSwitchedByIgnition" SG_ 1340 HVLM_LadeAnforderung 0;
BA_ "GenSigStartValue" SG_ 1340 HVLM_LadeAnforderung 6;
BA_ "GenSigSendType" SG_ 1340 HVLM_LadeAnforderung 3;
BA_ "Fehlerwert" SG_ 1340 HVLM_MaxBatLadestromHV 255;
BA_ "GenSigSwitchedByIgnition" SG_ 1340 HVLM_MaxBatLadestromHV 0;
BA_ "GenSigStartValue" SG_ 1340 HVLM_MaxBatLadestromHV 254;
BA_ "GenSigSendType" SG_ 1340 HVLM_MaxBatLadestromHV 3;
BA_ "GenSigSwitchedByIgnition" SG_ 1811 ISO_ABS_Req_Data 0;
BA_ "GenSigFuncType" SG_ 1811 ISO_ABS_Req_Data 9;
BA_ "GenSigSendType" SG_ 1811 ISO_ABS_Req_Data 3;
BA_ "GenSigSwitchedByIgnition" SG_ 1917 ISO_ABS_Resp_Data 0;
BA_ "GenSigSendType" SG_ 1917 ISO_ABS_Resp_Data 3;
BA_ "GenSigSwitchedByIgnition" SG_ 1892 ISO_AGA_Req_Data 0;
BA_ "GenSigFuncType" SG_ 1892 ISO_AGA_Req_Data 9;
BA_ "GenSigSendType" SG_ 1892 ISO_AGA_Req_Data 3;
BA_ "GenSigFuncType" SG_ 1998 ISO_AGA_Resp_Data 9;
BA_ "GenSigSendType" SG_ 1998 ISO_AGA_Resp_Data 3;
BA_ "GenSigSwitchedByIgnition" SG_ 1813 ISO_Airbag_01_Req_Data 0;
BA_ "GenSigFuncType" SG_ 1813 ISO_Airbag_01_Req_Data 9;
BA_ "GenSigSendType" SG_ 1813 ISO_Airbag_01_Req_Data 3;
BA_ "GenSigFuncType" SG_ 1919 ISO_Airbag_01_Resp_Data 9;
BA_ "GenSigSendType" SG_ 1919 ISO_Airbag_01_Resp_Data 3;
BA_ "GenSigSwitchedByIgnition" SG_ 1874 ISO_EPB_Req_Data 0;
BA_ "GenSigFuncType" SG_ 1874 ISO_EPB_Req_Data 9;
BA_ "GenSigSendType" SG_ 1874 ISO_EPB_Req_Data 3;
BA_ "GenSigSwitchedByIgnition" SG_ 1980 ISO_EPB_Resp_Data 0;
BA_ "GenSigFuncType" SG_ 1980 ISO_EPB_Resp_Data 9;
BA_ "GenSigSendType" SG_ 1980 ISO_EPB_Resp_Data 3;
BA_ "GenSigSwitchedByIgnition" SG_ 1795 ISO_Funktionaler_Req_Abgas 0;
BA_ "GenSigFuncType" SG_ 1795 ISO_Funktionaler_Req_Abgas 9;
BA_ "GenSigSendType" SG_ 1795 ISO_Funktionaler_Req_Abgas 3;
BA_ "GenSigSwitchedByIgnition" SG_ 1792 ISO_ALL_01_Req_Data 0;
BA_ "GenSigFuncType" SG_ 1792 ISO_ALL_01_Req_Data 9;
BA_ "GenSigSendType" SG_ 1792 ISO_ALL_01_Req_Data 3;
BA_ "GenSigSwitchedByIgnition" SG_ 2015 ISO_OBD_Funktionaler_Req_Data 0;
BA_ "GenSigFuncType" SG_ 2015 ISO_OBD_Funktionaler_Req_Data 9;
BA_ "GenSigSendType" SG_ 2015 ISO_OBD_Funktionaler_Req_Data 3;
BA_ "GenSigSwitchedByIgnition" SG_ 2017 ISO_Getriebe_01_Req_Data 0;
BA_ "GenSigFuncType" SG_ 2017 ISO_Getriebe_01_Req_Data 9;
BA_ "GenSigSendType" SG_ 2017 ISO_Getriebe_01_Req_Data 3;
BA_ "GenSigSwitchedByIgnition" SG_ 2025 ISO_Getriebe_01_Resp_Data 0;
BA_ "GenSigFuncType" SG_ 2025 ISO_Getriebe_01_Resp_Data 9;
BA_ "GenSigSendType" SG_ 2025 ISO_Getriebe_01_Resp_Data 3;
BA_ "GenSigSwitchedByIgnition" SG_ 2016 ISO_MO_01_Req_Data 0;
BA_ "GenSigFuncType" SG_ 2016 ISO_MO_01_Req_Data 9;
BA_ "GenSigSendType" SG_ 2016 ISO_MO_01_Req_Data 3;
BA_ "GenSigSwitchedByIgnition" SG_ 2024 ISO_MO_01_Resp_Data 0;
BA_ "GenSigFuncType" SG_ 2024 ISO_MO_01_Resp_Data 9;
BA_ "GenSigSendType" SG_ 2024 ISO_MO_01_Resp_Data 3;
BA_ "GenSigSwitchedByIgnition" SG_ 2018 ISO_OBD_01_Req_Data 0;
BA_ "GenSigFuncType" SG_ 2018 ISO_OBD_01_Req_Data 9;
BA_ "GenSigSendType" SG_ 2018 ISO_OBD_01_Req_Data 3;
BA_ "GenSigSwitchedByIgnition" SG_ 2026 ISO_OBD_01_Resp_Data 0;
BA_ "GenSigFuncType" SG_ 2026 ISO_OBD_01_Resp_Data 9;
BA_ "GenSigSendType" SG_ 2026 ISO_OBD_01_Resp_Data 3;
BA_ "GenSigSwitchedByIgnition" SG_ 2021 ISO_OBD_04_Req_Data 0;
BA_ "GenSigFuncType" SG_ 2021 ISO_OBD_04_Req_Data 9;
BA_ "GenSigSendType" SG_ 2021 ISO_OBD_04_Req_Data 3;
BA_ "GenSigSwitchedByIgnition" SG_ 2029 ISO_OBD_04_Resp_Data 0;
BA_ "GenSigFuncType" SG_ 2029 ISO_OBD_04_Resp_Data 9;
BA_ "GenSigSendType" SG_ 2029 ISO_OBD_04_Resp_Data 3;
BA_ "GenSigSwitchedByIgnition" SG_ 2022 ISO_OBD_05_Req_Data 0;
BA_ "GenSigFuncType" SG_ 2022 ISO_OBD_05_Req_Data 9;
BA_ "GenSigSendType" SG_ 2022 ISO_OBD_05_Req_Data 3;
BA_ "GenSigSwitchedByIgnition" SG_ 2030 ISO_OBD_05_Resp_Data 0;
BA_ "GenSigFuncType" SG_ 2030 ISO_OBD_05_Resp_Data 9;
BA_ "GenSigSendType" SG_ 2030 ISO_OBD_05_Resp_Data 3;
BA_ "GenSigSwitchedByIgnition" SG_ 1834 ISO_SCR_Req_Data 0;
BA_ "GenSigFuncType" SG_ 1834 ISO_SCR_Req_Data 9;
BA_ "GenSigSendType" SG_ 1834 ISO_SCR_Req_Data 3;
BA_ "GenSigSwitchedByIgnition" SG_ 1940 ISO_SCR_Resp_Data 0;
BA_ "GenSigFuncType" SG_ 1940 ISO_SCR_Resp_Data 9;
BA_ "GenSigSendType" SG_ 1940 ISO_SCR_Resp_Data 3;
BA_ "GenSigSwitchedByIgnition" SG_ 1814 ISO_SCU_Req_Data 0;
BA_ "GenSigFuncType" SG_ 1814 ISO_SCU_Req_Data 9;
BA_ "GenSigSendType" SG_ 1814 ISO_SCU_Req_Data 3;
BA_ "GenSigSwitchedByIgnition" SG_ 1920 ISO_SCU_Resp_Data 0;
BA_ "GenSigFuncType" SG_ 1920 ISO_SCU_Resp_Data 9;
BA_ "GenSigSendType" SG_ 1920 ISO_SCU_Resp_Data 3;
BA_ "GenSigSwitchedByIgnition" SG_ 1820 ISO_Soundaktor_Req_Data 0;
BA_ "GenSigFuncType" SG_ 1820 ISO_Soundaktor_Req_Data 9;
BA_ "GenSigSendType" SG_ 1820 ISO_Soundaktor_Req_Data 3;
BA_ "GenSigFuncType" SG_ 1926 ISO_Soundaktor_Resp_Data 9;
BA_ "GenSigSendType" SG_ 1926 ISO_Soundaktor_Resp_Data 3;
BA_ "GenSigSwitchedByIgnition" SG_ 1875 ISO_Waehlhebel_Req_Data 0;
BA_ "GenSigFuncType" SG_ 1875 ISO_Waehlhebel_Req_Data 9;
BA_ "GenSigSendType" SG_ 1875 ISO_Waehlhebel_Req_Data 3;
BA_ "GenSigSwitchedByIgnition" SG_ 1981 ISO_Waehlhebel_Resp_Data 0;
BA_ "GenSigFuncType" SG_ 1981 ISO_Waehlhebel_Resp_Data 9;
BA_ "GenSigSendType" SG_ 1981 ISO_Waehlhebel_Resp_Data 3;
BA_ "GenSigSwitchedByIgnition" SG_ 1424 KY_Funkschl_Nr 0;
BA_ "GenSigSendType" SG_ 1424 KY_Funkschl_Nr 3;
BA_ "GenSigSwitchedByIgnition" SG_ 1424 KY_ID_Geb_autorisiert 0;
BA_ "GenSigSendType" SG_ 1424 KY_ID_Geb_autorisiert 3;
BA_ "GenSigSwitchedByIgnition" SG_ 1424 KY_ID_Geb_steckt 0;
BA_ "GenSigSendType" SG_ 1424 KY_ID_Geb_steckt 3;
BA_ "GenSigSwitchedByIgnition" SG_ 1424 KY_FFB_Frequenz 0;
BA_ "GenSigSendType" SG_ 1424 KY_FFB_Frequenz 3;
BA_ "GenSigSwitchedByIgnition" SG_ 1424 KY_HF_Aktiv 0;
BA_ "GenSigSendType" SG_ 1424 KY_HF_Aktiv 3;
BA_ "GenSigSwitchedByIgnition" SG_ 1424 KY_LF_Aktiv 0;
BA_ "GenSigSendType" SG_ 1424 KY_LF_Aktiv 3;
BA_ "GenSigSwitchedByIgnition" SG_ 1424 KY_ELV_verr 0;
BA_ "GenSigSendType" SG_ 1424 KY_ELV_verr 3;
BA_ "GenSigSwitchedByIgnition" SG_ 1424 KY_ELV_entr 0;
BA_ "GenSigSendType" SG_ 1424 KY_ELV_entr 3;
BA_ "GenSigSwitchedByIgnition" SG_ 1424 KY_ELV_enable_Anforderung 0;
BA_ "GenSigSendType" SG_ 1424 KY_ELV_enable_Anforderung 3;
BA_ "GenSigSwitchedByIgnition" SG_ 1424 KY_Valet_Parking 0;
BA_ "GenSigSendType" SG_ 1424 KY_Valet_Parking 3;
BA_ "GenSigSwitchedByIgnition" SG_ 1424 KY_Keyless_Verbau 0;
BA_ "GenSigSendType" SG_ 1424 KY_Keyless_Verbau 3;
BA_ "GenSigSwitchedByIgnition" SG_ 1424 KY_FBS_Fahrer_Hinweise 0;
BA_ "GenSigSendType" SG_ 1424 KY_FBS_Fahrer_Hinweise 3;
BA_ "GenSigSwitchedByIgnition" SG_ 1424 FBS_Warn_Lenkung_def 0;
BA_ "GenSigSendType" SG_ 1424 FBS_Warn_Lenkung_def 3;
BA_ "GenSigSwitchedByIgnition" SG_ 1424 FBS_Warn_LenkVerriegelung_def 0;
BA_ "GenSigSendType" SG_ 1424 FBS_Warn_LenkVerriegelung_def 3;
BA_ "GenSigSwitchedByIgnition" SG_ 1424 FBS_Warn_Schluessel_Batt 0;
BA_ "GenSigSendType" SG_ 1424 FBS_Warn_Schluessel_Batt 3;
BA_ "GenSigSwitchedByIgnition" SG_ 1424 FBS_Prio_Warn_04 0;
BA_ "GenSigSendType" SG_ 1424 FBS_Prio_Warn_04 3;
BA_ "GenSigSwitchedByIgnition" SG_ 1424 FBS_Prio_Warn_05 0;
BA_ "GenSigSendType" SG_ 1424 FBS_Prio_Warn_05 3;
BA_ "GenSigSwitchedByIgnition" SG_ 1424 KY_KYL_Fahrer_Hinweise 0;
BA_ "GenSigSendType" SG_ 1424 KY_KYL_Fahrer_Hinweise 3;
BA_ "GenSigSwitchedByIgnition" SG_ 1424 KYL_Warn_kein_Schluessel 0;
BA_ "GenSigSendType" SG_ 1424 KYL_Warn_kein_Schluessel 3;
BA_ "GenSigSwitchedByIgnition" SG_ 1424 KYL_Warn_Kessy_defekt 0;
BA_ "GenSigSendType" SG_ 1424 KYL_Warn_Kessy_defekt 3;
BA_ "GenSigSwitchedByIgnition" SG_ 1424 KY_KYL_Prio_Warn_03 0;
BA_ "GenSigSendType" SG_ 1424 KY_KYL_Prio_Warn_03 3;
BA_ "GenSigSwitchedByIgnition" SG_ 1424 KY_KYL_Prio_Warn_04 0;
BA_ "GenSigSendType" SG_ 1424 KY_KYL_Prio_Warn_04 3;
BA_ "GenSigSwitchedByIgnition" SG_ 1424 KY_KYL_Prio_Warn_05 0;
BA_ "GenSigSendType" SG_ 1424 KY_KYL_Prio_Warn_05 3;
BA_ "GenSigSwitchedByIgnition" SG_ 1424 KY_Schluessel_Soll 0;
BA_ "GenSigSendType" SG_ 1424 KY_Schluessel_Soll 3;
BA_ "GenSigSwitchedByIgnition" SG_ 1424 KY_Schluessel_Ist 0;
BA_ "GenSigSendType" SG_ 1424 KY_Schluessel_Ist 3;
BA_ "GenSigSwitchedByIgnition" SG_ 1424 KY_WFS_Safe 0;
BA_ "GenSigSendType" SG_ 1424 KY_WFS_Safe 3;
BA_ "GenSigSwitchedByIgnition" SG_ 1424 KY_WFS_LZ 0;
BA_ "GenSigSendType" SG_ 1424 KY_WFS_LZ 3;
BA_ "GenSigSwitchedByIgnition" SG_ 1424 KY_StartStopp_Info 0;
BA_ "GenSigSendType" SG_ 1424 KY_StartStopp_Info 3;
BA_ "GenSigSwitchedByIgnition" SG_ 1424 KYL_Notzuendschloss 0;
BA_ "GenSigSendType" SG_ 1424 KYL_Notzuendschloss 0;
BA_ "GenSigSwitchedByIgnition" SG_ 1424 KYL_Warn_Notzuendschloss 0;
BA_ "GenSigSendType" SG_ 1424 KYL_Warn_Notzuendschloss 0;
BA_ "GenSigSwitchedByIgnition" SG_ 1424 FBS_KD_Fehler 0;
BA_ "GenSigSendType" SG_ 1424 FBS_KD_Fehler 3;
BA_ "GenSigSwitchedByIgnition" SG_ 1424 SK_Anf_DTC_Abfrage 0;
BA_ "GenSigSendType" SG_ 1424 SK_Anf_DTC_Abfrage 3;
BA_ "GenSigSwitchedByIgnition" SG_ 1424 SK_Anf_DTC_Abfrage_sofort 0;
BA_ "GenSigSendType" SG_ 1424 SK_Anf_DTC_Abfrage_sofort 3;
BA_ "GenSigSwitchedByIgnition" SG_ 960 Klemmen_Status_01_CHK 0;
BA_ "GenSigFuncType" SG_ 960 Klemmen_Status_01_CHK 3;
BA_ "GenSigSendType" SG_ 960 Klemmen_Status_01_CHK 0;
BA_ "GenSigSwitchedByIgnition" SG_ 960 Klemmen_Status_01_BZ 0;
BA_ "GenSigFuncType" SG_ 960 Klemmen_Status_01_BZ 1;
BA_ "GenSigSendType" SG_ 960 Klemmen_Status_01_BZ 0;
BA_ "GenSigSwitchedByIgnition" SG_ 960 ZV_verriegelt_extern_soll_02 0;
BA_ "GenSigSendType" SG_ 960 ZV_verriegelt_extern_soll_02 3;
BA_ "GenSigSwitchedByIgnition" SG_ 960 ZAS_Kl_S 0;
BA_ "GenSigSendType" SG_ 960 ZAS_Kl_S 3;
BA_ "GenSigSwitchedByIgnition" SG_ 960 ZAS_Kl_15 0;
BA_ "GenSigFuncType" SG_ 960 ZAS_Kl_15 6;
BA_ "NWM-WakeupAllowed" SG_ 960 ZAS_Kl_15 1;
BA_ "GenSigSendType" SG_ 960 ZAS_Kl_15 3;
BA_ "GenSigSwitchedByIgnition" SG_ 960 ZAS_Kl_X 0;
BA_ "GenSigSendType" SG_ 960 ZAS_Kl_X 3;
BA_ "GenSigSwitchedByIgnition" SG_ 960 ZAS_Kl_50 0;
BA_ "GenSigSendType" SG_ 960 ZAS_Kl_50 3;
BA_ "GenSigSwitchedByIgnition" SG_ 960 ZAS_Kl_Infotainment 0;
BA_ "GenSigSendType" SG_ 960 ZAS_Kl_Infotainment 3;
BA_ "GenSigSwitchedByIgnition" SG_ 959 KL_Drehz_Anh 0;
BA_ "GenSigSendType" SG_ 959 KL_Drehz_Anh 0;
BA_ "GenSigSwitchedByIgnition" SG_ 959 KL_Vorwarn_Komp_ein 0;
BA_ "GenSigSendType" SG_ 959 KL_Vorwarn_Komp_ein 0;
BA_ "GenSigSwitchedByIgnition" SG_ 959 KL_Handshake_BEM 0;
BA_ "GenSigSendType" SG_ 959 KL_Handshake_BEM 0;
BA_ "GenSigSwitchedByIgnition" SG_ 959 KL_Komp_Moment_alt 0;
BA_ "GenSigFuncType" SG_ 959 KL_Komp_Moment_alt 5;
BA_ "GenSigSendType" SG_ 959 KL_Komp_Moment_alt 0;
BA_ "GenSigSwitchedByIgnition" SG_ 959 KL_Vorwarn_HHS_ein 0;
BA_ "GenSigSendType" SG_ 959 KL_Vorwarn_HHS_ein 0;
BA_ "GenSigSwitchedByIgnition" SG_ 959 KL_Vorwarn_HFS_ein 0;
BA_ "GenSigSendType" SG_ 959 KL_Vorwarn_HFS_ein 0;
BA_ "GenSigSwitchedByIgnition" SG_ 959 KL_Vorwarn_Zuheizer_ein 0;
BA_ "GenSigSendType" SG_ 959 KL_Vorwarn_Zuheizer_ein 0;
BA_ "GenSigSwitchedByIgnition" SG_ 959 KL_KD_Fehler 0;
BA_ "GenSigSendType" SG_ 959 KL_KD_Fehler 0;
BA_ "Fehlerwert" SG_ 959 KL_Comp_rev_rq 255;
BA_ "GenSigSwitchedByIgnition" SG_ 959 KL_Comp_rev_rq 0;
BA_ "GenSigSendType" SG_ 959 KL_Comp_rev_rq 0;
BA_ "GenSigSwitchedByIgnition" SG_ 959 KL_Charisma_FahrPr 0;
BA_ "GenSigSendType" SG_ 959 KL_Charisma_FahrPr 0;
BA_ "GenSigSwitchedByIgnition" SG_ 959 KL_Charisma_Status 0;
BA_ "GenSigSendType" SG_ 959 KL_Charisma_Status 0;
BA_ "GenSigSwitchedByIgnition" SG_ 959 KL_Charisma_Umschaltung 0;
BA_ "GenSigSendType" SG_ 959 KL_Charisma_Umschaltung 0;
BA_ "Fehlerwert" SG_ 959 KL_Last_Kompr 255;
BA_ "GenSigSwitchedByIgnition" SG_ 959 KL_Last_Kompr 0;
BA_ "GenSigSendType" SG_ 959 KL_Last_Kompr 0;
BA_ "GenSigSwitchedByIgnition" SG_ 959 KL_Leistung_Hzg_Soll 0;
BA_ "GenSigSendType" SG_ 959 KL_Leistung_Hzg_Soll 0;
BA_ "Fehlerwert" SG_ 959 KL_Anf_KL 255;
BA_ "GenSigSwitchedByIgnition" SG_ 959 KL_Anf_KL 0;
BA_ "GenSigSendType" SG_ 959 KL_Anf_KL 0;
BA_ "GenSigSwitchedByIgnition" SG_ 959 KL_4_Zonen 0;
BA_ "GenSigSendType" SG_ 959 KL_4_Zonen 0;
BA_ "GenSigSwitchedByIgnition" SG_ 959 KL_AC_Schalter 0;
BA_ "GenSigSendType" SG_ 959 KL_AC_Schalter 0;
BA_ "GenSigSwitchedByIgnition" SG_ 959 KL_Zustand 0;
BA_ "GenSigSendType" SG_ 959 KL_Zustand 0;
BA_ "GenSigSwitchedByIgnition" SG_ 959 KL_Thermomanagement 0;
BA_ "GenSigSendType" SG_ 959 KL_Thermomanagement 0;
BA_ "GenSigSwitchedByIgnition" SG_ 959 KL_Comp_enable 0;
BA_ "GenSigSendType" SG_ 959 KL_Comp_enable 0;
BA_ "GenSigSwitchedByIgnition" SG_ 959 KL_StartStopp_Info 0;
BA_ "GenSigSendType" SG_ 959 KL_StartStopp_Info 0;
BA_ "GenSigSwitchedByIgnition" SG_ 959 KL_el_Zuheizer_Stufe 0;
BA_ "GenSigSendType" SG_ 959 KL_el_Zuheizer_Stufe 0;
BA_ "GenSigSendType" SG_ 959 KL_Diag_Absperrvent 0;
BA_ "GenSigSwitchedByIgnition" SG_ 959 KL_nachtr_Stopp_Anf 0;
BA_ "GenSigSendType" SG_ 959 KL_nachtr_Stopp_Anf 0;
BA_ "GenSigSwitchedByIgnition" SG_ 1636 KL_Stromsparmodus 0;
BA_ "GenSigSendType" SG_ 1636 KL_Stromsparmodus 3;
BA_ "GenSigSwitchedByIgnition" SG_ 1636 KL_Spg_Hzg_aus 0;
BA_ "GenSigSendType" SG_ 1636 KL_Spg_Hzg_aus 3;
BA_ "GenSigSwitchedByIgnition" SG_ 1636 KL_AQS_Empfindlichkeit 0;
BA_ "GenSigSendType" SG_ 1636 KL_AQS_Empfindlichkeit 3;
BA_ "GenSigSwitchedByIgnition" SG_ 1636 KL_SIH_Soll_li 0;
BA_ "GenSigSendType" SG_ 1636 KL_SIH_Soll_li 3;
BA_ "GenSigSwitchedByIgnition" SG_ 1636 KL_SIH_Takt_li 0;
BA_ "GenSigSendType" SG_ 1636 KL_SIH_Takt_li 3;
BA_ "GenSigSwitchedByIgnition" SG_ 1636 KL_SIL_Soll_li 0;
BA_ "GenSigSendType" SG_ 1636 KL_SIL_Soll_li 3;
BA_ "GenSigSwitchedByIgnition" SG_ 1636 KL_LRH_aus 0;
BA_ "GenSigSendType" SG_ 1636 KL_LRH_aus 3;
BA_ "GenSigSwitchedByIgnition" SG_ 1636 KL_SIH_Soll_re 0;
BA_ "GenSigSendType" SG_ 1636 KL_SIH_Soll_re 3;
BA_ "GenSigSwitchedByIgnition" SG_ 1636 KL_SIH_Takt_re 0;
BA_ "GenSigSendType" SG_ 1636 KL_SIH_Takt_re 3;
BA_ "GenSigSwitchedByIgnition" SG_ 1636 KL_SIL_Soll_re 0;
BA_ "GenSigSendType" SG_ 1636 KL_SIL_Soll_re 3;
BA_ "GenSigSwitchedByIgnition" SG_ 1636 KL_Beschlagsgefahr 0;
BA_ "GenSigSendType" SG_ 1636 KL_Beschlagsgefahr 3;
BA_ "GenSigSwitchedByIgnition" SG_ 1636 KL_HSH_ein_Soll 0;
BA_ "GenSigSendType" SG_ 1636 KL_HSH_ein_Soll 3;
BA_ "GenSigSwitchedByIgnition" SG_ 1636 KL_HSH_Taktung 0;
BA_ "GenSigSendType" SG_ 1636 KL_HSH_Taktung 3;
BA_ "GenSigSwitchedByIgnition" SG_ 1636 KL_Zuheizer_Freigabe 0;
BA_ "GenSigSendType" SG_ 1636 KL_Zuheizer_Freigabe 3;
BA_ "GenSigSwitchedByIgnition" SG_ 1636 KL_ZHE_Status 0;
BA_ "GenSigSendType" SG_ 1636 KL_ZHE_Status 3;
BA_ "GenSigSwitchedByIgnition" SG_ 1636 KL_FSH_Status 0;
BA_ "GenSigSendType" SG_ 1636 KL_FSH_Status 3;
BA_ "GenSigSwitchedByIgnition" SG_ 1636 KL_LRH_on_off 0;
BA_ "GenSigSendType" SG_ 1636 KL_LRH_on_off 3;
BA_ "Fehlerwert" SG_ 1636 KL_Umluftklappe_Status 15;
BA_ "GenSigSwitchedByIgnition" SG_ 1636 KL_Umluftklappe_Status 0;
BA_ "GenSigStartValue" SG_ 1636 KL_Umluftklappe_Status 14;
BA_ "GenSigSendType" SG_ 1636 KL_Umluftklappe_Status 0;
BA_ "Fehlerwert" SG_ 1636 KL_Geblaese_Status 15;
BA_ "GenSigSwitchedByIgnition" SG_ 1636 KL_Geblaese_Status 0;
BA_ "GenSigStartValue" SG_ 1636 KL_Geblaese_Status 14;
BA_ "GenSigSendType" SG_ 1636 KL_Geblaese_Status 0;
BA_ "Fehlerwert" SG_ 1636 KL_I_Geblaese 255;
BA_ "GenSigSwitchedByIgnition" SG_ 1636 KL_I_Geblaese 0;
BA_ "GenSigSendType" SG_ 1636 KL_I_Geblaese 0;
BA_ "Fehlerwert" SG_ 1636 KL_Kompressorstrom_soll 1023;
BA_ "GenSigSwitchedByIgnition" SG_ 1636 KL_Kompressorstrom_soll 0;
BA_ "GenSigStartValue" SG_ 1636 KL_Kompressorstrom_soll 1022;
BA_ "GenSigSendType" SG_ 1636 KL_Kompressorstrom_soll 3;
BA_ "Fehlerwert" SG_ 1636 KL_FSH_P_Soll 63;
BA_ "GenSigSwitchedByIgnition" SG_ 1636 KL_FSH_P_Soll 0;
BA_ "GenSigSendType" SG_ 1636 KL_FSH_P_Soll 3;
BA_ "GenSigSwitchedByIgnition" SG_ 1646 KL_STL_aktiv 0;
BA_ "GenSigSendType" SG_ 1646 KL_STL_aktiv 3;
BA_ "GenSigSwitchedByIgnition" SG_ 1646 KL_STH_aktiv 0;
BA_ "GenSigSendType" SG_ 1646 KL_STH_aktiv 3;
BA_ "GenSigSwitchedByIgnition" SG_ 1646 KL_Solarluefter_aktiv 0;
BA_ "GenSigSendType" SG_ 1646 KL_Solarluefter_aktiv 3;
BA_ "GenSigSwitchedByIgnition" SG_ 1646 KL_Umluft_Taste 0;
BA_ "GenSigSendType" SG_ 1646 KL_Umluft_Taste 3;
BA_ "Fehlerwert" SG_ 1646 KL_Geblaese_Fond_Status 15;
BA_ "GenSigSwitchedByIgnition" SG_ 1646 KL_Geblaese_Fond_Status 0;
BA_ "GenSigStartValue" SG_ 1646 KL_Geblaese_Fond_Status 14;
BA_ "GenSigSendType" SG_ 1646 KL_Geblaese_Fond_Status 0;
BA_ "GenSigSwitchedByIgnition" SG_ 1646 KL_STH_Ansteuerung 0;
BA_ "GenSigSendType" SG_ 1646 KL_STH_Ansteuerung 3;
BA_ "GenSigSwitchedByIgnition" SG_ 1646 KL_STH_Betriebsdauer 0;
BA_ "GenSigSendType" SG_ 1646 KL_STH_Betriebsdauer 3;
BA_ "GenSigSwitchedByIgnition" SG_ 1646 KL_Magnetventil 0;
BA_ "GenSigSendType" SG_ 1646 KL_Magnetventil 3;
BA_ "GenSigSwitchedByIgnition" SG_ 1646 KL_WaPu 0;
BA_ "GenSigSendType" SG_ 1646 KL_WaPu 3;
BA_ "GenSigSwitchedByIgnition" SG_ 1646 KL_Freigabe_KRH_li 0;
BA_ "GenSigSendType" SG_ 1646 KL_Freigabe_KRH_li 3;
BA_ "GenSigSwitchedByIgnition" SG_ 1646 KL_Freigabe_KRH_re 0;
BA_ "GenSigSendType" SG_ 1646 KL_Freigabe_KRH_re 3;
BA_ "GenSigSwitchedByIgnition" SG_ 1646 KL_BCmE_Livetip_Freigabe 0;
BA_ "GenSigSendType" SG_ 1646 KL_BCmE_Livetip_Freigabe 3;
BA_ "GenSigSwitchedByIgnition" SG_ 1646 KL_HYB_ASV_hinten_schliessen_Anf 0;
BA_ "GenSigSendType" SG_ 1646 KL_HYB_ASV_hinten_schliessen_Anf 3;
BA_ "GenSigSwitchedByIgnition" SG_ 1646 KL_HYB_ASV_vorne_schliessen_Anf 0;
BA_ "GenSigSendType" SG_ 1646 KL_HYB_ASV_vorne_schliessen_Anf 3;
BA_ "GenSigSwitchedByIgnition" SG_ 1646 KL_HYB_Spuelbetrieb_Freigabe 0;
BA_ "GenSigSendType" SG_ 1646 KL_HYB_Spuelbetrieb_Freigabe 3;
BA_ "GenSigSendType" SG_ 1646 KL_Fehler_ElWaPu 0;
BA_ "Fehlerwert" SG_ 1646 KL_Innen_Temp 255;
BA_ "GenSigSwitchedByIgnition" SG_ 1646 KL_Innen_Temp 0;
BA_ "GenSigStartValue" SG_ 1646 KL_Innen_Temp 254;
BA_ "GenSigSendType" SG_ 1646 KL_Innen_Temp 0;
BA_ "GenSigSwitchedByIgnition" SG_ 1646 KL_Sonnenintensitaet 0;
BA_ "GenSigSendType" SG_ 1646 KL_Sonnenintensitaet 0;
BA_ "GenSigMissingSourceValue" SG_ 1646 KL_AussenTemp_WK 255;
BA_ "Fehlerwert" SG_ 1646 KL_AussenTemp_WK 255;
BA_ "GenSigSwitchedByIgnition" SG_ 1646 KL_AussenTemp_WK 0;
BA_ "GenSigStartValue" SG_ 1646 KL_AussenTemp_WK 254;
BA_ "GenSigSendType" SG_ 1646 KL_AussenTemp_WK 0;
BA_ "GenSigSendType" SG_ 1625 EKL_KD_Fehler 0;
BA_ "GenSigSendType" SG_ 1625 EKL_Comp_SCI_com_stat 0;
BA_ "GenSigSendType" SG_ 1625 EKL_Comp_output_stat 0;
BA_ "GenSigSendType" SG_ 1625 EKL_Comp_main_stat 0;
BA_ "GenSigSendType" SG_ 1625 EKL_Comp_ovld_stat 0;
BA_ "GenSigSendType" SG_ 1625 EKL_Comp_Inv_stat 0;
BA_ "GenSigSendType" SG_ 1625 EKL_Comp_photo_temp_stat 0;
BA_ "Fehlerwert" SG_ 1625 EKL_Comp_photo_temp 255;
BA_ "GenSigStartValue" SG_ 1625 EKL_Comp_photo_temp 255;
BA_ "GenSigSendType" SG_ 1625 EKL_Comp_photo_temp 0;
BA_ "GenSigStartValue" SG_ 1625 EKL_Comp_current 255;
BA_ "GenSigSendType" SG_ 1625 EKL_Comp_current 0;
BA_ "Fehlerwert" SG_ 1625 EKL_Comp_rev_stat 255;
BA_ "GenSigSendType" SG_ 1625 EKL_Comp_rev_stat 0;
BA_ "GenSigSwitchedByIgnition" SG_ 779 KBI_ABS_Lampe 0;
BA_ "GenSigSendType" SG_ 779 KBI_ABS_Lampe 0;
BA_ "GenSigSwitchedByIgnition" SG_ 779 KBI_ESP_Lampe 0;
BA_ "GenSigSendType" SG_ 779 KBI_ESP_Lampe 0;
BA_ "GenSigSwitchedByIgnition" SG_ 779 KBI_BKL_Lampe 0;
BA_ "GenSigSendType" SG_ 779 KBI_BKL_Lampe 0;
BA_ "GenSigSwitchedByIgnition" SG_ 779 KBI_Airbag_Lampe 0;
BA_ "GenSigSendType" SG_ 779 KBI_Airbag_Lampe 0;
BA_ "GenSigSwitchedByIgnition" SG_ 779 KBI_SILA_gueltig 0;
BA_ "GenSigSendType" SG_ 779 KBI_SILA_gueltig 0;
BA_ "GenSigSwitchedByIgnition" SG_ 779 KBI_Lenkung_Lampe 0;
BA_ "GenSigSendType" SG_ 779 KBI_Lenkung_Lampe 0;
BA_ "GenSigSwitchedByIgnition" SG_ 779 KBI_Vorglueh_System_Lampe 0;
BA_ "GenSigSendType" SG_ 779 KBI_Vorglueh_System_Lampe 0;
BA_ "GenSigSwitchedByIgnition" SG_ 779 KBI_NV_in_Anzeige 0;
BA_ "GenSigSendType" SG_ 779 KBI_NV_in_Anzeige 0;
BA_ "GenSigSwitchedByIgnition" SG_ 779 Kombi_01_BZ 0;
BA_ "GenSigFuncType" SG_ 779 Kombi_01_BZ 1;
BA_ "GenSigSendType" SG_ 779 Kombi_01_BZ 0;
BA_ "GenSigSwitchedByIgnition" SG_ 779 KBI_Anzeigestatus_ACC 0;
BA_ "GenSigSendType" SG_ 779 KBI_Anzeigestatus_ACC 0;
BA_ "GenSigSwitchedByIgnition" SG_ 779 KBI_Oeldruck_Schalter 0;
BA_ "GenSigSendType" SG_ 779 KBI_Oeldruck_Schalter 0;
BA_ "GenSigSwitchedByIgnition" SG_ 779 KBI_Tankwarnung 0;
BA_ "GenSigSendType" SG_ 779 KBI_Tankwarnung 0;
BA_ "GenSigSwitchedByIgnition" SG_ 779 KBI_MFA_v_Einheit_01 0;
BA_ "GenSigSendType" SG_ 779 KBI_MFA_v_Einheit_01 0;
BA_ "GenSigSwitchedByIgnition" SG_ 779 KBI_im_Stellgliedtest 0;
BA_ "GenSigSendType" SG_ 779 KBI_im_Stellgliedtest 0;
BA_ "GenSigSwitchedByIgnition" SG_ 779 KBI_Anzeigefehler_LDW 0;
BA_ "GenSigSendType" SG_ 779 KBI_Anzeigefehler_LDW 0;
BA_ "GenSigSwitchedByIgnition" SG_ 779 KBI_Variante_USA 0;
BA_ "GenSigSendType" SG_ 779 KBI_Variante_USA 0;
BA_ "GenSigSwitchedByIgnition" SG_ 779 KBI_Oeldruckwarnung 0;
BA_ "GenSigSendType" SG_ 779 KBI_Oeldruckwarnung 0;
BA_ "GenSigSwitchedByIgnition" SG_ 779 KBI_Handbremse 0;
BA_ "GenSigSendType" SG_ 779 KBI_Handbremse 0;
BA_ "GenSigSwitchedByIgnition" SG_ 779 KBI_V_Digital 0;
BA_ "GenSigSendType" SG_ 779 KBI_V_Digital 0;
BA_ "GenSigSwitchedByIgnition" SG_ 779 KBI_PLA_in_Anzeige 0;
BA_ "GenSigSendType" SG_ 779 KBI_PLA_in_Anzeige 0;
BA_ "GenSigSwitchedByIgnition" SG_ 779 KBI_Anzeigefehler_NV 0;
BA_ "GenSigSendType" SG_ 779 KBI_Anzeigefehler_NV 0;
BA_ "GenSigSwitchedByIgnition" SG_ 779 KBI_angez_Geschw 0;
BA_ "GenSigSendType" SG_ 779 KBI_angez_Geschw 0;
BA_ "GenSigSwitchedByIgnition" SG_ 779 KBI_Einheit_Tacho 0;
BA_ "GenSigSendType" SG_ 779 KBI_Einheit_Tacho 0;
BA_ "GenSigSwitchedByIgnition" SG_ 779 KBI_Konsistenz_ACC 0;
BA_ "GenSigSendType" SG_ 779 KBI_Konsistenz_ACC 0;
BA_ "GenSigSwitchedByIgnition" SG_ 779 KBI_Fehler_Anzeige_ACC 0;
BA_ "GenSigSendType" SG_ 779 KBI_Fehler_Anzeige_ACC 0;
BA_ "GenSigSwitchedByIgnition" SG_ 779 KBI_Anzeigefehler_SWA 0;
BA_ "GenSigSendType" SG_ 779 KBI_Anzeigefehler_SWA 0;
BA_ "GenSigSwitchedByIgnition" SG_ 779 KBI_KD_Fehler 0;
BA_ "GenSigSendType" SG_ 779 KBI_KD_Fehler 0;
BA_ "Fehlerwert" SG_ 1719 KBI_Kilometerstand 1048575;
BA_ "GenSigSwitchedByIgnition" SG_ 1719 KBI_Kilometerstand 0;
BA_ "GenSigStartValue" SG_ 1719 KBI_Kilometerstand 1048574;
BA_ "GenSigSendType" SG_ 1719 KBI_Kilometerstand 0;
BA_ "GenSigSwitchedByIgnition" SG_ 1719 KBI_Standzeit 0;
BA_ "GenSigSendType" SG_ 1719 KBI_Standzeit 0;
BA_ "GenSigSwitchedByIgnition" SG_ 1719 KBI_Reset_Standzeit 0;
BA_ "GenSigSendType" SG_ 1719 KBI_Reset_Standzeit 0;
BA_ "Fehlerwert" SG_ 1719 KBI_Inhalt_Tank 127;
BA_ "GenSigSwitchedByIgnition" SG_ 1719 KBI_Inhalt_Tank 0;
BA_ "GenSigSendType" SG_ 1719 KBI_Inhalt_Tank 0;
BA_ "GenSigSwitchedByIgnition" SG_ 1719 KBI_FStatus_Tank 0;
BA_ "GenSigSendType" SG_ 1719 KBI_FStatus_Tank 0;
BA_ "GenSigSwitchedByIgnition" SG_ 1719 KBI_Oelwechsel_durchgefuehrt 0;
BA_ "GenSigSendType" SG_ 1719 KBI_Oelwechsel_durchgefuehrt 0;
BA_ "GenSigSwitchedByIgnition" SG_ 1719 KBI_QBit_Aussen_Temp_gef 0;
BA_ "GenSigStartValue" SG_ 1719 KBI_QBit_Aussen_Temp_gef 1;
BA_ "GenSigSendType" SG_ 1719 KBI_QBit_Aussen_Temp_gef 0;
BA_ "Fehlerwert" SG_ 1719 KBI_Aussen_Temp_gef 255;
BA_ "GenSigSwitchedByIgnition" SG_ 1719 KBI_Aussen_Temp_gef 0;
BA_ "GenSigStartValue" SG_ 1719 KBI_Aussen_Temp_gef 254;
BA_ "GenSigSendType" SG_ 1719 KBI_Aussen_Temp_gef 0;
BA_ "GenSigSwitchedByIgnition" SG_ 1720 KBI_Reifenumfang 0;
BA_ "GenSigFuncType" SG_ 1720 KBI_Reifenumfang 8;
BA_ "GenSigSendType" SG_ 1720 KBI_Reifenumfang 0;
BA_ "GenSigSwitchedByIgnition" SG_ 1720 KBI_BCmE_aktiv 0;
BA_ "GenSigSendType" SG_ 1720 KBI_BCmE_aktiv 0;
BA_ "GenSigSwitchedByIgnition" SG_ 1720 KBI_Sparhinweis_quittiert 0;
BA_ "GenSigSendType" SG_ 1720 KBI_Sparhinweis_quittiert 0;
BA_ "Fehlerwert" SG_ 1720 KBI_Tankfuellstand_Prozent 127;
BA_ "GenSigSwitchedByIgnition" SG_ 1720 KBI_Tankfuellstand_Prozent 0;
BA_ "GenSigStartValue" SG_ 1720 KBI_Tankfuellstand_Prozent 126;
BA_ "GenSigSendType" SG_ 1720 KBI_Tankfuellstand_Prozent 0;
BA_ "GenSigSendType" SG_ 517 KS_Airbag_Data 3;
BA_ "GenSigSwitchedByIgnition" SG_ 640 KS_Master_Data 0;
BA_ "GenSigSendType" SG_ 640 KS_Master_Data 3;
BA_ "GenSigSwitchedByIgnition" SG_ 285 EPS_02_CRC 0;
BA_ "GenSigFuncType" SG_ 285 EPS_02_CRC 2;
BA_ "GenSigSendType" SG_ 285 EPS_02_CRC 0;
BA_ "GenSigSwitchedByIgnition" SG_ 285 EPS_02_BZ 0;
BA_ "GenSigFuncType" SG_ 285 EPS_02_BZ 1;
BA_ "GenSigSendType" SG_ 285 EPS_02_BZ 0;
BA_ "GenSigSwitchedByIgnition" SG_ 285 EPS_Notlauf 0;
BA_ "GenSigSendType" SG_ 285 EPS_Notlauf 0;
BA_ "Fehlerwert" SG_ 285 EPS_Lastinfo 255;
BA_ "GenSigSwitchedByIgnition" SG_ 285 EPS_Lastinfo 0;
BA_ "GenSigStartValue" SG_ 285 EPS_Lastinfo 254;
BA_ "GenSigSendType" SG_ 285 EPS_Lastinfo 0;
BA_ "Fehlerwert" SG_ 285 EPS_Unterstuetzungsleistung 255;
BA_ "GenSigSwitchedByIgnition" SG_ 285 EPS_Unterstuetzungsleistung 0;
BA_ "GenSigStartValue" SG_ 285 EPS_Unterstuetzungsleistung 254;
BA_ "GenSigSendType" SG_ 285 EPS_Unterstuetzungsleistung 0;
BA_ "Fehlerwert" SG_ 285 EPS_Drehzahlreserve 127;
BA_ "GenSigSwitchedByIgnition" SG_ 285 EPS_Drehzahlreserve 0;
BA_ "GenSigStartValue" SG_ 285 EPS_Drehzahlreserve 126;
BA_ "GenSigSendType" SG_ 285 EPS_Drehzahlreserve 0;
BA_ "GenSigSwitchedByIgnition" SG_ 285 EPS_VZ_Drehzahlreserve 0;
BA_ "GenSigSendType" SG_ 285 EPS_VZ_Drehzahlreserve 0;
BA_ "GenSigSwitchedByIgnition" SG_ 285 EPS_Leistungsanforderung 0;
BA_ "GenSigSendType" SG_ 285 EPS_Leistungsanforderung 0;
BA_ "GenSigSwitchedByIgnition" SG_ 285 EPS_StartStopp_Info 0;
BA_ "GenSigSendType" SG_ 285 EPS_StartStopp_Info 0;
BA_ "GenSigSwitchedByIgnition" SG_ 285 EPS_Motorstartverzoegerung 0;
BA_ "GenSigSendType" SG_ 285 EPS_Motorstartverzoegerung 0;
BA_ "GenSigSwitchedByIgnition" SG_ 1137 Licht_hinten_01_BZ 0;
BA_ "GenSigFuncType" SG_ 1137 Licht_hinten_01_BZ 1;
BA_ "GenSigSendType" SG_ 1137 Licht_hinten_01_BZ 0;
BA_ "GenSigSwitchedByIgnition" SG_ 1137 BCM2_Bremsl_durch_ECD 0;
BA_ "GenSigSendType" SG_ 1137 BCM2_Bremsl_durch_ECD 0;
BA_ "GenSigSwitchedByIgnition" SG_ 1137 LH_Aussenlicht_def 0;
BA_ "GenSigSendType" SG_ 1137 LH_Aussenlicht_def 0;
BA_ "GenSigSwitchedByIgnition" SG_ 1137 LH_Standlicht_H_aktiv 0;
BA_ "GenSigSendType" SG_ 1137 LH_Standlicht_H_aktiv 0;
BA_ "GenSigSwitchedByIgnition" SG_ 1137 LH_Parklicht_HL_aktiv 0;
BA_ "GenSigSendType" SG_ 1137 LH_Parklicht_HL_aktiv 0;
BA_ "GenSigSwitchedByIgnition" SG_ 1137 LH_Parklicht_HR_aktiv 0;
BA_ "GenSigSendType" SG_ 1137 LH_Parklicht_HR_aktiv 0;
BA_ "GenSigSwitchedByIgnition" SG_ 1137 LH_Bremslicht_H_aktiv 0;
BA_ "GenSigSendType" SG_ 1137 LH_Bremslicht_H_aktiv 0;
BA_ "GenSigSwitchedByIgnition" SG_ 1137 LH_Nebelschluss_aktiv 0;
BA_ "GenSigSendType" SG_ 1137 LH_Nebelschluss_aktiv 0;
BA_ "GenSigSwitchedByIgnition" SG_ 1137 LH_Rueckfahrlicht_aktiv 0;
BA_ "GenSigSendType" SG_ 1137 LH_Rueckfahrlicht_aktiv 0;
BA_ "GenSigSwitchedByIgnition" SG_ 1137 LH_Blinker_HL_akt 0;
BA_ "GenSigSendType" SG_ 1137 LH_Blinker_HL_akt 0;
BA_ "GenSigSwitchedByIgnition" SG_ 1137 LH_Blinker_HR_akt 0;
BA_ "GenSigSendType" SG_ 1137 LH_Blinker_HR_akt 0;
BA_ "GenSigSwitchedByIgnition" SG_ 1137 LH_Blinker_li_def 0;
BA_ "GenSigSendType" SG_ 1137 LH_Blinker_li_def 0;
BA_ "GenSigSwitchedByIgnition" SG_ 1137 LH_Bremsl_li_def 0;
BA_ "GenSigSendType" SG_ 1137 LH_Bremsl_li_def 0;
BA_ "GenSigSwitchedByIgnition" SG_ 1137 LH_Schlusslicht_li_def 0;
BA_ "GenSigSendType" SG_ 1137 LH_Schlusslicht_li_def 0;
BA_ "GenSigSwitchedByIgnition" SG_ 1137 LH_Rueckf_li_def 0;
BA_ "GenSigSendType" SG_ 1137 LH_Rueckf_li_def 0;
BA_ "GenSigSwitchedByIgnition" SG_ 1137 LH_Nebel_li_def 0;
BA_ "GenSigSendType" SG_ 1137 LH_Nebel_li_def 0;
BA_ "GenSigSwitchedByIgnition" SG_ 1137 LH_Schluss_Brems_Nebel_li_def 0;
BA_ "GenSigSendType" SG_ 1137 LH_Schluss_Brems_Nebel_li_def 0;
BA_ "GenSigSwitchedByIgnition" SG_ 1137 LH_Schluss_Brems_Nebel_re_def 0;
BA_ "GenSigSendType" SG_ 1137 LH_Schluss_Brems_Nebel_re_def 0;
BA_ "GenSigSwitchedByIgnition" SG_ 1137 LH_Schluss_Brems_li_def 0;
BA_ "GenSigSendType" SG_ 1137 LH_Schluss_Brems_li_def 0;
BA_ "GenSigSwitchedByIgnition" SG_ 1137 LH_Schluss_Nebel_li_def 0;
BA_ "GenSigSendType" SG_ 1137 LH_Schluss_Nebel_li_def 0;
BA_ "GenSigSwitchedByIgnition" SG_ 1137 LH_SL_BRL_BLK_li_def 0;
BA_ "GenSigSendType" SG_ 1137 LH_SL_BRL_BLK_li_def 0;
BA_ "GenSigSwitchedByIgnition" SG_ 1137 LH_Brems_Blk_li_def 0;
BA_ "GenSigSendType" SG_ 1137 LH_Brems_Blk_li_def 0;
BA_ "GenSigSwitchedByIgnition" SG_ 1137 LH_Blinker_re_def 0;
BA_ "GenSigSendType" SG_ 1137 LH_Blinker_re_def 0;
BA_ "GenSigSwitchedByIgnition" SG_ 1137 LH_Bremsl_re_def 0;
BA_ "GenSigSendType" SG_ 1137 LH_Bremsl_re_def 0;
BA_ "GenSigSwitchedByIgnition" SG_ 1137 LH_Schlusslicht_re_def 0;
BA_ "GenSigSendType" SG_ 1137 LH_Schlusslicht_re_def 0;
BA_ "GenSigSwitchedByIgnition" SG_ 1137 LH_Rueckf_re_def 0;
BA_ "GenSigSendType" SG_ 1137 LH_Rueckf_re_def 0;
BA_ "GenSigSwitchedByIgnition" SG_ 1137 LH_Nebel_re_def 0;
BA_ "GenSigSendType" SG_ 1137 LH_Nebel_re_def 0;
BA_ "GenSigSwitchedByIgnition" SG_ 1137 LH_Schluss_Brems_re_def 0;
BA_ "GenSigSendType" SG_ 1137 LH_Schluss_Brems_re_def 0;
BA_ "GenSigSwitchedByIgnition" SG_ 1137 LH_Schluss_Nebel_re_def 0;
BA_ "GenSigSendType" SG_ 1137 LH_Schluss_Nebel_re_def 0;
BA_ "GenSigSwitchedByIgnition" SG_ 1137 LH_SL_BRL_BLK_re_def 0;
BA_ "GenSigSendType" SG_ 1137 LH_SL_BRL_BLK_re_def 0;
BA_ "GenSigSwitchedByIgnition" SG_ 1137 LH_Brems_Blk_re_def 0;
BA_ "GenSigSendType" SG_ 1137 LH_Brems_Blk_re_def 0;
BA_ "GenSigSwitchedByIgnition" SG_ 1137 LH_Kennzl_def 0;
BA_ "GenSigSendType" SG_ 1137 LH_Kennzl_def 0;
BA_ "GenSigSwitchedByIgnition" SG_ 1137 LH_3_Bremsl_def 0;
BA_ "GenSigSendType" SG_ 1137 LH_3_Bremsl_def 0;
BA_ "GenSigSwitchedByIgnition" SG_ 1137 LH_Nebel_mi_def 0;
BA_ "GenSigSendType" SG_ 1137 LH_Nebel_mi_def 0;
BA_ "GenSigSwitchedByIgnition" SG_ 1137 LH_Rueckf_mi_def 0;
BA_ "GenSigSendType" SG_ 1137 LH_Rueckf_mi_def 0;
BA_ "GenSigSwitchedByIgnition" SG_ 1137 LH_Bremsl_li_ges_def 0;
BA_ "GenSigSendType" SG_ 1137 LH_Bremsl_li_ges_def 0;
BA_ "GenSigSwitchedByIgnition" SG_ 1137 LH_Bremsl_re_ges_def 0;
BA_ "GenSigSendType" SG_ 1137 LH_Bremsl_re_ges_def 0;
BA_ "GenSigFuncType" SG_ 267 LS_01_CHK 3;
BA_ "GenSigSendType" SG_ 267 LS_01_CHK 0;
BA_ "GenSigFuncType" SG_ 267 LS_01_BZ 1;
BA_ "GenSigSendType" SG_ 267 LS_01_BZ 0;
BA_ "GenSigSendType" SG_ 267 LS_Hauptschalter 3;
BA_ "GenSigSendType" SG_ 267 LS_Abbrechen 6;
BA_ "GenSigSendType" SG_ 267 LS_Typ_Hauptschalter 3;
BA_ "GenSigSendType" SG_ 267 LS_Limiter 3;
BA_ "GenSigSendType" SG_ 267 LS_Tip_Setzen 6;
BA_ "GenSigSendType" SG_ 267 LS_Tip_Hoch 6;
BA_ "GenSigSendType" SG_ 267 LS_Tip_Runter 6;
BA_ "GenSigSendType" SG_ 267 LS_Tip_Wiederaufnahme 6;
BA_ "GenSigSendType" SG_ 267 LS_Verstellung_Zeitluecke 6;
BA_ "GenSigSendType" SG_ 267 MFL_Tip_Down 6;
BA_ "GenSigSendType" SG_ 267 MFL_Tip_Up 6;
BA_ "GenSigSendType" SG_ 267 LS_Tiptronic_Fehler 3;
BA_ "GenSigSendType" SG_ 267 LS_Fehler 3;
BA_ "GenSigSendType" SG_ 267 LS_Codierung 3;
BA_ "GenSigSendType" SG_ 267 LS_Tip_Stufe_2 3;
BA_ "GenSigSendType" SG_ 267 LS_GRA_ACC_2stufig 0;
BA_ "GenSigSendType" SG_ 267 MFL_M_Taste 3;
BA_ "GenSigFuncType" SG_ 134 LWI_01_CHK 3;
BA_ "GenSigSendType" SG_ 134 LWI_01_CHK 0;
BA_ "GenSigFuncType" SG_ 134 LWI_01_BZ 1;
BA_ "GenSigSendType" SG_ 134 LWI_01_BZ 0;
BA_ "GenSigSendType" SG_ 134 LWI_Sensorstatus 0;
BA_ "GenSigSendType" SG_ 134 LWI_QBit_Sub_Daten 0;
BA_ "GenSigStartValue" SG_ 134 LWI_QBit_Lenkradwinkel 1;
BA_ "GenSigSendType" SG_ 134 LWI_QBit_Lenkradwinkel 0;
BA_ "Fehlerwert" SG_ 134 LWI_Lenkradwinkel 8191;
BA_ "GenSigStartValue" SG_ 134 LWI_Lenkradwinkel 8190;
BA_ "GenSigSendType" SG_ 134 LWI_Lenkradwinkel 0;
BA_ "GenSigSendType" SG_ 134 LWI_VZ_Lenkradwinkel 0;
BA_ "GenSigSendType" SG_ 134 LWI_VZ_Lenkradw_Geschw 0;
BA_ "Fehlerwert" SG_ 134 LWI_Lenkradw_Geschw 511;
BA_ "GenSigStartValue" SG_ 134 LWI_Lenkradw_Geschw 510;
BA_ "GenSigSendType" SG_ 134 LWI_Lenkradw_Geschw 0;
BA_ "GenSigSendType" SG_ 134 LWI_Sub_Daten 0;
BA_ "GenSigFuncType" SG_ 134 LWI_01_CRC 2;
BA_ "GenSigSendType" SG_ 134 LWI_01_CRC 0;
BA_ "GenSigSwitchedByIgnition" SG_ 128 Motor_01_CHK 0;
BA_ "GenSigFuncType" SG_ 128 Motor_01_CHK 3;
BA_ "GenSigSendType" SG_ 128 Motor_01_CHK 0;
BA_ "GenSigSwitchedByIgnition" SG_ 128 Motor_01_BZ 0;
BA_ "GenSigFuncType" SG_ 128 Motor_01_BZ 1;
BA_ "GenSigSendType" SG_ 128 Motor_01_BZ 0;
BA_ "Fehlerwert" SG_ 128 MO_Mom_o_ex 1023;
BA_ "GenSigSwitchedByIgnition" SG_ 128 MO_Mom_o_ex 0;
BA_ "GenSigStartValue" SG_ 128 MO_Mom_o_ex 1022;
BA_ "GenSigSendType" SG_ 128 MO_Mom_o_ex 0;
BA_ "Fehlerwert" SG_ 128 MO_Mom_m_ex 1023;
BA_ "GenSigSwitchedByIgnition" SG_ 128 MO_Mom_m_ex 0;
BA_ "GenSigStartValue" SG_ 128 MO_Mom_m_ex 1022;
BA_ "GenSigSendType" SG_ 128 MO_Mom_m_ex 0;
BA_ "Fehlerwert" SG_ 128 MO_Mom_Verlust 1023;
BA_ "GenSigSwitchedByIgnition" SG_ 128 MO_Mom_Verlust 0;
BA_ "GenSigStartValue" SG_ 128 MO_Mom_Verlust 1022;
BA_ "GenSigSendType" SG_ 128 MO_Mom_Verlust 0;
BA_ "Fehlerwert" SG_ 128 MO_Mom_Begrenzung 1023;
BA_ "GenSigSwitchedByIgnition" SG_ 128 MO_Mom_Begrenzung 0;
BA_ "GenSigStartValue" SG_ 128 MO_Mom_Begrenzung 1022;
BA_ "GenSigSendType" SG_ 128 MO_Mom_Begrenzung 0;
BA_ "Fehlerwert" SG_ 128 MO_Mom_Fahrerwunsch 1023;
BA_ "GenSigSwitchedByIgnition" SG_ 128 MO_Mom_Fahrerwunsch 0;
BA_ "GenSigStartValue" SG_ 128 MO_Mom_Fahrerwunsch 1022;
BA_ "GenSigSendType" SG_ 128 MO_Mom_Fahrerwunsch 0;
BA_ "GenSigSwitchedByIgnition" SG_ 128 MO_Kickdown 0;
BA_ "GenSigSendType" SG_ 128 MO_Kickdown 0;
BA_ "GenSigSwitchedByIgnition" SG_ 128 MO_KD_Fehler 0;
BA_ "GenSigSendType" SG_ 128 MO_KD_Fehler 0;
BA_ "GenSigSwitchedByIgnition" SG_ 129 Motor_02_CHK 0;
BA_ "GenSigFuncType" SG_ 129 Motor_02_CHK 4;
BA_ "GenSigSendType" SG_ 129 Motor_02_CHK 0;
BA_ "GenSigSwitchedByIgnition" SG_ 129 Motor_02_BZ 0;
BA_ "GenSigFuncType" SG_ 129 Motor_02_BZ 1;
BA_ "GenSigSendType" SG_ 129 Motor_02_BZ 0;
BA_ "Fehlerwert" SG_ 129 MO_Mom_ZWR 1023;
BA_ "GenSigSwitchedByIgnition" SG_ 129 MO_Mom_ZWR 0;
BA_ "GenSigStartValue" SG_ 129 MO_Mom_ZWR 1022;
BA_ "GenSigSendType" SG_ 129 MO_Mom_ZWR 0;
BA_ "Fehlerwert" SG_ 129 MO_Mom_Soll 1023;
BA_ "GenSigSwitchedByIgnition" SG_ 129 MO_Mom_Soll 0;
BA_ "GenSigStartValue" SG_ 129 MO_Mom_Soll 1022;
BA_ "GenSigSendType" SG_ 129 MO_Mom_Soll 0;
BA_ "Fehlerwert" SG_ 129 MO_Mom_Ist 1023;
BA_ "GenSigSwitchedByIgnition" SG_ 129 MO_Mom_Ist 0;
BA_ "GenSigStartValue" SG_ 129 MO_Mom_Ist 1022;
BA_ "GenSigSendType" SG_ 129 MO_Mom_Ist 0;
BA_ "GenSigSwitchedByIgnition" SG_ 129 MO_Status_Zylabschalt_01 0;
BA_ "GenSigSendType" SG_ 129 MO_Status_Zylabschalt_01 0;
BA_ "GenSigSwitchedByIgnition" SG_ 129 MO_Status_Normalbetrieb_01 0;
BA_ "GenSigSendType" SG_ 129 MO_Status_Normalbetrieb_01 0;
BA_ "GenSigSwitchedByIgnition" SG_ 129 MO_StartStopp_Status 0;
BA_ "GenSigSendType" SG_ 129 MO_StartStopp_Status 0;
BA_ "GenSigSwitchedByIgnition" SG_ 129 MO_StartStopp_Motorstopp 0;
BA_ "GenSigSendType" SG_ 129 MO_StartStopp_Motorstopp 0;
BA_ "GenSigSwitchedByIgnition" SG_ 129 MO_StartStopp_Wiederstart 0;
BA_ "GenSigSendType" SG_ 129 MO_StartStopp_Wiederstart 0;
BA_ "GenSigSwitchedByIgnition" SG_ 129 MO_Ext_E_Fahrt_aktiv 0;
BA_ "NWM-WakeupAllowed" SG_ 129 MO_Ext_E_Fahrt_aktiv 1;
BA_ "GenSigSendType" SG_ 129 MO_Ext_E_Fahrt_aktiv 0;
BA_ "Fehlerwert" SG_ 129 MO_Gangposition 15;
BA_ "GenSigSwitchedByIgnition" SG_ 129 MO_Gangposition 0;
BA_ "GenSigStartValue" SG_ 129 MO_Gangposition 14;
BA_ "GenSigSendType" SG_ 129 MO_Gangposition 0;
BA_ "GenSigSwitchedByIgnition" SG_ 129 MO_StartStopp_Fahrerwunsch 0;
BA_ "GenSigSendType" SG_ 129 MO_StartStopp_Fahrerwunsch 0;
BA_ "GenSigSwitchedByIgnition" SG_ 129 MO_StartStopp_StoppVorbereitung 0;
BA_ "GenSigSendType" SG_ 129 MO_StartStopp_StoppVorbereitung 0;
BA_ "GenSigSwitchedByIgnition" SG_ 129 MO_Momentenintegral 0;
BA_ "GenSigSendType" SG_ 129 MO_Momentenintegral 0;
BA_ "GenSigSwitchedByIgnition" SG_ 261 Motor_03_CHK 0;
BA_ "GenSigFuncType" SG_ 261 Motor_03_CHK 3;
BA_ "GenSigSendType" SG_ 261 Motor_03_CHK 0;
BA_ "GenSigSwitchedByIgnition" SG_ 261 Motor_03_BZ 0;
BA_ "GenSigFuncType" SG_ 261 Motor_03_BZ 1;
BA_ "GenSigSendType" SG_ 261 Motor_03_BZ 0;
BA_ "GenSigSwitchedByIgnition" SG_ 261 MO_QBit_Fahrpedalwerte_01 0;
BA_ "GenSigStartValue" SG_ 261 MO_QBit_Fahrpedalwerte_01 1;
BA_ "GenSigSendType" SG_ 261 MO_QBit_Fahrpedalwerte_01 0;
BA_ "GenSigSwitchedByIgnition" SG_ 261 MO_QBit_Motormomente 0;
BA_ "GenSigStartValue" SG_ 261 MO_QBit_Motormomente 1;
BA_ "GenSigSendType" SG_ 261 MO_QBit_Motormomente 0;
BA_ "GenSigSwitchedByIgnition" SG_ 261 MO_QBit_Fahrer_bremst 0;
BA_ "GenSigStartValue" SG_ 261 MO_QBit_Fahrer_bremst 1;
BA_ "GenSigSendType" SG_ 261 MO_QBit_Fahrer_bremst 0;
BA_ "GenSigSwitchedByIgnition" SG_ 261 MO_QBit_Drehzahl_01 0;
BA_ "GenSigStartValue" SG_ 261 MO_QBit_Drehzahl_01 1;
BA_ "GenSigSendType" SG_ 261 MO_QBit_Drehzahl_01 0;
BA_ "Fehlerwert" SG_ 261 MO_Drehzahl_01 65535;
BA_ "GenSigSwitchedByIgnition" SG_ 261 MO_Drehzahl_01 0;
BA_ "GenSigSendType" SG_ 261 MO_Drehzahl_01 0;
BA_ "GenSigSwitchedByIgnition" SG_ 261 MO_Moment_im_Leerlauf 0;
BA_ "GenSigSendType" SG_ 261 MO_Moment_im_Leerlauf 0;
BA_ "GenSigSwitchedByIgnition" SG_ 261 MO_Interlock 0;
BA_ "GenSigSendType" SG_ 261 MO_Interlock 0;
BA_ "GenSigSwitchedByIgnition" SG_ 261 MO_BLS 0;
BA_ "GenSigSendType" SG_ 261 MO_BLS 0;
BA_ "GenSigSwitchedByIgnition" SG_ 261 MO_Fahrer_bremst 0;
BA_ "GenSigSendType" SG_ 261 MO_Fahrer_bremst 0;
BA_ "GenSigSwitchedByIgnition" SG_ 261 MO_Konsistenz_Bremsped 0;
BA_ "GenSigSendType" SG_ 261 MO_Konsistenz_Bremsped 0;
BA_ "GenSigSwitchedByIgnition" SG_ 261 MO_Kuppl_schalter 0;
BA_ "GenSigSendType" SG_ 261 MO_Kuppl_schalter 0;
BA_ "GenSigSwitchedByIgnition" SG_ 261 MO_Timeout_ESP 0;
BA_ "GenSigSendType" SG_ 261 MO_Timeout_ESP 0;
BA_ "GenSigSwitchedByIgnition" SG_ 261 MO_Motor_laeuft 0;
BA_ "GenSigSendType" SG_ 261 MO_Motor_laeuft 0;
BA_ "Fehlerwert" SG_ 261 MO_Solldrehz_Leerlauf 255;
BA_ "GenSigSwitchedByIgnition" SG_ 261 MO_Solldrehz_Leerlauf 0;
BA_ "GenSigSendType" SG_ 261 MO_Solldrehz_Leerlauf 0;
BA_ "Fehlerwert" SG_ 261 MO_Fahrpedalrohwert_01 255;
BA_ "GenSigSwitchedByIgnition" SG_ 261 MO_Fahrpedalrohwert_01 0;
BA_ "GenSigSendType" SG_ 261 MO_Fahrpedalrohwert_01 0;
BA_ "GenSigSwitchedByIgnition" SG_ 261 MO_erste_Ungenauschwelle 0;
BA_ "GenSigSendType" SG_ 261 MO_erste_Ungenauschwelle 0;
BA_ "GenSigSwitchedByIgnition" SG_ 261 MO_QBit_Stressfaktor 0;
BA_ "GenSigStartValue" SG_ 261 MO_QBit_Stressfaktor 1;
BA_ "GenSigSendType" SG_ 261 MO_QBit_Stressfaktor 0;
BA_ "GenSigSwitchedByIgnition" SG_ 261 MO_Stressfaktor 0;
BA_ "GenSigSendType" SG_ 261 MO_Stressfaktor 0;
BA_ "Fehlerwert" SG_ 263 MO_rel_Ladedruck 255;
BA_ "GenSigSwitchedByIgnition" SG_ 263 MO_rel_Ladedruck 0;
BA_ "GenSigSendType" SG_ 263 MO_rel_Ladedruck 0;
BA_ "GenSigSwitchedByIgnition" SG_ 263 MO_Istgang 0;
BA_ "GenSigSendType" SG_ 263 MO_Istgang 0;
BA_ "GenSigSwitchedByIgnition" SG_ 263 MO_Sollgang 0;
BA_ "GenSigSendType" SG_ 263 MO_Sollgang 0;
BA_ "Fehlerwert" SG_ 263 MO_Oeldruck 255;
BA_ "GenSigSwitchedByIgnition" SG_ 263 MO_Oeldruck 0;
BA_ "GenSigStartValue" SG_ 263 MO_Oeldruck 254;
BA_ "GenSigSendType" SG_ 263 MO_Oeldruck 0;
BA_ "Fehlerwert" SG_ 263 MO_Anzeigedrehz 4095;
BA_ "GenSigSwitchedByIgnition" SG_ 263 MO_Anzeigedrehz 0;
BA_ "GenSigSendType" SG_ 263 MO_Anzeigedrehz 0;
BA_ "GenSigSwitchedByIgnition" SG_ 263 MO_Effizienzmodus 0;
BA_ "GenSigSendType" SG_ 263 MO_Effizienzmodus 0;
BA_ "GenSigSwitchedByIgnition" SG_ 263 MO_Schaltempf_verfbar 0;
BA_ "GenSigFuncType" SG_ 263 MO_Schaltempf_verfbar 8;
BA_ "GenSigSendType" SG_ 263 MO_Schaltempf_verfbar 0;
BA_ "Fehlerwert" SG_ 263 MO_Ladedruck 511;
BA_ "GenSigSwitchedByIgnition" SG_ 263 MO_Ladedruck 0;
BA_ "GenSigSendType" SG_ 263 MO_Ladedruck 0;
BA_ "GenSigSwitchedByIgnition" SG_ 263 MO_KVS 0;
BA_ "GenSigSendType" SG_ 263 MO_KVS 0;
BA_ "GenSigSwitchedByIgnition" SG_ 263 MO_KVS_Ueberlauf 0;
BA_ "GenSigSendType" SG_ 263 MO_KVS_Ueberlauf 0;
BA_REL_ "GenSigTimeoutTime" BU_SG_REL_ Getriebe_DL382_MLB SG_ 960 ZAS_Kl_15 1000;
BA_REL_ "GenSigTimeoutTime" BU_SG_REL_ SAK SG_ 960 ZAS_Kl_15 1000;
BA_REL_ "GenSigTimeoutTime" BU_SG_REL_ Getriebe_DL382_MLB SG_ 959 KL_Zustand 1000;
BA_REL_ "GenSigTimeoutTime" BU_SG_REL_ Getriebe_DL382_MLB SG_ 779 KBI_angez_Geschw 500;
BA_REL_ "GenSigTimeoutTime" BU_SG_REL_ Getriebe_DL382_MLB SG_ 1719 KBI_Standzeit 5000;
BA_REL_ "GenSigTimeoutTime" BU_SG_REL_ Getriebe_DL382_MLB SG_ 1719 KBI_Standzeit 5000;
BA_REL_ "GenSigTimeoutTime" BU_SG_REL_ Getriebe_DL382_MLB SG_ 1719 KBI_Reset_Standzeit 5000;
BA_REL_ "GenSigTimeoutTime" BU_SG_REL_ Getriebe_DL382_MLB SG_ 1719 KBI_Reset_Standzeit 5000;
BA_REL_ "GenSigTimeoutTime" BU_SG_REL_ Getriebe_DL382_MLB SG_ 1719 KBI_QBit_Aussen_Temp_gef 5000;
BA_REL_ "GenSigTimeoutTime" BU_SG_REL_ Getriebe_DL382_MLB SG_ 1719 KBI_Aussen_Temp_gef 5000;
BA_REL_ "GenSigTimeoutTime" BU_SG_REL_ Getriebe_DL382_MLB SG_ 1720 KBI_Reifenumfang 5000;
BA_REL_ "GenSigTimeoutTime" BU_SG_REL_ Getriebe_DL382_MLB SG_ 267 LS_01_CHK 1000;
BA_REL_ "GenSigTimeoutTime" BU_SG_REL_ Getriebe_DL382_MLB SG_ 267 LS_01_BZ 1000;
BA_REL_ "GenSigTimeoutTime" BU_SG_REL_ Getriebe_DL382_MLB SG_ 267 LS_Tip_Setzen 1000;
BA_REL_ "GenSigTimeoutTime" BU_SG_REL_ Getriebe_DL382_MLB SG_ 267 LS_Tip_Hoch 1000;
BA_REL_ "GenSigTimeoutTime" BU_SG_REL_ Getriebe_DL382_MLB SG_ 267 LS_Tip_Runter 1000;
BA_REL_ "GenSigTimeoutTime" BU_SG_REL_ Getriebe_DL382_MLB SG_ 267 LS_Tip_Wiederaufnahme 1000;
BA_REL_ "GenSigTimeoutTime" BU_SG_REL_ Getriebe_DL382_MLB SG_ 267 MFL_Tip_Down 1000;
BA_REL_ "GenSigTimeoutTime" BU_SG_REL_ Getriebe_DL382_MLB SG_ 267 MFL_Tip_Up 1000;
BA_REL_ "GenSigTimeoutTime" BU_SG_REL_ Getriebe_DL382_MLB SG_ 267 LS_Tiptronic_Fehler 1000;
BA_REL_ "GenSigTimeoutTime" BU_SG_REL_ ESP SG_ 134 LWI_01_CHK 100;
BA_REL_ "GenSigTimeoutTime" BU_SG_REL_ SCU SG_ 134 LWI_01_CHK 40;
BA_REL_ "GenSigTimeoutTime" BU_SG_REL_ ESP SG_ 134 LWI_01_BZ 100;
BA_REL_ "GenSigTimeoutTime" BU_SG_REL_ SCU SG_ 134 LWI_01_BZ 40;
BA_REL_ "GenSigTimeoutTime" BU_SG_REL_ ESP SG_ 134 LWI_Sensorstatus 100;
BA_REL_ "GenSigTimeoutTime" BU_SG_REL_ Gateway SG_ 134 LWI_Sensorstatus 500;
BA_REL_ "GenSigTimeoutTime" BU_SG_REL_ SCU SG_ 134 LWI_Sensorstatus 40;
BA_REL_ "GenSigTimeoutTime" BU_SG_REL_ ESP SG_ 134 LWI_QBit_Sub_Daten 100;
BA_REL_ "GenSigTimeoutTime" BU_SG_REL_ SCU SG_ 134 LWI_QBit_Sub_Daten 40;
BA_REL_ "GenSigTimeoutTime" BU_SG_REL_ ESP SG_ 134 LWI_QBit_Lenkradwinkel 100;
BA_REL_ "GenSigTimeoutTime" BU_SG_REL_ SCU SG_ 134 LWI_QBit_Lenkradwinkel 40;
BA_REL_ "GenSigTimeoutTime" BU_SG_REL_ ESP SG_ 134 LWI_Lenkradwinkel 100;
BA_REL_ "GenSigTimeoutTime" BU_SG_REL_ Getriebe_DL382_MLB SG_ 134 LWI_Lenkradwinkel 500;
BA_REL_ "GenSigTimeoutTime" BU_SG_REL_ SCU SG_ 134 LWI_Lenkradwinkel 40;
BA_REL_ "GenSigTimeoutTime" BU_SG_REL_ ESP SG_ 134 LWI_VZ_Lenkradwinkel 100;
BA_REL_ "GenSigTimeoutTime" BU_SG_REL_ Getriebe_DL382_MLB SG_ 134 LWI_VZ_Lenkradwinkel 500;
BA_REL_ "GenSigTimeoutTime" BU_SG_REL_ SCU SG_ 134 LWI_VZ_Lenkradwinkel 40;
BA_REL_ "GenSigTimeoutTime" BU_SG_REL_ ESP SG_ 134 LWI_Sub_Daten 100;
BA_REL_ "GenSigTimeoutTime" BU_SG_REL_ SCU SG_ 134 LWI_Sub_Daten 40;
BA_REL_ "GenSigTimeoutTime" BU_SG_REL_ ESP SG_ 134 LWI_01_CRC 100;
BA_REL_ "GenSigTimeoutTime" BU_SG_REL_ SCU SG_ 134 LWI_01_CRC 40;
BA_REL_ "GenSigTimeoutTime" BU_SG_REL_ Getriebe_DL382_MLB SG_ 128 Motor_01_CHK 500;
BA_REL_ "GenSigTimeoutTime" BU_SG_REL_ Getriebe_DL382_MLB SG_ 128 Motor_01_BZ 500;
BA_REL_ "GenSigTimeoutTime" BU_SG_REL_ Getriebe_DL382_MLB SG_ 128 MO_Mom_o_ex 500;
BA_REL_ "GenSigTimeoutTime" BU_SG_REL_ Getriebe_DL382_MLB SG_ 128 MO_Mom_m_ex 500;
BA_REL_ "GenSigTimeoutTime" BU_SG_REL_ SAK SG_ 128 MO_Mom_m_ex 500;
BA_REL_ "GenSigTimeoutTime" BU_SG_REL_ Getriebe_DL382_MLB SG_ 128 MO_Mom_Verlust 500;
BA_REL_ "GenSigTimeoutTime" BU_SG_REL_ SAK SG_ 128 MO_Mom_Verlust 500;
BA_REL_ "GenSigTimeoutTime" BU_SG_REL_ Getriebe_DL382_MLB SG_ 128 MO_Mom_Begrenzung 500;
BA_REL_ "GenSigTimeoutTime" BU_SG_REL_ Getriebe_DL382_MLB SG_ 128 MO_Mom_Fahrerwunsch 500;
BA_REL_ "GenSigTimeoutTime" BU_SG_REL_ Getriebe_DL382_MLB SG_ 128 MO_Kickdown 500;
BA_REL_ "GenSigTimeoutTime" BU_SG_REL_ Gateway SG_ 128 MO_KD_Fehler 500;
BA_REL_ "GenSigTimeoutTime" BU_SG_REL_ Getriebe_DL382_MLB SG_ 129 Motor_02_CHK 500;
BA_REL_ "GenSigTimeoutTime" BU_SG_REL_ Getriebe_DL382_MLB SG_ 129 Motor_02_BZ 500;
BA_REL_ "GenSigTimeoutTime" BU_SG_REL_ Getriebe_DL382_MLB SG_ 129 MO_Mom_ZWR 500;
BA_REL_ "GenSigTimeoutTime" BU_SG_REL_ Getriebe_DL382_MLB SG_ 129 MO_Mom_Soll 500;
BA_REL_ "GenSigTimeoutTime" BU_SG_REL_ Getriebe_DL382_MLB SG_ 129 MO_Mom_Ist 500;
BA_REL_ "GenSigTimeoutTime" BU_SG_REL_ Getriebe_DL382_MLB SG_ 129 MO_Status_Normalbetrieb_01 500;
BA_REL_ "GenSigTimeoutTime" BU_SG_REL_ Getriebe_DL382_MLB SG_ 129 MO_StartStopp_Status 500;
BA_REL_ "GenSigTimeoutTime" BU_SG_REL_ Getriebe_DL382_MLB SG_ 129 MO_StartStopp_Motorstopp 500;
BA_REL_ "GenSigTimeoutTime" BU_SG_REL_ Getriebe_DL382_MLB SG_ 129 MO_StartStopp_Wiederstart 500;
BA_REL_ "GenSigTimeoutTime" BU_SG_REL_ Getriebe_DL382_MLB SG_ 129 MO_StartStopp_StoppVorbereitung 500;
BA_REL_ "GenSigTimeoutTime" BU_SG_REL_ Getriebe_DL382_MLB SG_ 129 MO_Momentenintegral 500;
BA_REL_ "GenSigTimeoutTime" BU_SG_REL_ Getriebe_DL382_MLB SG_ 261 Motor_03_CHK 500;
BA_REL_ "GenSigTimeoutTime" BU_SG_REL_ Getriebe_DL382_MLB SG_ 261 Motor_03_CHK 500;
BA_REL_ "GenSigTimeoutTime" BU_SG_REL_ Getriebe_DL382_MLB SG_ 261 Motor_03_BZ 500;
BA_REL_ "GenSigTimeoutTime" BU_SG_REL_ Getriebe_DL382_MLB SG_ 261 Motor_03_BZ 500;
BA_REL_ "GenSigTimeoutTime" BU_SG_REL_ Getriebe_DL382_MLB SG_ 261 MO_QBit_Fahrpedalwerte_01 500;
BA_REL_ "GenSigTimeoutTime" BU_SG_REL_ Getriebe_DL382_MLB SG_ 261 MO_QBit_Motormomente 500;
BA_REL_ "GenSigTimeoutTime" BU_SG_REL_ Getriebe_DL382_MLB SG_ 261 MO_QBit_Fahrer_bremst 500;
BA_REL_ "GenSigTimeoutTime" BU_SG_REL_ Getriebe_DL382_MLB SG_ 261 MO_QBit_Drehzahl_01 500;
BA_REL_ "GenSigTimeoutTime" BU_SG_REL_ Getriebe_DL382_MLB SG_ 261 MO_Drehzahl_01 500;
BA_REL_ "GenSigTimeoutTime" BU_SG_REL_ SAK SG_ 261 MO_Drehzahl_01 500;
BA_REL_ "GenSigTimeoutTime" BU_SG_REL_ Getriebe_DL382_MLB SG_ 261 MO_BLS 500;
BA_REL_ "GenSigTimeoutTime" BU_SG_REL_ Getriebe_DL382_MLB SG_ 261 MO_Fahrer_bremst 500;
BA_REL_ "GenSigTimeoutTime" BU_SG_REL_ Getriebe_DL382_MLB SG_ 261 MO_Konsistenz_Bremsped 500;
BA_REL_ "GenSigTimeoutTime" BU_SG_REL_ Getriebe_DL382_MLB SG_ 261 MO_Solldrehz_Leerlauf 500;
BA_REL_ "GenSigTimeoutTime" BU_SG_REL_ Getriebe_DL382_MLB SG_ 261 MO_Fahrpedalrohwert_01 500;
BA_REL_ "GenSigTimeoutTime" BU_SG_REL_ Getriebe_DL382_MLB SG_ 261 MO_erste_Ungenauschwelle 500;
BA_REL_ "GenSigTimeoutTime" BU_SG_REL_ Getriebe_DL382_MLB SG_ 261 MO_QBit_Stressfaktor 500;
BA_REL_ "GenSigTimeoutTime" BU_SG_REL_ Getriebe_DL382_MLB SG_ 261 MO_Stressfaktor 500;
VAL_ 131 GE_Anf_Zylabsch 0 "Umschaltung_erlaubt" 1 "Umschaltung_verboten" 3 "VMB_Empfehlung" ;
VAL_ 131 GE_Synchro_Wunschdrehz 0 "Init_kein_Eingriff" 511 "Fehler" ;
VAL_ 131 GE_Synchro_Zeit 255 "Fehler" ;
VAL_ 131 GE_Mom_Begr_Gradient 255 "keine Begrenzung (Init)" ;
VAL_ 131 GE_Anheb_Solldrehz_Leerlauf 255 "Fehler" ;
VAL_ 131 GE_Vorsteuermoment 510 "Init" 511 "Fehler" ;
VAL_ 131 GE_Segeln_Aktiv 0 "Segeln_inaktiv" 1 "Segeln_aktiv" ;
VAL_ 131 GE_Drehzahlmesser_Daempfung 0 "normale Dämpfung" 1 "dynamische Dämpfung" ;
VAL_ 131 GE_Schubabschalt_Unt 0 "inaktiv" 1 "aktiv" ;
VAL_ 131 GE_Freigabe_Synchro 0 "inaktiv" 1 "aktiv" ;
VAL_ 131 GE_HYB_DZ_Eingriff 0 "kein_Drehzahleingriff" 1 "Slip_Start" 2 "Low_Speed_Modus" ;
VAL_ 258 GE_Freig_Langfr_Schutzmom 0 "nicht freigegeben" 1 "freigegeben" ;
VAL_ 258 GE_Uefkt 1023 "Fehler" ;
VAL_ 258 GE_Zielgang 0 "Gang P/N (ausgekuppelt)" 1 "Gang 1" 2 "Gang 2" 3 "Gang 3" 4 "Gang 4" 5 "Gang 5" 6 "Gang 6" 7 "Gang 7" 8 "Gang R" 11 "Gang 8" 12 "Gang 9" 14 "Istgang nicht definiert" 15 "Fehler" ;
VAL_ 258 GE_StartStopp_Info 0 "Motorlauf_nicht_notwendig_(Stoppfreigabe)" 1 "Motoranlauf_nicht_zwingend_notwendig_(Stoppverbot,keine_Startanforderung)" 2 "Motoranlauf_zwingend_notwendig_(Startanforderung)" 3 "Systemfehler" ;
VAL_ 258 GE_Langfr_Schutzmom 1022 "Init" 1023 "Fehler" ;
VAL_ 258 GE_Performance_Start_LB 0 "nicht_aktiv" 1 "aktiv" ;
VAL_ 258 GE_Waehlhebel 0 "Zwischenstellung" 1 "Init" 5 "Position_P" 6 "Position_R" 7 "Position_N" 8 "Position_D" 9 "Position_S" 10 "Effizienz" 11 "Position_S_Plus" 12 "Tipp_in_S_Plus" 13 "Tipp_in_S" 14 "Tipp_in_D" 15 "Fehler" ;
VAL_ 258 GE_Eingangsdrehz 16382 "Init" 16383 "Fehler" ;
VAL_ 258 GE_Notlauf 0 "kein Notlauf / Init" 1 "Getriebe im Notlauf" ;
VAL_ 258 GE_Codierung_MSG 0 "Codierung iO / Init" 1 "Codierung niO" ;
VAL_ 1089 GE_Index_Fahrwid 255 "Fehler" ;
VAL_ 1089 GE_Heizwunsch 0 "maximaler_Waermebedarf" 1 "kein_Waermebedarf" 2 "Kuehlbedarf" 3 "Notfall_(maximaler_Kuehlbedarf)" ;
VAL_ 1089 GE_OBD_Status 0 "MIL aus" 1 "MIL ein" ;
VAL_ 1089 GE_LFR_Adaption 0 "fuer_Adaption_geeignet" 1 "fuer_Adaption_nicht_geeignet" ;
VAL_ 1089 GE_OBD_AbsperrVent 0 "kein Fehler / Init / nicht verbaut" 1 "KS- (Kurzschluss nach minus)" 2 "KS+ (Kurzschluss nach plus)" 3 "OC (Leitungsunterbrechung)" 4 "OOR+ (Signal zu gross)" 5 "OOR- (Signal zu klein)" 6 "RC+ (Signal unplausibel zu gross)" 7 "RC- (Signal unplausibel zu klein)" 8 "KS+/OC (Kurzschluss nach plus/Unterbrechung)" 9 "KS-/OC  (Kurzschluss nach minus/Unterbrechung)" 10 "KS-/KS+  (Kurzschluss nach minus/plus)" 11 "KS-/KS+/OC (Kurzschluss nach minus/plus/Unterbrechung)" 12 "frei" 13 "frei" 14 "frei" 15 "frei" ;
VAL_ 1089 GE_Grenzkriechmoment 62 "Init" 63 "Fehler" ;
VAL_ 1089 GE_Charisma_FahrPr 0 "nicht_belegt" 1 "Programm_1" 2 "Programm_2" 3 "Programm_3" 4 "Programm_4" 5 "Programm_5" 6 "Programm_6" 7 "Programm_7" ;
VAL_ 1089 GE_Charisma_Status 0 "Init" 1 "verfuegbar" 2 "nicht_verfuegbar" 3 "asynchron_durch_Fahrerwunsch" ;
VAL_ 1089 GE_Charisma_Umschaltung 0 "Idle" 1 "Erkennung_Umschaltaufforderung" 2 "Steuerbotschaft_nicht_definiert" 3 "Umschaltung_verzoegert" ;
VAL_ 1089 GE_Freigabe_Verfallsinfo_WFS 0 "Aus" 1 "Ein" ;
VAL_ 1089 GE_Verlustmoment 255 "Fehler" ;
VAL_ 1089 GE_LaunchControl 0 "inaktiv" 1 "aktiv" ;
VAL_ 1089 GE_amax_moeglich 511 "nicht_definiert" ;
VAL_ 1089 GE_Sumpftemperatur 255 "Fehler" ;
VAL_ 1340 HVLM_IstModus_02 0 "inaktiv" 1 "aktiv" 2 "Init" 3 "Fehler" ;
VAL_ 1340 HVLM_HV_Anf 0 "keine_Anforderung" 1 "Laden_angefordert" 2 "Batteriekonditionierung_angefordert" 3 "Standklimatisierung_angefordert" ;
VAL_ 1340 HVLM_Fehlerstatus 0 "Komponente_IO" 1 "Eingeschr_KompFkt_DC_Lad_NIO" 2 "Eingeschr_KompFkt_AC_Lad_NIO" 3 "Eingeschr_KompFkt_Interlock" 4 "Eingeschr_KompFkt_reserve" 5 "Eingeschr_KompFkt_reserve" 6 "Keine_Komponentenfunktion" 7 "Init" ;
VAL_ 1340 HVLM_Anforderung_HMS 0 "keine_Anforderung" 1 "halten" 2 "parken" 3 "halten_Standby" 4 "anfahren" 5 "Loesen_ueber_Rampe" ;
VAL_ 1340 HVLM_Parken_beibehalten_HMS 0 "Parken_nicht_beibehalten" 1 "Parken_beibehalten" 2 "Init" 3 "Fehler" ;
VAL_ 1340 HVLM_Dauer_Klima 31 "Fehler" ;
VAL_ 1340 HVLM_Stecker_Status 0 "Init" 1 "kein_Stecker_gesteckt" 2 "Stecker_erkannt_nicht_verriegelt" 3 "Stecker_erkannt_und_verriegelt" ;
VAL_ 1340 HVLM_LadeAnforderung 0 "keine_Anforderung" 1 "AC_Laden" 2 "DC_Laden" 3 "Nachladen_12V" 4 "Reserve" 5 "Reserve" 6 "Init" 7 "Fehler" ;
VAL_ 1340 HVLM_MaxBatLadestromHV 254 "Init" 255 "Fehler" ;
VAL_ 1424 KY_Funkschl_Nr 0 "kein authorisierter Schluessel erkannt" 1 "aktive_Funkschluessel_Nr_01" 2 "aktive_Funkschluessel_Nr_02" 3 "aktive_Funkschluessel_Nr_03" 4 "aktive_Funkschluessel_Nr_04" 5 "aktive_Funkschluessel_Nr_05" 6 "aktive_Funkschluessel_Nr_06" 7 "aktive_Funkschluessel_Nr_07" 8 "aktive_Funkschluessel_Nr_08" 9 "ungueltig_09" 10 "ungueltig_10" 11 "ungueltig_11" 12 "ungueltig_12" 13 "ungueltig_13" 14 "ungueltig_14" 15 "ungueltig_15" ;
VAL_ 1424 KY_ID_Geb_autorisiert 0 "Schluessel_nicht_authorisiert" 1 "Schluessel authorisiert" ;
VAL_ 1424 KY_ID_Geb_steckt 0 "kein_Schluessel_im_Zuendschloss" 1 " Schluessel steckt im Zuendschloss" ;
VAL_ 1424 KY_FFB_Frequenz 1 "433 MHz" 2 "315 MHz" 3 "868 MHz" ;
VAL_ 1424 KY_HF_Aktiv 0 "Funktempfang_nicht_aktiv" 1 "HF_Funkempfang_aktiv" ;
VAL_ 1424 KY_LF_Aktiv 0 "Funktempfang_nicht_aktiv" 1 "LF_Funkempfang_aktiv" ;
VAL_ 1424 KY_ELV_verr 0 "ELV_nicht_verriegelt" 1 "ELV verriegelt" ;
VAL_ 1424 KY_ELV_entr 0 "ELV_nicht_entriegelt" 1 "ELV entriegelt" ;
VAL_ 1424 KY_ELV_enable_Anforderung 0 "Freigabe_nicht_angefordert" 1 "Freigabe ELV wird angefordert" ;
VAL_ 1424 KY_Valet_Parking 0 "kein_Valet_Schluessel_erkannt" 1 "Valet Schluessel erkannt" ;
VAL_ 1424 KY_Keyless_Verbau 0 "nicht_verbaut" 1 "verbaut" ;
VAL_ 1424 FBS_Warn_Lenkung_def 0 "iO" 1 "defekt" ;
VAL_ 1424 FBS_Warn_LenkVerriegelung_def 0 "i.O." 1 "defekt" ;
VAL_ 1424 FBS_Warn_Schluessel_Batt 0 "i.O." 1 "defekt" ;
VAL_ 1424 FBS_Prio_Warn_04 1 "Kombi Prio Warnung FBS 4" ;
VAL_ 1424 FBS_Prio_Warn_05 1 "Kombi Prio Warnung FBS 5" ;
VAL_ 1424 KYL_Warn_kein_Schluessel 1 "kein Schluessel erkannt" ;
VAL_ 1424 KYL_Warn_Kessy_defekt 0 "Kessy_i.O." 1 "Kessy defekt" ;
VAL_ 1424 KY_KYL_Prio_Warn_03 1 "Kombi Prio Warnung Keyless 3" ;
VAL_ 1424 KY_KYL_Prio_Warn_04 1 "Kombi Prio Warnung Keyless 4" ;
VAL_ 1424 KY_KYL_Prio_Warn_05 1 "Kombi Prio Warnung Keyless 5" ;
VAL_ 1424 KY_WFS_Safe 1 "WFS nicht deaktiviert" ;
VAL_ 1424 KY_WFS_LZ 0 "nicht def." 1 "LZ 1" 2 "LZ 2" 3 "LZ 3" ;
VAL_ 1424 KY_StartStopp_Info 0 "Motorlauf_nicht_notwendig_(Stoppfreigabe)" 1 "Motoranlauf_nicht_zwingend_notwendig_(Stoppverbot,keine_Startanforderung)" 2 "Motoranlauf_zwingend_notwendig_(Startanforderung)" 3 "Systemfehler" ;
VAL_ 1424 KYL_Notzuendschloss 0 "nicht_verbaut" 1 "verbaut" ;
VAL_ 1424 KYL_Warn_Notzuendschloss 0 "Aus" 1 "Ein" ;
VAL_ 1424 FBS_KD_Fehler 0 "kein_KD_Fehler" 1 "KD_Fehler" ;
VAL_ 1424 SK_Anf_DTC_Abfrage 1 "DTC_Abfrage" ;
VAL_ 1424 SK_Anf_DTC_Abfrage_sofort 1 "DTC_Abfrage_sofort" ;
VAL_ 960 ZV_verriegelt_extern_soll_02 1 "Fahrzeug verriegelt extern; Sollzusstand" ;
VAL_ 960 ZAS_Kl_S 0 "aus" 1 "S_Kontakt_ein" ;
VAL_ 960 ZAS_Kl_15 0 "aus" 1 "ein" ;
VAL_ 960 ZAS_Kl_X 0 "aus" 1 "ein" ;
VAL_ 960 ZAS_Kl_50 0 "aus" 1 "KL50_ein_Startwunsch_Fahrer" ;
VAL_ 960 ZAS_Kl_Infotainment 0 "inaktiv" 1 "aktiv" ;
VAL_ 959 KL_Drehz_Anh 0 "keine_Anhebung" 1 "Drehzahlanhebung_vom_Motor_angefordert" ;
VAL_ 959 KL_Vorwarn_Komp_ein 0 "Init" 1 "Vorwarnung_Kompressor_ein" ;
VAL_ 959 KL_Handshake_BEM 0 "keine_Leistungsaenderung_in_den_Heizsystemen_aktiv" 1 "Heizleistungsaenderung_wird_gerade_durchgefuehrt" ;
VAL_ 959 KL_Komp_Moment_alt 1 "veraltet_bzw_Ermittlung_des_Moments_nicht_moeglich__zB_keine_Drehzahl_kein_Kaeltemitteldruck" ;
VAL_ 959 KL_Vorwarn_HHS_ein 1 "Vorwarnung_Heckscheibenheizung_ein" ;
VAL_ 959 KL_Vorwarn_HFS_ein 1 "Vorwarnung_Frontscheibenheizung_ein" ;
VAL_ 959 KL_Vorwarn_Zuheizer_ein 0 "keine_Vorwarnung" 1 "Vorwarnung_Zuheizer_ein" ;
VAL_ 959 KL_KD_Fehler 0 "kein_KD_Fehler" 1 "KD_Fehler" ;
VAL_ 959 KL_Comp_rev_rq 255 "Fehler" ;
VAL_ 959 KL_Charisma_FahrPr 0 "nicht_belegt" 1 "Programm_1" 2 "Programm_2" 3 "Programm_3" 4 "Programm_4" 5 "Programm_5" 6 "Programm_6" 7 "Programm_7" ;
VAL_ 959 KL_Charisma_Status 0 "Init" 1 "verfuegbar" 2 "nicht_verfuegbar" 3 "asynchron_durch_Fahrerwunsch" ;
VAL_ 959 KL_Charisma_Umschaltung 0 "Idle" 1 "Erkennung_Umschaltaufforderung" 2 "Steuerbotschaft_nicht_definiert" 3 "Umschaltung_verzoegert" ;
VAL_ 959 KL_Last_Kompr 255 "Fehler" ;
VAL_ 959 KL_Anf_KL 255 "Fehler" ;
VAL_ 959 KL_4_Zonen 0 "2_Zonen_Klimaanlage" 1 "4_Zonen_Klimaanlage" ;
VAL_ 959 KL_AC_Schalter 0 "aus" 1 "ein" ;
VAL_ 959 KL_Zustand 0 "aus" 1 "ein" ;
VAL_ 959 KL_Thermomanagement 0 "keine_Freigabe_TMM__max_Heizbedarf" 1 "kleine_Freigabe_TMM" 2 "mittlere_Freigabe_TMM" 3 "volle_Freigabe_TMM__kein_Heizbedarf" ;
VAL_ 959 KL_Comp_enable 0 "Disable" 1 "Enable" ;
VAL_ 959 KL_StartStopp_Info 0 "Motorlauf_nicht_notwendig_(Stoppfreigabe)" 1 "Motoranlauf_nicht_zwingend_notwendig_(Stoppverbot,keine_Startanforderung)" 2 "Motoranlauf_zwingend_notwendig_(Startanforderung)" 3 "Systemfehler" ;
VAL_ 959 KL_el_Zuheizer_Stufe 0 "Aus" 1 "Stufe_1" 2 "Stufe_2" 3 "Stufe_3" ;
VAL_ 959 KL_Diag_Absperrvent 0 "kein_Fehler" 1 "KS-" 2 "KS+" 3 "OC" 4 "OOR+" 5 "OOR-" 6 "RC+" 7 "RC-" 8 "KS+/OC" 9 "KS-/OC" 10 "KS-/KS+" 11 "KS-/KS+/OC" ;
VAL_ 959 KL_nachtr_Stopp_Anf 0 "nicht_angefordert" 1 "angefordert" ;
VAL_ 1636 KL_Stromsparmodus 0 "keine_Funktionsbeeintraechtigung_durch_BEM" 1 "Abschaltung_durch_BEM" ;
VAL_ 1636 KL_Spg_Hzg_aus 1 "Spiegelheizung_ausschalten" ;
VAL_ 1636 KL_AQS_Empfindlichkeit 0 "max__Empfindlichkeit" 1 "Empfindlichkeit" 2 "Standard_Empfindlichkeit" 3 "Unempfindlichkeit" 4 "max__Unempfindlichkeit" ;
VAL_ 1636 KL_SIH_Takt_li 0 "Aus" 1 "Ein" ;
VAL_ 1636 KL_LRH_aus 0 "Funktion_LRH_erlaubt" 1 "Funktion_LRH_nicht_erlaubt" ;
VAL_ 1636 KL_SIH_Takt_re 0 "Aus" 1 "Ein" ;
VAL_ 1636 KL_Beschlagsgefahr 0 "keine_Beschlagsgefahr" 1 "Beschlagsgefahr" ;
VAL_ 1636 KL_HSH_ein_Soll 0 "Fahrerwunsch_HSH_aus" 1 "Fahrerwunsch_HSH_ein" ;
VAL_ 1636 KL_HSH_Taktung 0 "Aus" 1 "Ein" ;
VAL_ 1636 KL_Zuheizer_Freigabe 0 "keine_Freigabe_Zuheizer" 1 "Zuheizerfreigabe" ;
VAL_ 1636 KL_ZHE_Status 0 "aus" 1 "eingeschaltet" ;
VAL_ 1636 KL_FSH_Status 0 "aus" 1 "ein" 2 "tbd" 3 "Fehler" ;
VAL_ 1636 KL_LRH_on_off 0 "Aus" 1 "Ein" ;
VAL_ 1636 KL_Umluftklappe_Status 0 "Frischluft" 1 "Teilumluft_10" 2 "Teilumluft_20" 3 "Teilumluft_30" 4 "Teilumluft_40" 5 "Teilumluft_50" 6 "Teilumluft_60" 7 "Teilumluft_70" 8 "Teilumluft_80" 9 "Teilumluft_90" 10 "Umluft" 15 "Fehler" ;
VAL_ 1636 KL_Geblaese_Status 0 "Geblaese_aus" 1 "Geblaesestufe_10" 2 "Geblaesestufe_20" 3 "Geblaesestufe_30" 4 "Geblaesestufe_40" 5 "Geblaesestufe_50" 6 "Geblaesestufe_60" 7 "Geblaesestufe_70" 8 "Geblaesestufe_80" 9 "Geblaesestufe_90" 10 "Geblaesestufe_100" 14 "Init" 15 "Fehler" ;
VAL_ 1636 KL_I_Geblaese 255 "Fehler" ;
VAL_ 1636 KL_Kompressorstrom_soll 1023 "Fehler" ;
VAL_ 1636 KL_FSH_P_Soll 63 "Fehler" ;
VAL_ 1646 KL_STL_aktiv 0 "Standlueftung_nicht_aktiv" 1 "Standlueftung_aktiv" ;
VAL_ 1646 KL_STH_aktiv 0 "Standheizung_nicht_aktiv" 1 "Standheizung_aktiv" ;
VAL_ 1646 KL_Solarluefter_aktiv 0 "Solarluefter_nicht_aktiv" 1 "Solarluefter_aktiv__auto" ;
VAL_ 1646 KL_Umluft_Taste 0 "Taste_nicht_gedrueckt" 1 "Taste_gedrueckt" ;
VAL_ 1646 KL_Geblaese_Fond_Status 0 "Geblaese_aus" 1 "Geblaesestufe_10" 2 "Geblaesestufe_20" 3 "Geblaesestufe_30" 4 "Geblaesestufe_40" 5 "Geblaesestufe_50" 6 "Geblaesestufe_60" 7 "Geblaesestufe_70" 8 "Geblaesestufe_80" 9 "Geblaesestufe_90" 10 "Geblaesestufe_100" 14 "Init" 15 "Fehler" ;
VAL_ 1646 KL_STH_Ansteuerung 0 "Aus" 1 "Ein" 2 "Ein_mit_Motorvorwaermung" 3 "Heizleistung_reduziert" ;
VAL_ 1646 KL_Magnetventil 0 "Aus" 1 "Ein" ;
VAL_ 1646 KL_WaPu 0 "Wasserpumpe_aus" 1 "Wasserpumpe_aktiv" ;
VAL_ 1646 KL_Freigabe_KRH_li 0 "aus" 1 "Stufe_1" 2 "Stufe_2" 3 "Stufe_3" 7 "nicht_verfuegbar" ;
VAL_ 1646 KL_Freigabe_KRH_re 0 "aus" 1 "Stufe_1" 2 "Stufe_2" 3 "Stufe_3" 7 "nicht_verfuegbar" ;
VAL_ 1646 KL_BCmE_Livetip_Freigabe 0 "Anzeige_Livetip_nicht_zulaessig" 1 "Anzeige_Livetip_zulaessig" ;
VAL_ 1646 KL_HYB_ASV_hinten_schliessen_Anf 0 "keine_Anforderung" 1 "Ventil_schliessen" ;
VAL_ 1646 KL_HYB_ASV_vorne_schliessen_Anf 0 "keine_Anforderung" 1 "Ventil_schliessen" ;
VAL_ 1646 KL_HYB_Spuelbetrieb_Freigabe 0 "kein_Spuelbetrieb" 1 "Spuelbetrieb_moeglich" ;
VAL_ 1646 KL_Fehler_ElWaPu 0 "kein_Fehler" 1 "Fehler" ;
VAL_ 1646 KL_Innen_Temp 253 "nicht_verbaut" 254 "nicht_verfuegbar" 255 "Fehler" ;
VAL_ 1646 KL_AussenTemp_WK 253 "nicht_verbaut" 254 "Init_Wert__nicht_verfuegbar" 255 "Fehler" ;
VAL_ 1625 EKL_KD_Fehler 0 "kein_KD_Fehler" 1 "KD_Fehler" ;
VAL_ 1625 EKL_Comp_SCI_com_stat 0 "normal" 1 "CAN_error" 2 "Inverter_error" 3 "CAN_and_Inverter_error" ;
VAL_ 1625 EKL_Comp_output_stat 0 "normal" 1 "output_line_short" 2 "output_line_cut_out" 3 "abnormal_current_detection" ;
VAL_ 1625 EKL_Comp_main_stat 0 "Comp_not_enabled" 1 "Comp_enabled" ;
VAL_ 1625 EKL_Comp_ovld_stat 0 "normal" 1 "voltage_restriction" 2 "current_restriction" 3 "software_over_current" 4 "over_load" 6 "over_input_current" ;
VAL_ 1625 EKL_Comp_Inv_stat 0 "normal" 1 "start_fail" 2 "temperature_protection" 3 "system_abnormal_stop" ;
VAL_ 1625 EKL_Comp_photo_temp_stat 0 "normal" 1 "over_heat_L" 2 "over_heat_S" 3 "sermister_abnormal" ;
VAL_ 1625 EKL_Comp_photo_temp 255 "Fehler" ;
VAL_ 1625 EKL_Comp_current 255 "Init_not_avail" ;
VAL_ 1625 EKL_Comp_rev_stat 255 "Fehler" ;
VAL_ 779 KBI_ABS_Lampe 0 "ABS Lampe aus" 1 "ABS Lampe ein" ;
VAL_ 779 KBI_ESP_Lampe 0 "ESP Lampe aus" 1 "ESP Lampe ein" ;
VAL_ 779 KBI_BKL_Lampe 0 "BKL aus" 1 "BKL ein" ;
VAL_ 779 KBI_Airbag_Lampe 0 "Airbag Lampe aus" 1 "Airbag Lampe ein" ;
VAL_ 779 KBI_SILA_gueltig 0 "ungueltig" 1 "gueltig" ;
VAL_ 779 KBI_Vorglueh_System_Lampe 0 "Lampe aus" 1 "Lampe ein" ;
VAL_ 779 KBI_NV_in_Anzeige 0 "NV_nicht_in_Anzeige" 1 "NV_in_Anzeige" ;
VAL_ 779 KBI_Anzeigestatus_ACC 0 "keine_ACC_Anzeige" 1 "ACC_Anzeige_aktiv" ;
VAL_ 779 KBI_Oeldruck_Schalter 0 "offen____p_kleiner_pnenn" 1 "geschlossen____p_groessergleich_pnenn" ;
VAL_ 779 KBI_Tankwarnung 0 "Lampe aus" 1 "Lampe ein" ;
VAL_ 779 KBI_MFA_v_Einheit_01 0 "kmh" 1 "mph" ;
VAL_ 779 KBI_im_Stellgliedtest 0 "kein Stellgliedtest" 1 "Kombi im Stellgliedtest" ;
VAL_ 779 KBI_Anzeigefehler_LDW 0 "nicht vorhanden bzw. unterstützt" 1 "Anzeige iO" 2 "Anzeigefehler" 3 "nicht definiert" ;
VAL_ 779 KBI_Variante_USA 0 "keine USA-Variante" 1 "USA-Variante" ;
VAL_ 779 KBI_Oeldruckwarnung 0 "inaktiv" 1 "aktiv" ;
VAL_ 779 KBI_Handbremse 0 "nicht_angezogen" 1 "angezogen" ;
VAL_ 779 KBI_PLA_in_Anzeige 0 "PLA_nicht_in_Anzeige" 1 "PLA_in_Anzeige" ;
VAL_ 779 KBI_Anzeigefehler_NV 0 "kein_Anzeigefehler" 1 "Anzeigefehler" ;
VAL_ 779 KBI_Einheit_Tacho 0 "km/h" 1 "mph" ;
VAL_ 779 KBI_Konsistenz_ACC 0 "ACC Botschaft konsistent" 1 "ACC Botschaft inkonsistent    " ;
VAL_ 779 KBI_Fehler_Anzeige_ACC 0 " iO" 1 "Anzeigefehler ACC" ;
VAL_ 779 KBI_Anzeigefehler_SWA 0 "nicht vorhanden bzw. unterstützt" 1 "Anzeige iO" 2 "Anzeigefehler" 3 "nicht definiert" ;
VAL_ 779 KBI_KD_Fehler 0 "kein_KD_Fehler" 1 "KD_Fehler" ;
VAL_ 1719 KBI_Kilometerstand 1048574 "Init" 1048575 "Fehler" ;
VAL_ 1719 KBI_Reset_Standzeit 0 "Standzeit iO" 1 "KL30 war weg" ;
VAL_ 1719 KBI_Inhalt_Tank 127 "Fehler" ;
VAL_ 1719 KBI_FStatus_Tank 0 "Tankfüllstand i.O." 1 "Tankfüllstand n.i.O" ;
VAL_ 1719 KBI_Oelwechsel_durchgefuehrt 0 "Oelwechsel_nicht_durchgefuehrt" 1 "Oelwechsel_durchgefuehrt" ;
VAL_ 1719 KBI_QBit_Aussen_Temp_gef 0 "gueltiger_Wert" 1 "Ersatz_Init_oder_Fehlerwert" ;
VAL_ 1719 KBI_Aussen_Temp_gef 253 "nicht verbaut" 254 "Init" 255 "Fehler" ;
VAL_ 1720 KBI_BCmE_aktiv 0 "Anzeige_nicht_aktiv" 1 "Anzeige_aktiv" ;
VAL_ 1720 KBI_Sparhinweis_quittiert 0 "nicht_quittiert" 1 "quittiert" ;
VAL_ 1720 KBI_Tankfuellstand_Prozent 127 "Fehler" ;
VAL_ 285 EPS_Notlauf 0 "kein_Notlauf" 1 "Notlauf_Unterspannung" 2 "Notlauf_Ueberspannung" 3 "reserviert" 4 "Notlauf_Uebertemperatur" 5 "Notlauf_Unterspannung_und_Uebertemperatur" 6 "Notlauf_Ueberspannung_und_Uebertemperatur" 7 "reserviert" 8 "reserviert" 9 "reserviert" 10 "reserviert" 11 "reserviert" 12 "reserviert" 13 "reserviert" 14 "reserviert" 15 "reserviert" ;
VAL_ 285 EPS_Lastinfo 255 "Fehler" ;
VAL_ 285 EPS_Unterstuetzungsleistung 255 "Fehler" ;
VAL_ 285 EPS_Drehzahlreserve 127 "Fehler" ;
VAL_ 285 EPS_VZ_Drehzahlreserve 0 "positiv" 1 "negativ" ;
VAL_ 285 EPS_Leistungsanforderung 0 "keine_Anforderung" 1 "Anforderung_hoehere_Spannung_oder_Leistung" ;
VAL_ 285 EPS_StartStopp_Info 0 "Motorlauf_nicht_notwendig_(Stoppfreigabe)" 1 "Motoranlauf_nicht_zwingend_notwendig_(Stoppverbot,keine_Startanforderung)" 2 "Motoranlauf_zwingend_notwendig_(Startanforderung)" 3 "Systemfehler" ;
VAL_ 285 EPS_Motorstartverzoegerung 0 "Motoranlauf_Freigabe" 1 "Motoranlauf_verzoegern" 3 "Systemfehler" ;
VAL_ 1137 BCM2_Bremsl_durch_ECD 0 "Bremslicht_ist_aus" 1 "Bremslicht_durch_ECD_aktiv" ;
VAL_ 1137 LH_Aussenlicht_def 0 "OK" 1 "defekt" ;
VAL_ 1137 LH_Standlicht_H_aktiv 1 "Standlicht hinten aktiv" ;
VAL_ 1137 LH_Parklicht_HL_aktiv 0 "nicht aktiv" 1 "Parklicht hinten links aktiv" ;
VAL_ 1137 LH_Parklicht_HR_aktiv 0 "nicht aktiv" 1 "Parklicht hinten rechts aktiv" ;
VAL_ 1137 LH_Bremslicht_H_aktiv 1 "Bremslicht hinten aktiv" ;
VAL_ 1137 LH_Nebelschluss_aktiv 0 "nicht aktiv" 1 "aktiv" ;
VAL_ 1137 LH_Rueckfahrlicht_aktiv 0 "nicht aktiv" 1 "aktiv" ;
VAL_ 1137 LH_Blinker_HL_akt 1 "Blinker hinten links aktiv" ;
VAL_ 1137 LH_Blinker_HR_akt 1 "Blinker hinten rechts aktiv" ;
VAL_ 1137 LH_Blinker_li_def 0 "OK" 1 "Blinker hinten links defekt" ;
VAL_ 1137 LH_Bremsl_li_def 0 "OK" 1 "mindestens ein Bremslicht hinten links defekt" ;
VAL_ 1137 LH_Schlusslicht_li_def 0 "OK" 1 "mindestens ein Schlusslicht hinten links defekt" ;
VAL_ 1137 LH_Rueckf_li_def 0 "OK" 1 "Rückfahrlicht hinten links defekt" ;
VAL_ 1137 LH_Nebel_li_def 0 "OK" 1 " Nebelschlusslicht hinten links defekt" ;
VAL_ 1137 LH_Schluss_Brems_Nebel_li_def 0 "iO" 1 "defekt" ;
VAL_ 1137 LH_Schluss_Brems_Nebel_re_def 0 "iO" 1 "defekt" ;
VAL_ 1137 LH_Schluss_Brems_li_def 0 "OK" 1 "defekt" ;
VAL_ 1137 LH_Schluss_Nebel_li_def 0 "OK" 1 "defekt" ;
VAL_ 1137 LH_SL_BRL_BLK_li_def 0 "OK" 1 "defekt" ;
VAL_ 1137 LH_Brems_Blk_li_def 0 "OK" 1 "defekt" ;
VAL_ 1137 LH_Blinker_re_def 0 "OK" 1 "Blinker hinten rechts defekt" ;
VAL_ 1137 LH_Bremsl_re_def 0 "OK" 1 "mindestens ein Bremslicht hinten rechts defekt" ;
VAL_ 1137 LH_Schlusslicht_re_def 0 "OK" 1 "mindestens ein Schlusslicht hinten rechts defekt" ;
VAL_ 1137 LH_Rueckf_re_def 0 "OK" 1 "Rückfahrlicht hinten rechts defekt" ;
VAL_ 1137 LH_Nebel_re_def 0 "OK" 1 "Nebelschlusslicht hinten rechts defekt" ;
VAL_ 1137 LH_Schluss_Brems_re_def 0 "OK" 1 "defekt" ;
VAL_ 1137 LH_Schluss_Nebel_re_def 0 "OK" 1 "defekt" ;
VAL_ 1137 LH_SL_BRL_BLK_re_def 0 "OK" 1 "defekt" ;
VAL_ 1137 LH_Brems_Blk_re_def 0 "OK" 1 "defekt" ;
VAL_ 1137 LH_Kennzl_def 0 "OK" 1 "Kennzeichenbeleuchtung hinten defekt" ;
VAL_ 1137 LH_3_Bremsl_def 0 "OK" 1 "hochgesetzte  Bremsleuchte defekt" ;
VAL_ 1137 LH_Nebel_mi_def 0 "OK" 1 " Nebelschlusslicht hinten Mitte defekt" ;
VAL_ 1137 LH_Rueckf_mi_def 0 "OK" 1 "Rückfahllicht Mitte defekt" ;
VAL_ 1137 LH_Bremsl_li_ges_def 0 "OK" 1 "Alle Bremslichter hinten links defekt" ;
VAL_ 1137 LH_Bremsl_re_ges_def 0 "OK" 1 "Alle Bremslichter hinten rechts defekt" ;
VAL_ 267 LS_Hauptschalter 0 "Gerastet Aus" 1 "Ein" ;
VAL_ 267 LS_Abbrechen 0 "Tippschalter nicht betaetigt" 1 "Tippschalter betaetigt" ;
VAL_ 267 LS_Typ_Hauptschalter 0 "gerasteter_Lenkstockschalter" 1 "getasteter_Lenkstockschalter" ;
VAL_ 267 LS_Limiter 0 "Limiter aus" 1 "Limiter ein" ;
VAL_ 267 LS_Tip_Setzen 0 "Tippschalter nicht betaetigt" 1 "Tippschalter betaetigt" ;
VAL_ 267 LS_Tip_Hoch 0 "Tippschalter nicht betaetigt" 1 "Tippschalter betaetigt" ;
VAL_ 267 LS_Tip_Runter 0 "Tippschalter nicht betaetigt" 1 "Tippschalter betaetigt" ;
VAL_ 267 LS_Tip_Wiederaufnahme 0 "Tippschalter nicht betaetigt" 1 "Tippschalter betaetigt" ;
VAL_ 267 LS_Verstellung_Zeitluecke 0 "Taste nicht betaetigt" 1 "Dist -1" 2 "Dist +1" 3 "nicht belegt" ;
VAL_ 267 MFL_Tip_Down 0 "nicht_betaetigt" 1 "betaetigt" ;
VAL_ 267 MFL_Tip_Up 0 "nicht_betaetigt" 1 "betaetigt" ;
VAL_ 267 LS_Tiptronic_Fehler 0 " i. O." 1 "Fehler erkannt" ;
VAL_ 267 LS_Codierung 0 "kein Hebel, keine Tiptronic am Lenkrad" 1 "kein Hebel, Tiptronic am Lenkrad" 2 "GRA Hebel, keine Tiptronic am Lenkrad" 3 "GRA Hebel, Tiptronic am Lenkrad" 4 "ACC Hebel, keine Tiptronic am Lenkrad" 5 "ACC Hebel, Tiptronic am Lenkrad" 6 "nicht verwendet" 7 "nicht verwendet" ;
VAL_ 267 LS_Tip_Stufe_2 0 "Hebelbetaetigung_in_erster_Tipstufe__Keine_Hebelbetaetigung" 1 "Hebelbetaetigung_in_der_zweiten_Tipstufe" ;
VAL_ 267 LS_GRA_ACC_2stufig 0 "kein_zweistufiger_Hebel_verbaut" 1 "zweistufiger_Hebel_verbaut" ;
VAL_ 267 MFL_M_Taste 0 "nicht_betaetigt" 1 "betaetigt" ;
VAL_ 134 LWI_Sensorstatus 0 "iO" 1 "nicht kalibriert" ;
VAL_ 134 LWI_QBit_Sub_Daten 0 "LWS-Subinfo 'real' (Lenkradwinkelinformation ADS-tauglich) " 1 "LWS-Subinfo 'simuliert' (Lenkradwinkelinformation nicht ADS-tauglich )" ;
VAL_ 134 LWI_QBit_Lenkradwinkel 0 "gültiger Wert" 1 "ausserhalb der Spezifikation" ;
VAL_ 134 LWI_Lenkradwinkel 8190 "Init" 8191 "Fehler" ;
VAL_ 134 LWI_VZ_Lenkradwinkel 0 "positiv_links_von_der_Nullstellung" 1 "negativ" ;
VAL_ 134 LWI_VZ_Lenkradw_Geschw 0 "positiv_links_von_der_Nullstellung" 1 "negativ" ;
VAL_ 134 LWI_Lenkradw_Geschw 510 "Init" 511 "Fehler" ;
VAL_ 128 MO_Mom_o_ex 1022 "Init" 1023 "Fehler" ;
VAL_ 128 MO_Mom_m_ex 1022 "Init" 1023 "Fehler" ;
VAL_ 128 MO_Mom_Verlust 1022 "Init" 1023 "Fehler" ;
VAL_ 128 MO_Mom_Begrenzung 1022 "Init" 1023 "Fehler" ;
VAL_ 128 MO_Mom_Fahrerwunsch 1022 "Init" 1023 "Fehler" ;
VAL_ 128 MO_Kickdown 0 "kein_Kickdown" 1 "Kickdown" ;
VAL_ 128 MO_KD_Fehler 0 "kein_KD_Fehler" 1 "KD_Fehler" ;
VAL_ 129 MO_Mom_ZWR 1022 "Init" 1023 "Fehler" ;
VAL_ 129 MO_Mom_Soll 1022 "Init" 1023 "Fehler" ;
VAL_ 129 MO_Mom_Ist 1022 "Init" 1023 "Fehler" ;
VAL_ 129 MO_Status_Zylabschalt_01 0 "alle_Zylinder_brennen" 1 "mindestens_ein_Zylinder_wurde_abgeschaltet" ;
VAL_ 129 MO_Status_Normalbetrieb_01 0 "kein_Normalbetrieb" 1 "Normalbetrieb_erreicht" ;
VAL_ 129 MO_StartStopp_Status 0 "System_in_diesem_KL15_Zyklus_nicht_verfuegbar" 1 "System_aktiv_keine_Freigabe_durch_StartStop_Koordinator" 2 "System_aktiv_alle_Freigaben_liegen_vor" 3 "System_aktiv_mindestens_eine_Freigabe_fehlt" ;
VAL_ 129 MO_StartStopp_Motorstopp 0 "Motor_Stop_inaktiv" 1 "Motor_Stop_aktiv" ;
VAL_ 129 MO_StartStopp_Wiederstart 0 "Wiederstart_inaktiv" 1 "Wiederstart_aktiv" ;
VAL_ 129 MO_Ext_E_Fahrt_aktiv 0 "Rueckmeldung_E_Taster_aus" 1 "Rueckmeldung_E_Taster_ein" ;
VAL_ 129 MO_Gangposition 0 "Gang_N" 1 "Gang_1" 2 "Gang_2" 3 "Gang_3" 4 "Gang_4" 5 "Gang_5" 6 "Gang_6" 7 "Gang_7" 8 "Gang_8" 10 "Automat_Vorwaerts_S" 11 "Automat_Vorwaerts_D/E" 12 "Zwischenstellung" 13 "Gang_R" 14 "Istgang_nicht_definiert" 15 "Fehler" ;
VAL_ 129 MO_StartStopp_Fahrerwunsch 0 "Init" 1 "Stoppverbot_durch_Fahrer" 2 "Stoppfreigabe_durch_Fahrer" 3 "Stoppanforderung_durch_Fahrer" ;
VAL_ 129 MO_StartStopp_StoppVorbereitung 0 "Motorstopp_nicht_in_Vorbereitung" 1 "Motorstopp_in_Vorbereitung" ;
VAL_ 261 MO_QBit_Fahrpedalwerte_01 0 "gueltiger_Wert" 1 "Ersatz_Init_oder_Fehlerwert" ;
VAL_ 261 MO_QBit_Motormomente 0 "gueltiger_Wert" 1 "Ersatz_Init_oder_Fehlerwert" ;
VAL_ 261 MO_QBit_Fahrer_bremst 0 "gueltiger_Wert" 1 "Ersatz_Init_oder_Fehlerwert" ;
VAL_ 261 MO_QBit_Drehzahl_01 0 "gueltiger_Wert" 1 "Ersatz_Init_oder_Fehlerwert" ;
VAL_ 261 MO_Drehzahl_01 65535 "Fehler" ;
VAL_ 261 MO_Moment_im_Leerlauf 0 "kein_Leergas" 1 "Leergas" ;
VAL_ 261 MO_Interlock 0 "Interlockschalter_nicht_betaetigt" 1 "Interlockschalter_betaetigt" ;
VAL_ 261 MO_BLS 0 "kein_Bremsen" 1 "Bremse_betaetigt" ;
VAL_ 261 MO_Fahrer_bremst 0 "kein_Bremsen" 1 "Bremse_betaetigt" ;
VAL_ 261 MO_Konsistenz_Bremsped 0 "Bremspedalinformation_plausibel" 1 "Bremspedalinformation_unplausibel" ;
VAL_ 261 MO_Kuppl_schalter 0 "Schalter_sagt_ausgekuppelt" 1 "Schalter_sagt_eingekuppelt" ;
VAL_ 261 MO_Timeout_ESP 0 "Empfang_iO" 1 "Timeout" ;
VAL_ 261 MO_Motor_laeuft 0 "Motor_laeuft_nicht" 1 "Motor_laeuft_autark_und_stabil_und_darf_mechanisch_belastet_werden" ;
VAL_ 261 MO_Solldrehz_Leerlauf 255 "Fehler" ;
VAL_ 261 MO_Fahrpedalrohwert_01 255 "Fehler" ;
VAL_ 261 MO_erste_Ungenauschwelle 0 "genau" 1 "Momente ungenauer >8%" ;
VAL_ 261 MO_QBit_Stressfaktor 0 "gueltiger_Wert" 1 "Ersatz_Init_oder_Fehlerwert" ;
VAL_ 263 MO_rel_Ladedruck 255 "Fehler" ;
VAL_ 263 MO_Istgang 0 "kein_Gang_eingelegt" 1 "Gang_1" 2 "Gang_2" 3 "Gang_3" 4 "Gang_4" 5 "Gang_5" 6 "Gang_6" 7 "Gang_7" 8 "Gang_8" 9 "Gang_9" ;
VAL_ 263 MO_Sollgang 0 "keine_Empfehlung" 1 "Gang_1" 2 "Gang_2" 3 "Gang_3" 4 "Gang_4" 5 "Gang_5" 6 "Gang_6" 7 "Gang_7" 8 "Gang_8" 9 "Gang_9" ;
VAL_ 263 MO_Oeldruck 254 "Init" 255 "Fehler" ;
VAL_ 263 MO_Anzeigedrehz 4095 "Fehler" ;
VAL_ 263 MO_Effizienzmodus 0 "nicht_im_Effizienz_Modus" 1 "Effizienz_Modus" ;
VAL_ 263 MO_Schaltempf_verfbar 0 "nicht_verfuegbar" 1 "verfuegbar" ;
VAL_ 263 MO_Ladedruck 511 "Fehler" ;
VAL_ 263 MO_KVS_Ueberlauf 0 "kein Ueberlauf" 1 "Kraftstoffverbrauchsignale mindestens 1x übergelaufen" ;
